VERSION ""

NS_ :

BS_:

BU_:

BO_ 2364704766 HVESP14MS1: 8 Vector__XXX
 SG_ Hvesp14Module1OperationalStatus : 0|2@1+ (1,0) [0|3] "" Vector__XXX
 SG_ Hvesp14Module2OperationalStatus : 2|2@1+ (1,0) [0|3] "" Vector__XXX
 SG_ Hvesp14Module3OperationalStatus : 4|2@1+ (1,0) [0|3] "" Vector__XXX
 SG_ Hvesp14Module4OperationalStatus : 6|2@1+ (1,0) [0|3] "" Vector__XXX
 SG_ Hvesp14Module5OperationalStatus : 8|2@1+ (1,0) [0|3] "" Vector__XXX
 SG_ Hvesp14Module6OperationalStatus : 10|2@1+ (1,0) [0|3] "" Vector__XXX
 SG_ Hvesp14Module7OperationalStatus : 12|2@1+ (1,0) [0|3] "" Vector__XXX
 SG_ Hvesp14Module8OperationalStatus : 14|2@1+ (1,0) [0|3] "" Vector__XXX
 SG_ Hvesp14Module9OperationalStatus : 16|2@1+ (1,0) [0|3] "" Vector__XXX
 SG_ Hvsp14Mdl10OprtnlStts : 18|2@1+ (1,0) [0|3] "" Vector__XXX
 SG_ Hvsp14Mdl11OprtnlStts : 20|2@1+ (1,0) [0|3] "" Vector__XXX
 SG_ Hvsp14Mdl12OprtnlStts : 22|2@1+ (1,0) [0|3] "" Vector__XXX
 SG_ Hvsp14Mdl13OprtnlStts : 24|2@1+ (1,0) [0|3] "" Vector__XXX
 SG_ Hvsp14Mdl14OprtnlStts : 26|2@1+ (1,0) [0|3] "" Vector__XXX
 SG_ Hvsp14Mdl15OprtnlStts : 28|2@1+ (1,0) [0|3] "" Vector__XXX
 SG_ Hvsp14Mdl16OprtnlStts : 30|2@1+ (1,0) [0|3] "" Vector__XXX
 SG_ Hvsp14Mdl17OprtnlStts : 32|2@1+ (1,0) [0|3] "" Vector__XXX
 SG_ Hvsp14Mdl18OprtnlStts : 34|2@1+ (1,0) [0|3] "" Vector__XXX
 SG_ Hvsp14Mdl19OprtnlStts : 36|2@1+ (1,0) [0|3] "" Vector__XXX
 SG_ Hvsp14Mdl20OprtnlStts : 38|2@1+ (1,0) [0|3] "" Vector__XXX
 SG_ Hvsp14Mdl21OprtnlStts : 40|2@1+ (1,0) [0|3] "" Vector__XXX
 SG_ Hvsp14Mdl22OprtnlStts : 42|2@1+ (1,0) [0|3] "" Vector__XXX
 SG_ Hvsp14Mdl23OprtnlStts : 44|2@1+ (1,0) [0|3] "" Vector__XXX
 SG_ Hvsp14Mdl24OprtnlStts : 46|2@1+ (1,0) [0|3] "" Vector__XXX
 SG_ Hvsp14Mdl25OprtnlStts : 48|2@1+ (1,0) [0|3] "" Vector__XXX
 SG_ Hvsp14Mdl26OprtnlStts : 50|2@1+ (1,0) [0|3] "" Vector__XXX
 SG_ Hvsp14Mdl27OprtnlStts : 52|2@1+ (1,0) [0|3] "" Vector__XXX
 SG_ Hvsp14Mdl28OprtnlStts : 54|2@1+ (1,0) [0|3] "" Vector__XXX
 SG_ Hvsp14Mdl29OprtnlStts : 56|2@1+ (1,0) [0|3] "" Vector__XXX
 SG_ Hvsp14Mdl30OprtnlStts : 58|2@1+ (1,0) [0|3] "" Vector__XXX
 SG_ Hvsp14Mdl31OprtnlStts : 60|2@1+ (1,0) [0|3] "" Vector__XXX
 SG_ Hvsp14Mdl32OprtnlStts : 62|2@1+ (1,0) [0|3] "" Vector__XXX

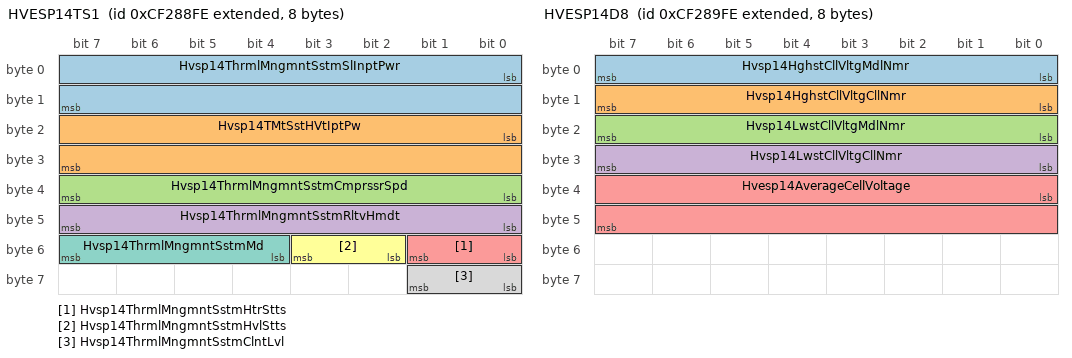
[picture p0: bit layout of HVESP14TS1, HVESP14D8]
BO_ 2364705022 HVESP14TS1: 8 Vector__XXX
 SG_ Hvsp14ThrmlMngmntSstmSlInptPwr : 0|16@1+ (0.5,0) [0|32127.5] "W" Vector__XXX
 SG_ Hvsp14TMtSstHVtIptPw : 16|16@1+ (0.5,0) [0|32127.5] "W" Vector__XXX
 SG_ Hvsp14ThrmlMngmntSstmCmprssrSpd : 32|8@1+ (32,0) [0|8000] "rpm" Vector__XXX
 SG_ Hvsp14ThrmlMngmntSstmRltvHmdt : 40|8@1+ (0.4,0) [0|100] "%" Vector__XXX
 SG_ Hvsp14ThrmlMngmntSstmHtrStts : 48|2@1+ (1,0) [0|3] "" Vector__XXX
 SG_ Hvsp14ThrmlMngmntSstmHvlStts : 50|2@1+ (1,0) [0|3] "" Vector__XXX
 SG_ Hvsp14ThrmlMngmntSstmMd : 52|4@1+ (1,0) [0|15] "" Vector__XXX
 SG_ Hvsp14ThrmlMngmntSstmClntLvl : 56|2@1+ (1,0) [0|3] "" Vector__XXX

BO_ 2364705278 HVESP14D8: 8 Vector__XXX
 SG_ Hvsp14HghstCllVltgMdlNmr : 0|8@1+ (1,0) [0|250] "count" Vector__XXX
 SG_ Hvsp14HghstCllVltgCllNmr : 8|8@1+ (1,0) [0|250] "count" Vector__XXX
 SG_ Hvsp14LwstCllVltgMdlNmr : 16|8@1+ (1,0) [0|250] "count" Vector__XXX
 SG_ Hvsp14LwstCllVltgCllNmr : 24|8@1+ (1,0) [0|250] "count" Vector__XXX
 SG_ Hvesp14AverageCellVoltage : 32|16@1+ (0.001,0) [0|64.255] "V" Vector__XXX

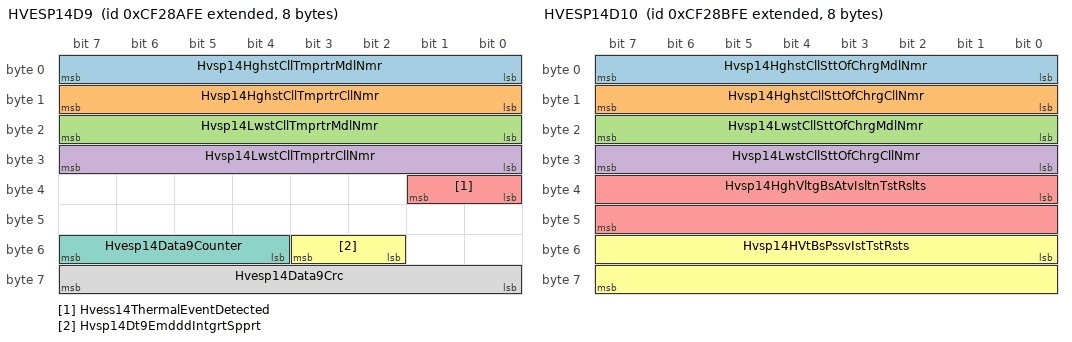
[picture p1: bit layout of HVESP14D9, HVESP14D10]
BO_ 2364705534 HVESP14D9: 8 Vector__XXX
 SG_ Hvsp14HghstCllTmprtrMdlNmr : 0|8@1+ (1,0) [0|250] "count" Vector__XXX
 SG_ Hvsp14HghstCllTmprtrCllNmr : 8|8@1+ (1,0) [0|250] "count" Vector__XXX
 SG_ Hvsp14LwstCllTmprtrMdlNmr : 16|8@1+ (1,0) [0|250] "count" Vector__XXX
 SG_ Hvsp14LwstCllTmprtrCllNmr : 24|8@1+ (1,0) [0|250] "count" Vector__XXX
 SG_ Hvess14ThermalEventDetected : 32|2@1+ (1,0) [0|3] "" Vector__XXX
 SG_ Hvsp14Dt9EmdddIntgrtSpprt : 50|2@1+ (1,0) [0|3] "" Vector__XXX
 SG_ Hvesp14Data9Counter : 52|4@1+ (1,0) [0|15] "" Vector__XXX
 SG_ Hvesp14Data9Crc : 56|8@1+ (1,0) [0|250] "count" Vector__XXX

BO_ 2364705790 HVESP14D10: 8 Vector__XXX
 SG_ Hvsp14HghstCllSttOfChrgMdlNmr : 0|8@1+ (1,0) [0|250] "count" Vector__XXX
 SG_ Hvsp14HghstCllSttOfChrgCllNmr : 8|8@1+ (1,0) [0|250] "count" Vector__XXX
 SG_ Hvsp14LwstCllSttOfChrgMdlNmr : 16|8@1+ (1,0) [0|250] "count" Vector__XXX
 SG_ Hvsp14LwstCllSttOfChrgCllNmr : 24|8@1+ (1,0) [0|250] "count" Vector__XXX
 SG_ Hvsp14HghVltgBsAtvIsltnTstRslts : 32|16@1+ (0.1,0) [0|6425.5] "OhmPerV" Vector__XXX
 SG_ Hvsp14HVtBsPssvIstTstRsts : 48|16@1+ (0.1,0) [0|6425.5] "OhmPerV" Vector__XXX

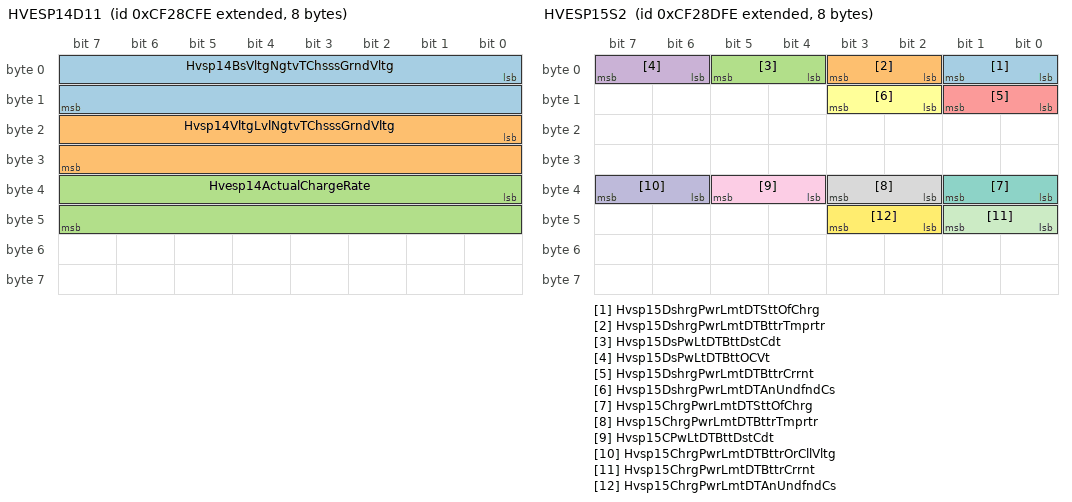
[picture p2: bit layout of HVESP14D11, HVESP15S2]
BO_ 2364706046 HVESP14D11: 8 Vector__XXX
 SG_ Hvsp14BsVltgNgtvTChsssGrndVltg : 0|16@1+ (0.05,0) [0|3212.75] "V" Vector__XXX
 SG_ Hvsp14VltgLvlNgtvTChsssGrndVltg : 16|16@1+ (0.05,0) [0|3212.75] "V" Vector__XXX
 SG_ Hvesp14ActualChargeRate : 32|16@1+ (0.05,0) [0|3212.75] "kW" Vector__XXX

BO_ 2364706302 HVESP15S2: 8 Vector__XXX
 SG_ Hvsp15DshrgPwrLmtDTSttOfChrg : 0|2@1+ (1,0) [0|3] "" Vector__XXX
 SG_ Hvsp15DshrgPwrLmtDTBttrTmprtr : 2|2@1+ (1,0) [0|3] "" Vector__XXX
 SG_ Hvsp15DsPwLtDTBttDstCdt : 4|2@1+ (1,0) [0|3] "" Vector__XXX
 SG_ Hvsp15DsPwLtDTBttOCVt : 6|2@1+ (1,0) [0|3] "" Vector__XXX
 SG_ Hvsp15DshrgPwrLmtDTBttrCrrnt : 8|2@1+ (1,0) [0|3] "" Vector__XXX
 SG_ Hvsp15DshrgPwrLmtDTAnUndfndCs : 10|2@1+ (1,0) [0|3] "" Vector__XXX
 SG_ Hvsp15ChrgPwrLmtDTSttOfChrg : 32|2@1+ (1,0) [0|3] "" Vector__XXX
 SG_ Hvsp15ChrgPwrLmtDTBttrTmprtr : 34|2@1+ (1,0) [0|3] "" Vector__XXX
 SG_ Hvsp15CPwLtDTBttDstCdt : 36|2@1+ (1,0) [0|3] "" Vector__XXX
 SG_ Hvsp15ChrgPwrLmtDTBttrOrCllVltg : 38|2@1+ (1,0) [0|3] "" Vector__XXX
 SG_ Hvsp15ChrgPwrLmtDTBttrCrrnt : 40|2@1+ (1,0) [0|3] "" Vector__XXX
 SG_ Hvsp15ChrgPwrLmtDTAnUndfndCs : 42|2@1+ (1,0) [0|3] "" Vector__XXX

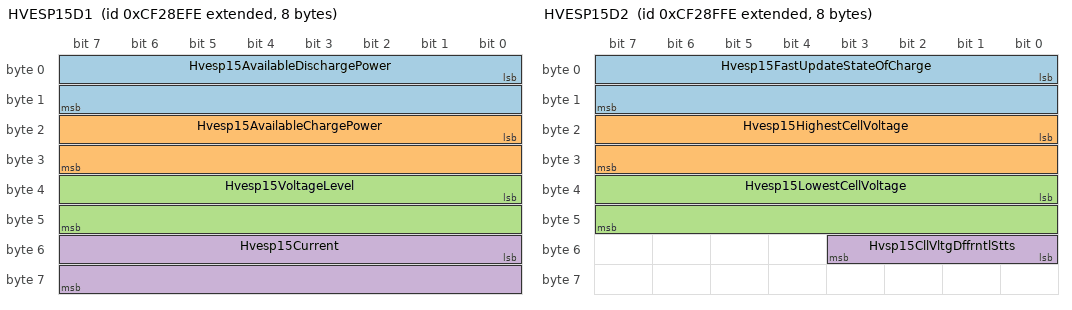
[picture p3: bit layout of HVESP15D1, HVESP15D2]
BO_ 2364706558 HVESP15D1: 8 Vector__XXX
 SG_ Hvesp15AvailableDischargePower : 0|16@1+ (0.05,0) [0|3212.75] "kW" Vector__XXX
 SG_ Hvesp15AvailableChargePower : 16|16@1+ (0.05,0) [0|3212.75] "kW" Vector__XXX
 SG_ Hvesp15VoltageLevel : 32|16@1+ (0.05,0) [0|3212.75] "V" Vector__XXX
 SG_ Hvesp15Current : 48|16@1+ (0.05,-1600) [-1600|1612.75] "A" Vector__XXX

BO_ 2364706814 HVESP15D2: 8 Vector__XXX
 SG_ Hvesp15FastUpdateStateOfCharge : 0|16@1+ (0.0015625,0) [0|100.3984375] "%" Vector__XXX
 SG_ Hvesp15HighestCellVoltage : 16|16@1+ (0.001,0) [0|64.255] "V" Vector__XXX
 SG_ Hvesp15LowestCellVoltage : 32|16@1+ (0.001,0) [0|64.255] "V" Vector__XXX
 SG_ Hvsp15CllVltgDffrntlStts : 48|4@1+ (1,0) [0|15] "" Vector__XXX

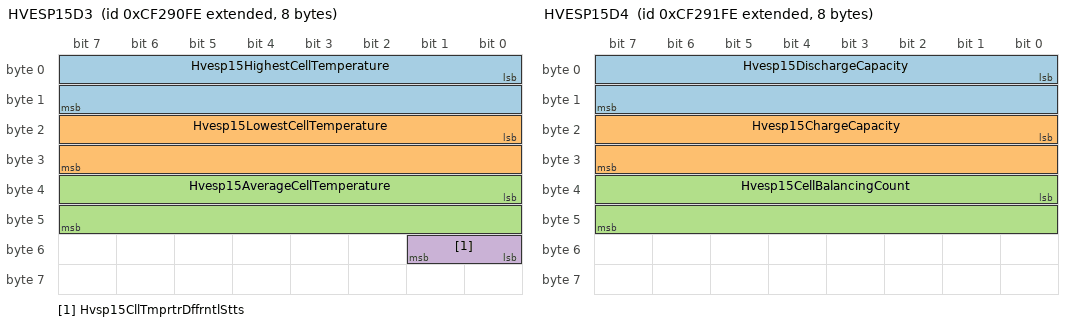
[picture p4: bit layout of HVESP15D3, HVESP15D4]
BO_ 2364707070 HVESP15D3: 8 Vector__XXX
 SG_ Hvesp15HighestCellTemperature : 0|16@1+ (0.03125,-273) [-273|1734.96875] "degC" Vector__XXX
 SG_ Hvesp15LowestCellTemperature : 16|16@1+ (0.03125,-273) [-273|1734.96875] "degC" Vector__XXX
 SG_ Hvesp15AverageCellTemperature : 32|16@1+ (0.03125,-273) [-273|1734.96875] "degC" Vector__XXX
 SG_ Hvsp15CllTmprtrDffrntlStts : 48|2@1+ (1,0) [0|3] "" Vector__XXX

BO_ 2364707326 HVESP15D4: 8 Vector__XXX
 SG_ Hvesp15DischargeCapacity : 0|16@1+ (0.01,0) [0|642.55] "Ah" Vector__XXX
 SG_ Hvesp15ChargeCapacity : 16|16@1+ (0.01,0) [0|642.55] "Ah" Vector__XXX
 SG_ Hvesp15CellBalancingCount : 32|16@1+ (1,0) [0|64255] "count" Vector__XXX

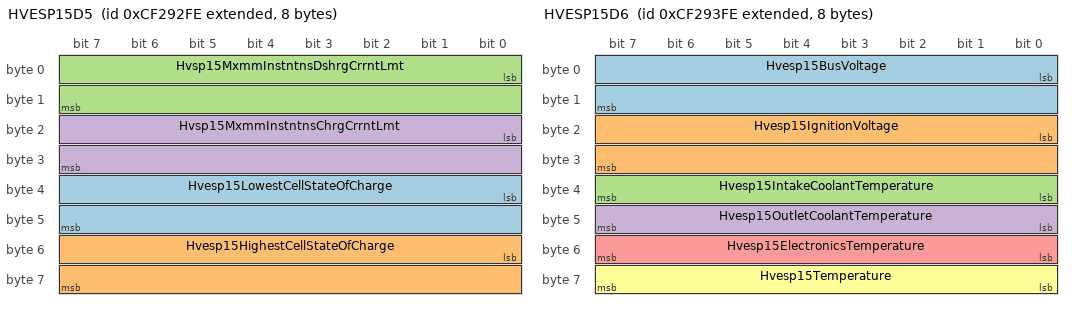
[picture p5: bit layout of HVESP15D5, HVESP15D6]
BO_ 2364707582 HVESP15D5: 8 Vector__XXX
 SG_ Hvesp15LowestCellStateOfCharge : 32|16@1+ (0.0015625,0) [0|100.3984375] "%" Vector__XXX
 SG_ Hvesp15HighestCellStateOfCharge : 48|16@1+ (0.0015625,0) [0|100.3984375] "%" Vector__XXX
 SG_ Hvsp15MxmmInstntnsDshrgCrrntLmt : 0|16@1+ (0.05,-1600) [-1600|0] "A" Vector__XXX
 SG_ Hvsp15MxmmInstntnsChrgCrrntLmt : 16|16@1+ (0.05,-1600) [0|1612.75] "A" Vector__XXX

BO_ 2364707838 HVESP15D6: 8 Vector__XXX
 SG_ Hvesp15BusVoltage : 0|16@1+ (0.05,0) [0|3212.75] "V" Vector__XXX
 SG_ Hvesp15IgnitionVoltage : 16|16@1+ (0.01,0) [0|642.55] "V" Vector__XXX
 SG_ Hvesp15IntakeCoolantTemperature : 32|8@1+ (1,-40) [-40|210] "degC" Vector__XXX
 SG_ Hvesp15OutletCoolantTemperature : 40|8@1+ (1,-40) [-40|210] "degC" Vector__XXX
 SG_ Hvesp15ElectronicsTemperature : 48|8@1+ (1,-40) [-40|210] "degC" Vector__XXX
 SG_ Hvesp15Temperature : 56|8@1+ (1,-40) [-40|210] "degC" Vector__XXX

BO_ 2364708094 HVESP15S1: 8 Vector__XXX
 SG_ Hvsp15HghVltgBsPstvCnttrStt : 0|2@1+ (1,0) [0|3] "" Vector__XXX
 SG_ Hvsp15HghVltgBsNgtvCnttrStt : 2|2@1+ (1,0) [0|3] "" Vector__XXX
 SG_ Hvsp15HghVltgBsDsnntFrwrnng : 4|4@1+ (1,0) [0|15] "" Vector__XXX
 SG_ Hvsp15HghVltgBsPrChrgRlStt : 8|2@1+ (1,0) [0|3] "" Vector__XXX
 SG_ Hvsp15CntrOfPkCnttrStt : 10|2@1+ (1,0) [0|3] "" Vector__XXX
 SG_ Hvsp15HghVltgBsAtvIsltnTstStts : 12|4@1+ (1,0) [0|15] "" Vector__XXX
 SG_ Hvsp15HghVltgBsPssvIsltnTstStts : 16|4@1+ (1,0) [0|15] "" Vector__XXX
 SG_ Hvesp15HvilStatus : 20|2@1+ (1,0) [0|3] "" Vector__XXX
 SG_ Hvesp15InertiaSwitchStatus : 22|2@1+ (1,0) [0|3] "" Vector__XXX
 SG_ Hvesp15StateOfChargeStatus : 24|4@1+ (1,0) [0|15] "" Vector__XXX
 SG_ Hvesp15CellBalanceStatus : 28|2@1+ (1,0) [0|3] "" Vector__XXX
 SG_ Hvesp15CellBalancingActive : 30|2@1+ (1,0) [0|3] "" Vector__XXX
 SG_ Hvesp15InternalChargerStatus : 32|2@1+ (1,0) [0|3] "" Vector__XXX
 SG_ Hvsp15HghVltgBsCnntnStts : 40|4@1+ (1,0) [0|15] "" Vector__XXX
 SG_ Hvesp15OperationalStatus : 44|4@1+ (1,0) [0|15] "" Vector__XXX
 SG_ Hvesp15Status1Counter : 52|4@1+ (1,0) [0|15] "" Vector__XXX
 SG_ Hvesp15Status1Crc : 56|8@1+ (1,0) [0|250] "count" Vector__XXX

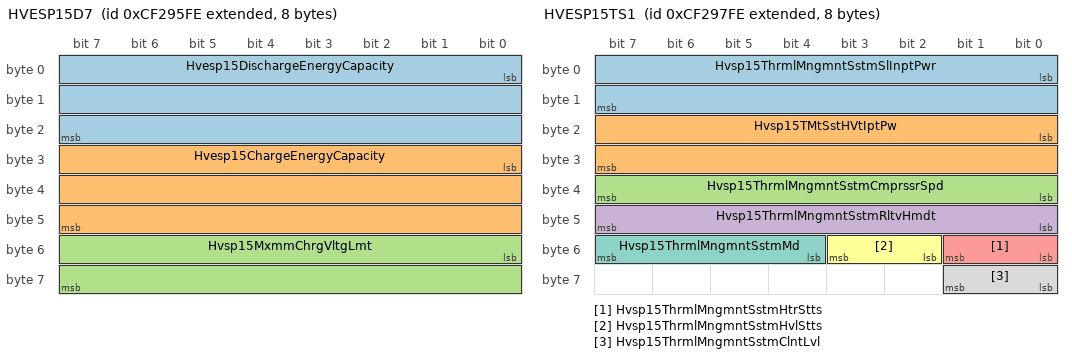
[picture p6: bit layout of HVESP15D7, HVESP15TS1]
BO_ 2364708350 HVESP15D7: 8 Vector__XXX
 SG_ Hvesp15DischargeEnergyCapacity : 0|24@1+ (0.001,0) [0|16449.535] "kWh" Vector__XXX
 SG_ Hvesp15ChargeEnergyCapacity : 24|24@1+ (0.001,0) [0|16449.535] "kWh" Vector__XXX
 SG_ Hvsp15MxmmChrgVltgLmt : 48|16@1+ (0.05,0) [0|3212.75] "V" Vector__XXX

BO_ 2364708606 HVESP15MS1: 8 Vector__XXX
 SG_ Hvesp15Module1OperationalStatus : 0|2@1+ (1,0) [0|3] "" Vector__XXX
 SG_ Hvesp15Module2OperationalStatus : 2|2@1+ (1,0) [0|3] "" Vector__XXX
 SG_ Hvesp15Module3OperationalStatus : 4|2@1+ (1,0) [0|3] "" Vector__XXX
 SG_ Hvesp15Module4OperationalStatus : 6|2@1+ (1,0) [0|3] "" Vector__XXX
 SG_ Hvesp15Module5OperationalStatus : 8|2@1+ (1,0) [0|3] "" Vector__XXX
 SG_ Hvesp15Module6OperationalStatus : 10|2@1+ (1,0) [0|3] "" Vector__XXX
 SG_ Hvesp15Module7OperationalStatus : 12|2@1+ (1,0) [0|3] "" Vector__XXX
 SG_ Hvesp15Module8OperationalStatus : 14|2@1+ (1,0) [0|3] "" Vector__XXX
 SG_ Hvesp15Module9OperationalStatus : 16|2@1+ (1,0) [0|3] "" Vector__XXX
 SG_ Hvsp15Mdl10OprtnlStts : 18|2@1+ (1,0) [0|3] "" Vector__XXX
 SG_ Hvsp15Mdl11OprtnlStts : 20|2@1+ (1,0) [0|3] "" Vector__XXX
 SG_ Hvsp15Mdl12OprtnlStts : 22|2@1+ (1,0) [0|3] "" Vector__XXX
 SG_ Hvsp15Mdl13OprtnlStts : 24|2@1+ (1,0) [0|3] "" Vector__XXX
 SG_ Hvsp15Mdl14OprtnlStts : 26|2@1+ (1,0) [0|3] "" Vector__XXX
 SG_ Hvsp15Mdl15OprtnlStts : 28|2@1+ (1,0) [0|3] "" Vector__XXX
 SG_ Hvsp15Mdl16OprtnlStts : 30|2@1+ (1,0) [0|3] "" Vector__XXX
 SG_ Hvsp15Mdl17OprtnlStts : 32|2@1+ (1,0) [0|3] "" Vector__XXX
 SG_ Hvsp15Mdl18OprtnlStts : 34|2@1+ (1,0) [0|3] "" Vector__XXX
 SG_ Hvsp15Mdl19OprtnlStts : 36|2@1+ (1,0) [0|3] "" Vector__XXX
 SG_ Hvsp15Mdl20OprtnlStts : 38|2@1+ (1,0) [0|3] "" Vector__XXX
 SG_ Hvsp15Mdl21OprtnlStts : 40|2@1+ (1,0) [0|3] "" Vector__XXX
 SG_ Hvsp15Mdl22OprtnlStts : 42|2@1+ (1,0) [0|3] "" Vector__XXX
 SG_ Hvsp15Mdl23OprtnlStts : 44|2@1+ (1,0) [0|3] "" Vector__XXX
 SG_ Hvsp15Mdl24OprtnlStts : 46|2@1+ (1,0) [0|3] "" Vector__XXX
 SG_ Hvsp15Mdl25OprtnlStts : 48|2@1+ (1,0) [0|3] "" Vector__XXX
 SG_ Hvsp15Mdl26OprtnlStts : 50|2@1+ (1,0) [0|3] "" Vector__XXX
 SG_ Hvsp15Mdl27OprtnlStts : 52|2@1+ (1,0) [0|3] "" Vector__XXX
 SG_ Hvsp15Mdl28OprtnlStts : 54|2@1+ (1,0) [0|3] "" Vector__XXX
 SG_ Hvsp15Mdl29OprtnlStts : 56|2@1+ (1,0) [0|3] "" Vector__XXX
 SG_ Hvsp15Mdl30OprtnlStts : 58|2@1+ (1,0) [0|3] "" Vector__XXX
 SG_ Hvsp15Mdl31OprtnlStts : 60|2@1+ (1,0) [0|3] "" Vector__XXX
 SG_ Hvsp15Mdl32OprtnlStts : 62|2@1+ (1,0) [0|3] "" Vector__XXX

BO_ 2364708862 HVESP15TS1: 8 Vector__XXX
 SG_ Hvsp15ThrmlMngmntSstmSlInptPwr : 0|16@1+ (0.5,0) [0|32127.5] "W" Vector__XXX
 SG_ Hvsp15TMtSstHVtIptPw : 16|16@1+ (0.5,0) [0|32127.5] "W" Vector__XXX
 SG_ Hvsp15ThrmlMngmntSstmCmprssrSpd : 32|8@1+ (32,0) [0|8000] "rpm" Vector__XXX
 SG_ Hvsp15ThrmlMngmntSstmRltvHmdt : 40|8@1+ (0.4,0) [0|100] "%" Vector__XXX
 SG_ Hvsp15ThrmlMngmntSstmHtrStts : 48|2@1+ (1,0) [0|3] "" Vector__XXX
 SG_ Hvsp15ThrmlMngmntSstmHvlStts : 50|2@1+ (1,0) [0|3] "" Vector__XXX
 SG_ Hvsp15ThrmlMngmntSstmMd : 52|4@1+ (1,0) [0|15] "" Vector__XXX
 SG_ Hvsp15ThrmlMngmntSstmClntLvl : 56|2@1+ (1,0) [0|3] "" Vector__XXX

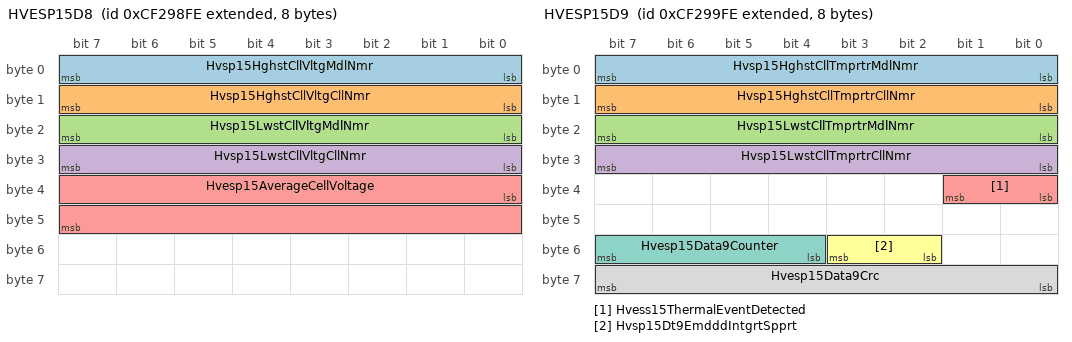
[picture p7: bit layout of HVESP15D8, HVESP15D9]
BO_ 2364709118 HVESP15D8: 8 Vector__XXX
 SG_ Hvsp15HghstCllVltgMdlNmr : 0|8@1+ (1,0) [0|250] "count" Vector__XXX
 SG_ Hvsp15HghstCllVltgCllNmr : 8|8@1+ (1,0) [0|250] "count" Vector__XXX
 SG_ Hvsp15LwstCllVltgMdlNmr : 16|8@1+ (1,0) [0|250] "count" Vector__XXX
 SG_ Hvsp15LwstCllVltgCllNmr : 24|8@1+ (1,0) [0|250] "count" Vector__XXX
 SG_ Hvesp15AverageCellVoltage : 32|16@1+ (0.001,0) [0|64.255] "V" Vector__XXX

BO_ 2364709374 HVESP15D9: 8 Vector__XXX
 SG_ Hvsp15HghstCllTmprtrMdlNmr : 0|8@1+ (1,0) [0|250] "count" Vector__XXX
 SG_ Hvsp15HghstCllTmprtrCllNmr : 8|8@1+ (1,0) [0|250] "count" Vector__XXX
 SG_ Hvsp15LwstCllTmprtrMdlNmr : 16|8@1+ (1,0) [0|250] "count" Vector__XXX
 SG_ Hvsp15LwstCllTmprtrCllNmr : 24|8@1+ (1,0) [0|250] "count" Vector__XXX
 SG_ Hvess15ThermalEventDetected : 32|2@1+ (1,0) [0|3] "" Vector__XXX
 SG_ Hvsp15Dt9EmdddIntgrtSpprt : 50|2@1+ (1,0) [0|3] "" Vector__XXX
 SG_ Hvesp15Data9Counter : 52|4@1+ (1,0) [0|15] "" Vector__XXX
 SG_ Hvesp15Data9Crc : 56|8@1+ (1,0) [0|250] "count" Vector__XXX

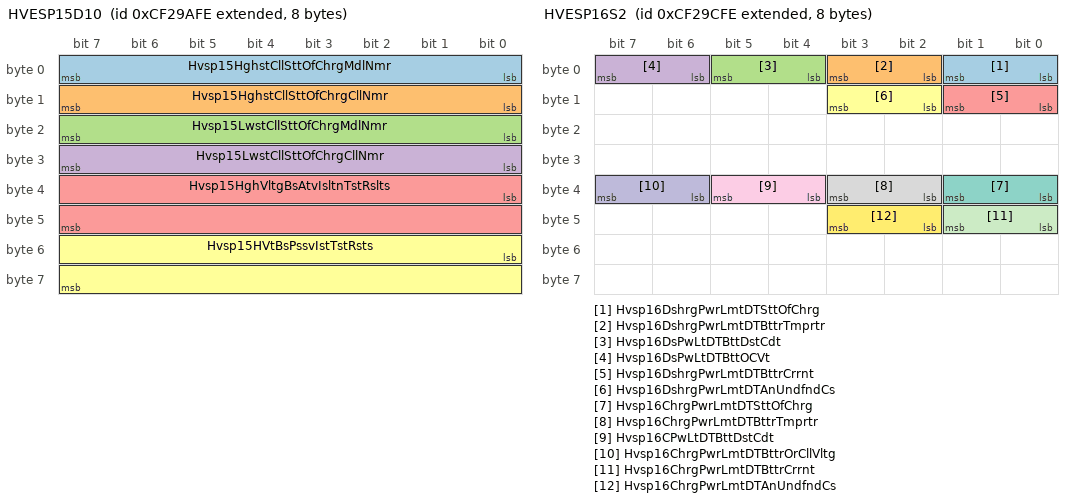
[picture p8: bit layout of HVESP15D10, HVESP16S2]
BO_ 2364709630 HVESP15D10: 8 Vector__XXX
 SG_ Hvsp15HghstCllSttOfChrgMdlNmr : 0|8@1+ (1,0) [0|250] "count" Vector__XXX
 SG_ Hvsp15HghstCllSttOfChrgCllNmr : 8|8@1+ (1,0) [0|250] "count" Vector__XXX
 SG_ Hvsp15LwstCllSttOfChrgMdlNmr : 16|8@1+ (1,0) [0|250] "count" Vector__XXX
 SG_ Hvsp15LwstCllSttOfChrgCllNmr : 24|8@1+ (1,0) [0|250] "count" Vector__XXX
 SG_ Hvsp15HghVltgBsAtvIsltnTstRslts : 32|16@1+ (0.1,0) [0|6425.5] "OhmPerV" Vector__XXX
 SG_ Hvsp15HVtBsPssvIstTstRsts : 48|16@1+ (0.1,0) [0|6425.5] "OhmPerV" Vector__XXX

BO_ 2364709886 HVESP15D11: 8 Vector__XXX
 SG_ Hvsp15BsVltgNgtvTChsssGrndVltg : 0|16@1+ (0.05,0) [0|3212.75] "V" Vector__XXX
 SG_ Hvsp15VltgLvlNgtvTChsssGrndVltg : 16|16@1+ (0.05,0) [0|3212.75] "V" Vector__XXX
 SG_ Hvesp15ActualChargeRate : 32|16@1+ (0.05,0) [0|3212.75] "kW" Vector__XXX

BO_ 2364710142 HVESP16S2: 8 Vector__XXX
 SG_ Hvsp16DshrgPwrLmtDTSttOfChrg : 0|2@1+ (1,0) [0|3] "" Vector__XXX
 SG_ Hvsp16DshrgPwrLmtDTBttrTmprtr : 2|2@1+ (1,0) [0|3] "" Vector__XXX
 SG_ Hvsp16DsPwLtDTBttDstCdt : 4|2@1+ (1,0) [0|3] "" Vector__XXX
 SG_ Hvsp16DsPwLtDTBttOCVt : 6|2@1+ (1,0) [0|3] "" Vector__XXX
 SG_ Hvsp16DshrgPwrLmtDTBttrCrrnt : 8|2@1+ (1,0) [0|3] "" Vector__XXX
 SG_ Hvsp16DshrgPwrLmtDTAnUndfndCs : 10|2@1+ (1,0) [0|3] "" Vector__XXX
 SG_ Hvsp16ChrgPwrLmtDTSttOfChrg : 32|2@1+ (1,0) [0|3] "" Vector__XXX
 SG_ Hvsp16ChrgPwrLmtDTBttrTmprtr : 34|2@1+ (1,0) [0|3] "" Vector__XXX
 SG_ Hvsp16CPwLtDTBttDstCdt : 36|2@1+ (1,0) [0|3] "" Vector__XXX
 SG_ Hvsp16ChrgPwrLmtDTBttrOrCllVltg : 38|2@1+ (1,0) [0|3] "" Vector__XXX
 SG_ Hvsp16ChrgPwrLmtDTBttrCrrnt : 40|2@1+ (1,0) [0|3] "" Vector__XXX
 SG_ Hvsp16ChrgPwrLmtDTAnUndfndCs : 42|2@1+ (1,0) [0|3] "" Vector__XXX

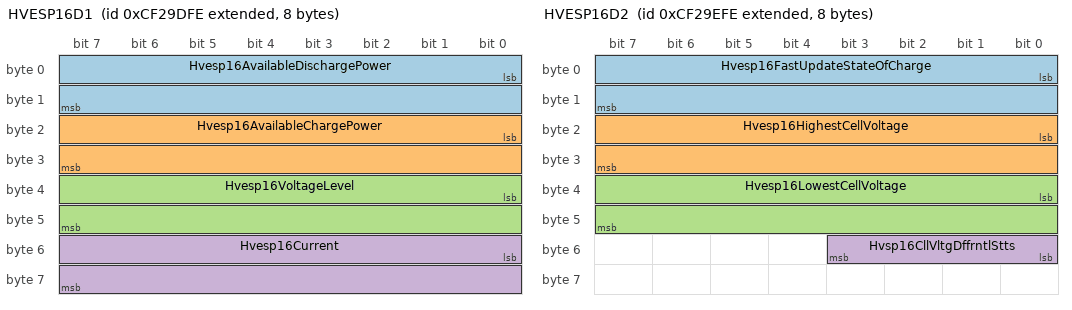
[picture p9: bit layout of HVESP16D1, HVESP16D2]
BO_ 2364710398 HVESP16D1: 8 Vector__XXX
 SG_ Hvesp16AvailableDischargePower : 0|16@1+ (0.05,0) [0|3212.75] "kW" Vector__XXX
 SG_ Hvesp16AvailableChargePower : 16|16@1+ (0.05,0) [0|3212.75] "kW" Vector__XXX
 SG_ Hvesp16VoltageLevel : 32|16@1+ (0.05,0) [0|3212.75] "V" Vector__XXX
 SG_ Hvesp16Current : 48|16@1+ (0.05,-1600) [-1600|1612.75] "A" Vector__XXX

BO_ 2364710654 HVESP16D2: 8 Vector__XXX
 SG_ Hvesp16FastUpdateStateOfCharge : 0|16@1+ (0.0015625,0) [0|100.3984375] "%" Vector__XXX
 SG_ Hvesp16HighestCellVoltage : 16|16@1+ (0.001,0) [0|64.255] "V" Vector__XXX
 SG_ Hvesp16LowestCellVoltage : 32|16@1+ (0.001,0) [0|64.255] "V" Vector__XXX
 SG_ Hvsp16CllVltgDffrntlStts : 48|4@1+ (1,0) [0|15] "" Vector__XXX

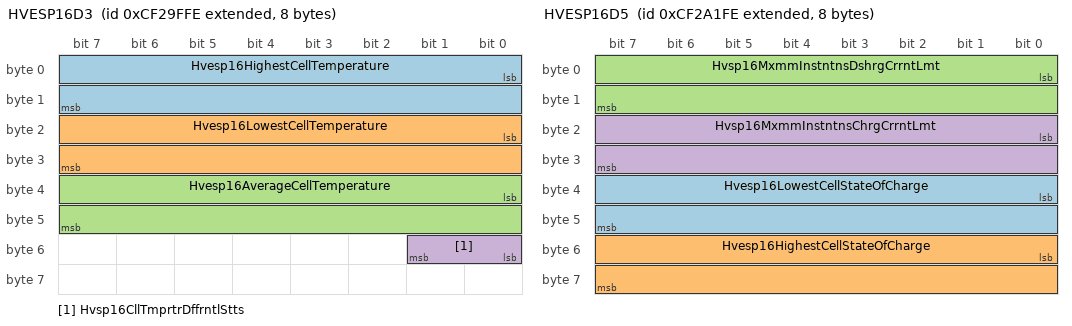
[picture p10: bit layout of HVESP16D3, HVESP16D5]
BO_ 2364710910 HVESP16D3: 8 Vector__XXX
 SG_ Hvesp16HighestCellTemperature : 0|16@1+ (0.03125,-273) [-273|1734.96875] "degC" Vector__XXX
 SG_ Hvesp16LowestCellTemperature : 16|16@1+ (0.03125,-273) [-273|1734.96875] "degC" Vector__XXX
 SG_ Hvesp16AverageCellTemperature : 32|16@1+ (0.03125,-273) [-273|1734.96875] "degC" Vector__XXX
 SG_ Hvsp16CllTmprtrDffrntlStts : 48|2@1+ (1,0) [0|3] "" Vector__XXX

BO_ 2364711166 HVESP16D4: 8 Vector__XXX
 SG_ Hvesp16DischargeCapacity : 0|16@1+ (0.01,0) [0|642.55] "Ah" Vector__XXX
 SG_ Hvesp16ChargeCapacity : 16|16@1+ (0.01,0) [0|642.55] "Ah" Vector__XXX
 SG_ Hvesp16CellBalancingCount : 32|16@1+ (1,0) [0|64255] "count" Vector__XXX

BO_ 2364711422 HVESP16D5: 8 Vector__XXX
 SG_ Hvesp16LowestCellStateOfCharge : 32|16@1+ (0.0015625,0) [0|100.3984375] "%" Vector__XXX
 SG_ Hvesp16HighestCellStateOfCharge : 48|16@1+ (0.0015625,0) [0|100.3984375] "%" Vector__XXX
 SG_ Hvsp16MxmmInstntnsDshrgCrrntLmt : 0|16@1+ (0.05,-1600) [-1600|0] "A" Vector__XXX
 SG_ Hvsp16MxmmInstntnsChrgCrrntLmt : 16|16@1+ (0.05,-1600) [0|1612.75] "A" Vector__XXX

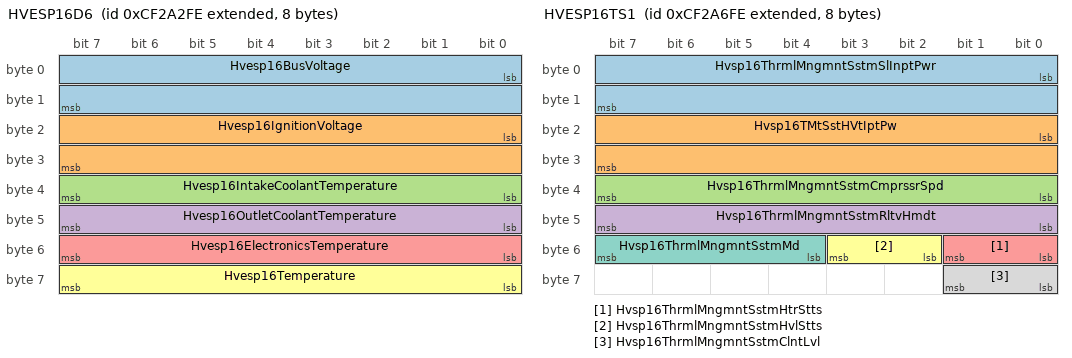
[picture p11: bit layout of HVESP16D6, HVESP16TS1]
BO_ 2364711678 HVESP16D6: 8 Vector__XXX
 SG_ Hvesp16BusVoltage : 0|16@1+ (0.05,0) [0|3212.75] "V" Vector__XXX
 SG_ Hvesp16IgnitionVoltage : 16|16@1+ (0.01,0) [0|642.55] "V" Vector__XXX
 SG_ Hvesp16IntakeCoolantTemperature : 32|8@1+ (1,-40) [-40|210] "degC" Vector__XXX
 SG_ Hvesp16OutletCoolantTemperature : 40|8@1+ (1,-40) [-40|210] "degC" Vector__XXX
 SG_ Hvesp16ElectronicsTemperature : 48|8@1+ (1,-40) [-40|210] "degC" Vector__XXX
 SG_ Hvesp16Temperature : 56|8@1+ (1,-40) [-40|210] "degC" Vector__XXX

BO_ 2364711934 HVESP16S1: 8 Vector__XXX
 SG_ Hvsp16HghVltgBsPstvCnttrStt : 0|2@1+ (1,0) [0|3] "" Vector__XXX
 SG_ Hvsp16HghVltgBsNgtvCnttrStt : 2|2@1+ (1,0) [0|3] "" Vector__XXX
 SG_ Hvsp16HghVltgBsDsnntFrwrnng : 4|4@1+ (1,0) [0|15] "" Vector__XXX
 SG_ Hvsp16HghVltgBsPrChrgRlStt : 8|2@1+ (1,0) [0|3] "" Vector__XXX
 SG_ Hvsp16CntrOfPkCnttrStt : 10|2@1+ (1,0) [0|3] "" Vector__XXX
 SG_ Hvsp16HghVltgBsAtvIsltnTstStts : 12|4@1+ (1,0) [0|15] "" Vector__XXX
 SG_ Hvsp16HghVltgBsPssvIsltnTstStts : 16|4@1+ (1,0) [0|15] "" Vector__XXX
 SG_ Hvesp16HvilStatus : 20|2@1+ (1,0) [0|3] "" Vector__XXX
 SG_ Hvesp16InertiaSwitchStatus : 22|2@1+ (1,0) [0|3] "" Vector__XXX
 SG_ Hvesp16StateOfChargeStatus : 24|4@1+ (1,0) [0|15] "" Vector__XXX
 SG_ Hvesp16CellBalanceStatus : 28|2@1+ (1,0) [0|3] "" Vector__XXX
 SG_ Hvesp16CellBalancingActive : 30|2@1+ (1,0) [0|3] "" Vector__XXX
 SG_ Hvesp16InternalChargerStatus : 32|2@1+ (1,0) [0|3] "" Vector__XXX
 SG_ Hvsp16HghVltgBsCnntnStts : 40|4@1+ (1,0) [0|15] "" Vector__XXX
 SG_ Hvesp16OperationalStatus : 44|4@1+ (1,0) [0|15] "" Vector__XXX
 SG_ Hvesp16Status1Counter : 52|4@1+ (1,0) [0|15] "" Vector__XXX
 SG_ Hvesp16Status1Crc : 56|8@1+ (1,0) [0|250] "count" Vector__XXX

BO_ 2364712190 HVESP16D7: 8 Vector__XXX
 SG_ Hvesp16DischargeEnergyCapacity : 0|24@1+ (0.001,0) [0|16449.535] "kWh" Vector__XXX
 SG_ Hvesp16ChargeEnergyCapacity : 24|24@1+ (0.001,0) [0|16449.535] "kWh" Vector__XXX
 SG_ Hvsp16MxmmChrgVltgLmt : 48|16@1+ (0.05,0) [0|3212.75] "V" Vector__XXX

BO_ 2364712446 HVESP16MS1: 8 Vector__XXX
 SG_ Hvesp16Module1OperationalStatus : 0|2@1+ (1,0) [0|3] "" Vector__XXX
 SG_ Hvesp16Module2OperationalStatus : 2|2@1+ (1,0) [0|3] "" Vector__XXX
 SG_ Hvesp16Module3OperationalStatus : 4|2@1+ (1,0) [0|3] "" Vector__XXX
 SG_ Hvesp16Module4OperationalStatus : 6|2@1+ (1,0) [0|3] "" Vector__XXX
 SG_ Hvesp16Module5OperationalStatus : 8|2@1+ (1,0) [0|3] "" Vector__XXX
 SG_ Hvesp16Module6OperationalStatus : 10|2@1+ (1,0) [0|3] "" Vector__XXX
 SG_ Hvesp16Module7OperationalStatus : 12|2@1+ (1,0) [0|3] "" Vector__XXX
 SG_ Hvesp16Module8OperationalStatus : 14|2@1+ (1,0) [0|3] "" Vector__XXX
 SG_ Hvesp16Module9OperationalStatus : 16|2@1+ (1,0) [0|3] "" Vector__XXX
 SG_ Hvsp16Mdl10OprtnlStts : 18|2@1+ (1,0) [0|3] "" Vector__XXX
 SG_ Hvsp16Mdl11OprtnlStts : 20|2@1+ (1,0) [0|3] "" Vector__XXX
 SG_ Hvsp16Mdl12OprtnlStts : 22|2@1+ (1,0) [0|3] "" Vector__XXX
 SG_ Hvsp16Mdl13OprtnlStts : 24|2@1+ (1,0) [0|3] "" Vector__XXX
 SG_ Hvsp16Mdl14OprtnlStts : 26|2@1+ (1,0) [0|3] "" Vector__XXX
 SG_ Hvsp16Mdl15OprtnlStts : 28|2@1+ (1,0) [0|3] "" Vector__XXX
 SG_ Hvsp16Mdl16OprtnlStts : 30|2@1+ (1,0) [0|3] "" Vector__XXX
 SG_ Hvsp16Mdl17OprtnlStts : 32|2@1+ (1,0) [0|3] "" Vector__XXX
 SG_ Hvsp16Mdl18OprtnlStts : 34|2@1+ (1,0) [0|3] "" Vector__XXX
 SG_ Hvsp16Mdl19OprtnlStts : 36|2@1+ (1,0) [0|3] "" Vector__XXX
 SG_ Hvsp16Mdl20OprtnlStts : 38|2@1+ (1,0) [0|3] "" Vector__XXX
 SG_ Hvsp16Mdl21OprtnlStts : 40|2@1+ (1,0) [0|3] "" Vector__XXX
 SG_ Hvsp16Mdl22OprtnlStts : 42|2@1+ (1,0) [0|3] "" Vector__XXX
 SG_ Hvsp16Mdl23OprtnlStts : 44|2@1+ (1,0) [0|3] "" Vector__XXX
 SG_ Hvsp16Mdl24OprtnlStts : 46|2@1+ (1,0) [0|3] "" Vector__XXX
 SG_ Hvsp16Mdl25OprtnlStts : 48|2@1+ (1,0) [0|3] "" Vector__XXX
 SG_ Hvsp16Mdl26OprtnlStts : 50|2@1+ (1,0) [0|3] "" Vector__XXX
 SG_ Hvsp16Mdl27OprtnlStts : 52|2@1+ (1,0) [0|3] "" Vector__XXX
 SG_ Hvsp16Mdl28OprtnlStts : 54|2@1+ (1,0) [0|3] "" Vector__XXX
 SG_ Hvsp16Mdl29OprtnlStts : 56|2@1+ (1,0) [0|3] "" Vector__XXX
 SG_ Hvsp16Mdl30OprtnlStts : 58|2@1+ (1,0) [0|3] "" Vector__XXX
 SG_ Hvsp16Mdl31OprtnlStts : 60|2@1+ (1,0) [0|3] "" Vector__XXX
 SG_ Hvsp16Mdl32OprtnlStts : 62|2@1+ (1,0) [0|3] "" Vector__XXX

BO_ 2364712702 HVESP16TS1: 8 Vector__XXX
 SG_ Hvsp16ThrmlMngmntSstmSlInptPwr : 0|16@1+ (0.5,0) [0|32127.5] "W" Vector__XXX
 SG_ Hvsp16TMtSstHVtIptPw : 16|16@1+ (0.5,0) [0|32127.5] "W" Vector__XXX
 SG_ Hvsp16ThrmlMngmntSstmCmprssrSpd : 32|8@1+ (32,0) [0|8000] "rpm" Vector__XXX
 SG_ Hvsp16ThrmlMngmntSstmRltvHmdt : 40|8@1+ (0.4,0) [0|100] "%" Vector__XXX
 SG_ Hvsp16ThrmlMngmntSstmHtrStts : 48|2@1+ (1,0) [0|3] "" Vector__XXX
 SG_ Hvsp16ThrmlMngmntSstmHvlStts : 50|2@1+ (1,0) [0|3] "" Vector__XXX
 SG_ Hvsp16ThrmlMngmntSstmMd : 52|4@1+ (1,0) [0|15] "" Vector__XXX
 SG_ Hvsp16ThrmlMngmntSstmClntLvl : 56|2@1+ (1,0) [0|3] "" Vector__XXX

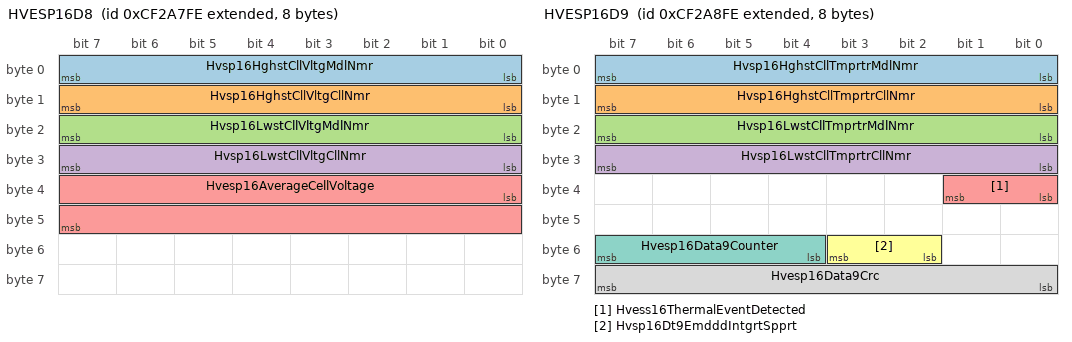
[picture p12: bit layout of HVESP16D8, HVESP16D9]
BO_ 2364712958 HVESP16D8: 8 Vector__XXX
 SG_ Hvsp16HghstCllVltgMdlNmr : 0|8@1+ (1,0) [0|250] "count" Vector__XXX
 SG_ Hvsp16HghstCllVltgCllNmr : 8|8@1+ (1,0) [0|250] "count" Vector__XXX
 SG_ Hvsp16LwstCllVltgMdlNmr : 16|8@1+ (1,0) [0|250] "count" Vector__XXX
 SG_ Hvsp16LwstCllVltgCllNmr : 24|8@1+ (1,0) [0|250] "count" Vector__XXX
 SG_ Hvesp16AverageCellVoltage : 32|16@1+ (0.001,0) [0|64.255] "V" Vector__XXX

BO_ 2364713214 HVESP16D9: 8 Vector__XXX
 SG_ Hvsp16HghstCllTmprtrMdlNmr : 0|8@1+ (1,0) [0|250] "count" Vector__XXX
 SG_ Hvsp16HghstCllTmprtrCllNmr : 8|8@1+ (1,0) [0|250] "count" Vector__XXX
 SG_ Hvsp16LwstCllTmprtrMdlNmr : 16|8@1+ (1,0) [0|250] "count" Vector__XXX
 SG_ Hvsp16LwstCllTmprtrCllNmr : 24|8@1+ (1,0) [0|250] "count" Vector__XXX
 SG_ Hvess16ThermalEventDetected : 32|2@1+ (1,0) [0|3] "" Vector__XXX
 SG_ Hvsp16Dt9EmdddIntgrtSpprt : 50|2@1+ (1,0) [0|3] "" Vector__XXX
 SG_ Hvesp16Data9Counter : 52|4@1+ (1,0) [0|15] "" Vector__XXX
 SG_ Hvesp16Data9Crc : 56|8@1+ (1,0) [0|250] "count" Vector__XXX

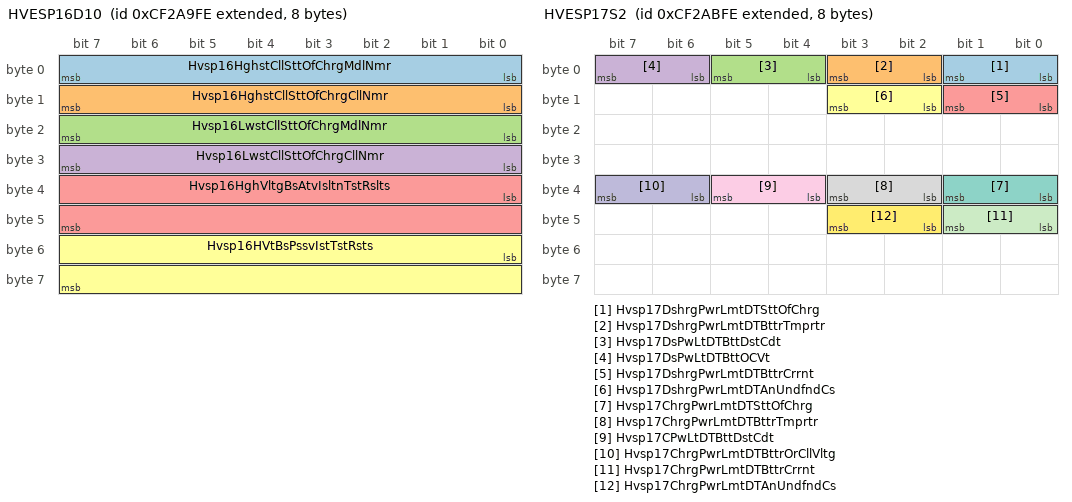
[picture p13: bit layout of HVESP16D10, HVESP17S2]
BO_ 2364713470 HVESP16D10: 8 Vector__XXX
 SG_ Hvsp16HghstCllSttOfChrgMdlNmr : 0|8@1+ (1,0) [0|250] "count" Vector__XXX
 SG_ Hvsp16HghstCllSttOfChrgCllNmr : 8|8@1+ (1,0) [0|250] "count" Vector__XXX
 SG_ Hvsp16LwstCllSttOfChrgMdlNmr : 16|8@1+ (1,0) [0|250] "count" Vector__XXX
 SG_ Hvsp16LwstCllSttOfChrgCllNmr : 24|8@1+ (1,0) [0|250] "count" Vector__XXX
 SG_ Hvsp16HghVltgBsAtvIsltnTstRslts : 32|16@1+ (0.1,0) [0|6425.5] "OhmPerV" Vector__XXX
 SG_ Hvsp16HVtBsPssvIstTstRsts : 48|16@1+ (0.1,0) [0|6425.5] "OhmPerV" Vector__XXX

BO_ 2364713726 HVESP16D11: 8 Vector__XXX
 SG_ Hvsp16BsVltgNgtvTChsssGrndVltg : 0|16@1+ (0.05,0) [0|3212.75] "V" Vector__XXX
 SG_ Hvsp16VltgLvlNgtvTChsssGrndVltg : 16|16@1+ (0.05,0) [0|3212.75] "V" Vector__XXX
 SG_ Hvesp16ActualChargeRate : 32|16@1+ (0.05,0) [0|3212.75] "kW" Vector__XXX

BO_ 2364713982 HVESP17S2: 8 Vector__XXX
 SG_ Hvsp17DshrgPwrLmtDTSttOfChrg : 0|2@1+ (1,0) [0|3] "" Vector__XXX
 SG_ Hvsp17DshrgPwrLmtDTBttrTmprtr : 2|2@1+ (1,0) [0|3] "" Vector__XXX
 SG_ Hvsp17DsPwLtDTBttDstCdt : 4|2@1+ (1,0) [0|3] "" Vector__XXX
 SG_ Hvsp17DsPwLtDTBttOCVt : 6|2@1+ (1,0) [0|3] "" Vector__XXX
 SG_ Hvsp17DshrgPwrLmtDTBttrCrrnt : 8|2@1+ (1,0) [0|3] "" Vector__XXX
 SG_ Hvsp17DshrgPwrLmtDTAnUndfndCs : 10|2@1+ (1,0) [0|3] "" Vector__XXX
 SG_ Hvsp17ChrgPwrLmtDTSttOfChrg : 32|2@1+ (1,0) [0|3] "" Vector__XXX
 SG_ Hvsp17ChrgPwrLmtDTBttrTmprtr : 34|2@1+ (1,0) [0|3] "" Vector__XXX
 SG_ Hvsp17CPwLtDTBttDstCdt : 36|2@1+ (1,0) [0|3] "" Vector__XXX
 SG_ Hvsp17ChrgPwrLmtDTBttrOrCllVltg : 38|2@1+ (1,0) [0|3] "" Vector__XXX
 SG_ Hvsp17ChrgPwrLmtDTBttrCrrnt : 40|2@1+ (1,0) [0|3] "" Vector__XXX
 SG_ Hvsp17ChrgPwrLmtDTAnUndfndCs : 42|2@1+ (1,0) [0|3] "" Vector__XXX

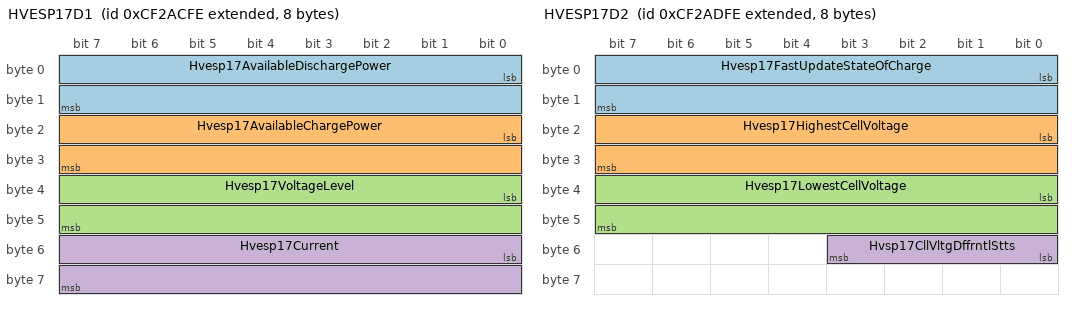
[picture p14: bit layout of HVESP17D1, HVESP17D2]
BO_ 2364714238 HVESP17D1: 8 Vector__XXX
 SG_ Hvesp17AvailableDischargePower : 0|16@1+ (0.05,0) [0|3212.75] "kW" Vector__XXX
 SG_ Hvesp17AvailableChargePower : 16|16@1+ (0.05,0) [0|3212.75] "kW" Vector__XXX
 SG_ Hvesp17VoltageLevel : 32|16@1+ (0.05,0) [0|3212.75] "V" Vector__XXX
 SG_ Hvesp17Current : 48|16@1+ (0.05,-1600) [-1600|1612.75] "A" Vector__XXX

BO_ 2364714494 HVESP17D2: 8 Vector__XXX
 SG_ Hvesp17FastUpdateStateOfCharge : 0|16@1+ (0.0015625,0) [0|100.3984375] "%" Vector__XXX
 SG_ Hvesp17HighestCellVoltage : 16|16@1+ (0.001,0) [0|64.255] "V" Vector__XXX
 SG_ Hvesp17LowestCellVoltage : 32|16@1+ (0.001,0) [0|64.255] "V" Vector__XXX
 SG_ Hvsp17CllVltgDffrntlStts : 48|4@1+ (1,0) [0|15] "" Vector__XXX

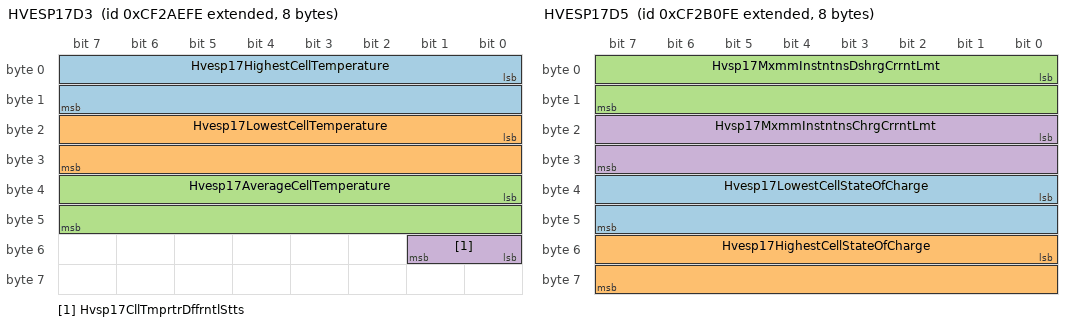
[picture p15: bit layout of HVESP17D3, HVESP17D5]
BO_ 2364714750 HVESP17D3: 8 Vector__XXX
 SG_ Hvesp17HighestCellTemperature : 0|16@1+ (0.03125,-273) [-273|1734.96875] "degC" Vector__XXX
 SG_ Hvesp17LowestCellTemperature : 16|16@1+ (0.03125,-273) [-273|1734.96875] "degC" Vector__XXX
 SG_ Hvesp17AverageCellTemperature : 32|16@1+ (0.03125,-273) [-273|1734.96875] "degC" Vector__XXX
 SG_ Hvsp17CllTmprtrDffrntlStts : 48|2@1+ (1,0) [0|3] "" Vector__XXX

BO_ 2364715006 HVESP17D4: 8 Vector__XXX
 SG_ Hvesp17DischargeCapacity : 0|16@1+ (0.01,0) [0|642.55] "Ah" Vector__XXX
 SG_ Hvesp17ChargeCapacity : 16|16@1+ (0.01,0) [0|642.55] "Ah" Vector__XXX
 SG_ Hvesp17CellBalancingCount : 32|16@1+ (1,0) [0|64255] "count" Vector__XXX

BO_ 2364715262 HVESP17D5: 8 Vector__XXX
 SG_ Hvesp17LowestCellStateOfCharge : 32|16@1+ (0.0015625,0) [0|100.3984375] "%" Vector__XXX
 SG_ Hvesp17HighestCellStateOfCharge : 48|16@1+ (0.0015625,0) [0|100.3984375] "%" Vector__XXX
 SG_ Hvsp17MxmmInstntnsDshrgCrrntLmt : 0|16@1+ (0.05,-1600) [-1600|0] "A" Vector__XXX
 SG_ Hvsp17MxmmInstntnsChrgCrrntLmt : 16|16@1+ (0.05,-1600) [0|1612.75] "A" Vector__XXX

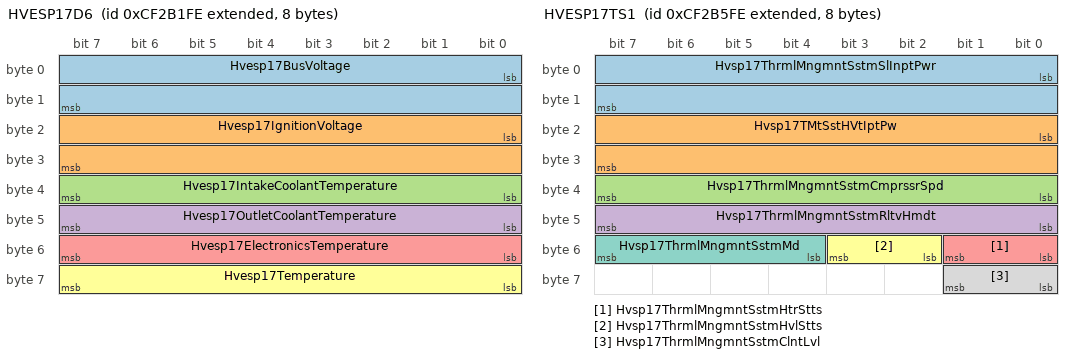
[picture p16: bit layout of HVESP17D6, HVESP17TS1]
BO_ 2364715518 HVESP17D6: 8 Vector__XXX
 SG_ Hvesp17BusVoltage : 0|16@1+ (0.05,0) [0|3212.75] "V" Vector__XXX
 SG_ Hvesp17IgnitionVoltage : 16|16@1+ (0.01,0) [0|642.55] "V" Vector__XXX
 SG_ Hvesp17IntakeCoolantTemperature : 32|8@1+ (1,-40) [-40|210] "degC" Vector__XXX
 SG_ Hvesp17OutletCoolantTemperature : 40|8@1+ (1,-40) [-40|210] "degC" Vector__XXX
 SG_ Hvesp17ElectronicsTemperature : 48|8@1+ (1,-40) [-40|210] "degC" Vector__XXX
 SG_ Hvesp17Temperature : 56|8@1+ (1,-40) [-40|210] "degC" Vector__XXX

BO_ 2364715774 HVESP17S1: 8 Vector__XXX
 SG_ Hvsp17HghVltgBsPstvCnttrStt : 0|2@1+ (1,0) [0|3] "" Vector__XXX
 SG_ Hvsp17HghVltgBsNgtvCnttrStt : 2|2@1+ (1,0) [0|3] "" Vector__XXX
 SG_ Hvsp17HghVltgBsDsnntFrwrnng : 4|4@1+ (1,0) [0|15] "" Vector__XXX
 SG_ Hvsp17HghVltgBsPrChrgRlStt : 8|2@1+ (1,0) [0|3] "" Vector__XXX
 SG_ Hvsp17CntrOfPkCnttrStt : 10|2@1+ (1,0) [0|3] "" Vector__XXX
 SG_ Hvsp17HghVltgBsAtvIsltnTstStts : 12|4@1+ (1,0) [0|15] "" Vector__XXX
 SG_ Hvsp17HghVltgBsPssvIsltnTstStts : 16|4@1+ (1,0) [0|15] "" Vector__XXX
 SG_ Hvesp17HvilStatus : 20|2@1+ (1,0) [0|3] "" Vector__XXX
 SG_ Hvesp17InertiaSwitchStatus : 22|2@1+ (1,0) [0|3] "" Vector__XXX
 SG_ Hvesp17StateOfChargeStatus : 24|4@1+ (1,0) [0|15] "" Vector__XXX
 SG_ Hvesp17CellBalanceStatus : 28|2@1+ (1,0) [0|3] "" Vector__XXX
 SG_ Hvesp17CellBalancingActive : 30|2@1+ (1,0) [0|3] "" Vector__XXX
 SG_ Hvesp17InternalChargerStatus : 32|2@1+ (1,0) [0|3] "" Vector__XXX
 SG_ Hvsp17HghVltgBsCnntnStts : 40|4@1+ (1,0) [0|15] "" Vector__XXX
 SG_ Hvesp17OperationalStatus : 44|4@1+ (1,0) [0|15] "" Vector__XXX
 SG_ Hvesp17Status1Counter : 52|4@1+ (1,0) [0|15] "" Vector__XXX
 SG_ Hvesp17Status1Crc : 56|8@1+ (1,0) [0|250] "count" Vector__XXX

BO_ 2364716030 HVESP17D7: 8 Vector__XXX
 SG_ Hvesp17DischargeEnergyCapacity : 0|24@1+ (0.001,0) [0|16449.535] "kWh" Vector__XXX
 SG_ Hvesp17ChargeEnergyCapacity : 24|24@1+ (0.001,0) [0|16449.535] "kWh" Vector__XXX
 SG_ Hvsp17MxmmChrgVltgLmt : 48|16@1+ (0.05,0) [0|3212.75] "V" Vector__XXX

BO_ 2364716286 HVESP17MS1: 8 Vector__XXX
 SG_ Hvesp17Module1OperationalStatus : 0|2@1+ (1,0) [0|3] "" Vector__XXX
 SG_ Hvesp17Module2OperationalStatus : 2|2@1+ (1,0) [0|3] "" Vector__XXX
 SG_ Hvesp17Module3OperationalStatus : 4|2@1+ (1,0) [0|3] "" Vector__XXX
 SG_ Hvesp17Module4OperationalStatus : 6|2@1+ (1,0) [0|3] "" Vector__XXX
 SG_ Hvesp17Module5OperationalStatus : 8|2@1+ (1,0) [0|3] "" Vector__XXX
 SG_ Hvesp17Module6OperationalStatus : 10|2@1+ (1,0) [0|3] "" Vector__XXX
 SG_ Hvesp17Module7OperationalStatus : 12|2@1+ (1,0) [0|3] "" Vector__XXX
 SG_ Hvesp17Module8OperationalStatus : 14|2@1+ (1,0) [0|3] "" Vector__XXX
 SG_ Hvesp17Module9OperationalStatus : 16|2@1+ (1,0) [0|3] "" Vector__XXX
 SG_ Hvsp17Mdl10OprtnlStts : 18|2@1+ (1,0) [0|3] "" Vector__XXX
 SG_ Hvsp17Mdl11OprtnlStts : 20|2@1+ (1,0) [0|3] "" Vector__XXX
 SG_ Hvsp17Mdl12OprtnlStts : 22|2@1+ (1,0) [0|3] "" Vector__XXX
 SG_ Hvsp17Mdl13OprtnlStts : 24|2@1+ (1,0) [0|3] "" Vector__XXX
 SG_ Hvsp17Mdl14OprtnlStts : 26|2@1+ (1,0) [0|3] "" Vector__XXX
 SG_ Hvsp17Mdl15OprtnlStts : 28|2@1+ (1,0) [0|3] "" Vector__XXX
 SG_ Hvsp17Mdl16OprtnlStts : 30|2@1+ (1,0) [0|3] "" Vector__XXX
 SG_ Hvsp17Mdl17OprtnlStts : 32|2@1+ (1,0) [0|3] "" Vector__XXX
 SG_ Hvsp17Mdl18OprtnlStts : 34|2@1+ (1,0) [0|3] "" Vector__XXX
 SG_ Hvsp17Mdl19OprtnlStts : 36|2@1+ (1,0) [0|3] "" Vector__XXX
 SG_ Hvsp17Mdl20OprtnlStts : 38|2@1+ (1,0) [0|3] "" Vector__XXX
 SG_ Hvsp17Mdl21OprtnlStts : 40|2@1+ (1,0) [0|3] "" Vector__XXX
 SG_ Hvsp17Mdl22OprtnlStts : 42|2@1+ (1,0) [0|3] "" Vector__XXX
 SG_ Hvsp17Mdl23OprtnlStts : 44|2@1+ (1,0) [0|3] "" Vector__XXX
 SG_ Hvsp17Mdl24OprtnlStts : 46|2@1+ (1,0) [0|3] "" Vector__XXX
 SG_ Hvsp17Mdl25OprtnlStts : 48|2@1+ (1,0) [0|3] "" Vector__XXX
 SG_ Hvsp17Mdl26OprtnlStts : 50|2@1+ (1,0) [0|3] "" Vector__XXX
 SG_ Hvsp17Mdl27OprtnlStts : 52|2@1+ (1,0) [0|3] "" Vector__XXX
 SG_ Hvsp17Mdl28OprtnlStts : 54|2@1+ (1,0) [0|3] "" Vector__XXX
 SG_ Hvsp17Mdl29OprtnlStts : 56|2@1+ (1,0) [0|3] "" Vector__XXX
 SG_ Hvsp17Mdl30OprtnlStts : 58|2@1+ (1,0) [0|3] "" Vector__XXX
 SG_ Hvsp17Mdl31OprtnlStts : 60|2@1+ (1,0) [0|3] "" Vector__XXX
 SG_ Hvsp17Mdl32OprtnlStts : 62|2@1+ (1,0) [0|3] "" Vector__XXX

BO_ 2364716542 HVESP17TS1: 8 Vector__XXX
 SG_ Hvsp17ThrmlMngmntSstmSlInptPwr : 0|16@1+ (0.5,0) [0|32127.5] "W" Vector__XXX
 SG_ Hvsp17TMtSstHVtIptPw : 16|16@1+ (0.5,0) [0|32127.5] "W" Vector__XXX
 SG_ Hvsp17ThrmlMngmntSstmCmprssrSpd : 32|8@1+ (32,0) [0|8000] "rpm" Vector__XXX
 SG_ Hvsp17ThrmlMngmntSstmRltvHmdt : 40|8@1+ (0.4,0) [0|100] "%" Vector__XXX
 SG_ Hvsp17ThrmlMngmntSstmHtrStts : 48|2@1+ (1,0) [0|3] "" Vector__XXX
 SG_ Hvsp17ThrmlMngmntSstmHvlStts : 50|2@1+ (1,0) [0|3] "" Vector__XXX
 SG_ Hvsp17ThrmlMngmntSstmMd : 52|4@1+ (1,0) [0|15] "" Vector__XXX
 SG_ Hvsp17ThrmlMngmntSstmClntLvl : 56|2@1+ (1,0) [0|3] "" Vector__XXX

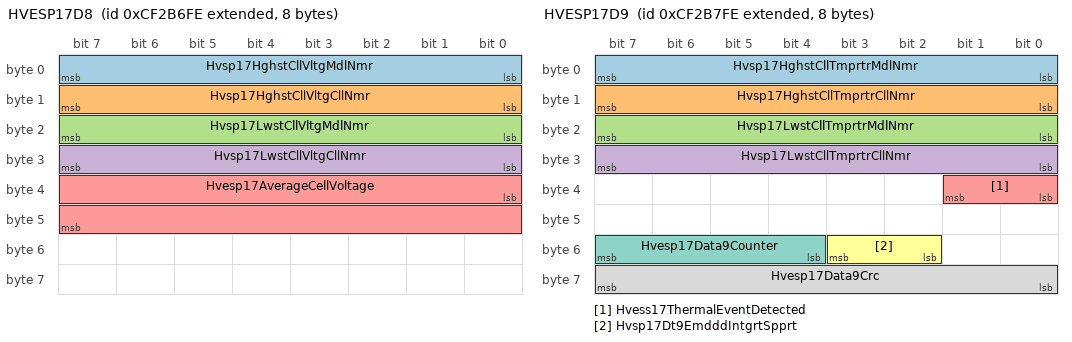
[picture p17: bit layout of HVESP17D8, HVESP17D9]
BO_ 2364716798 HVESP17D8: 8 Vector__XXX
 SG_ Hvsp17HghstCllVltgMdlNmr : 0|8@1+ (1,0) [0|250] "count" Vector__XXX
 SG_ Hvsp17HghstCllVltgCllNmr : 8|8@1+ (1,0) [0|250] "count" Vector__XXX
 SG_ Hvsp17LwstCllVltgMdlNmr : 16|8@1+ (1,0) [0|250] "count" Vector__XXX
 SG_ Hvsp17LwstCllVltgCllNmr : 24|8@1+ (1,0) [0|250] "count" Vector__XXX
 SG_ Hvesp17AverageCellVoltage : 32|16@1+ (0.001,0) [0|64.255] "V" Vector__XXX

BO_ 2364717054 HVESP17D9: 8 Vector__XXX
 SG_ Hvsp17HghstCllTmprtrMdlNmr : 0|8@1+ (1,0) [0|250] "count" Vector__XXX
 SG_ Hvsp17HghstCllTmprtrCllNmr : 8|8@1+ (1,0) [0|250] "count" Vector__XXX
 SG_ Hvsp17LwstCllTmprtrMdlNmr : 16|8@1+ (1,0) [0|250] "count" Vector__XXX
 SG_ Hvsp17LwstCllTmprtrCllNmr : 24|8@1+ (1,0) [0|250] "count" Vector__XXX
 SG_ Hvess17ThermalEventDetected : 32|2@1+ (1,0) [0|3] "" Vector__XXX
 SG_ Hvsp17Dt9EmdddIntgrtSpprt : 50|2@1+ (1,0) [0|3] "" Vector__XXX
 SG_ Hvesp17Data9Counter : 52|4@1+ (1,0) [0|15] "" Vector__XXX
 SG_ Hvesp17Data9Crc : 56|8@1+ (1,0) [0|250] "count" Vector__XXX

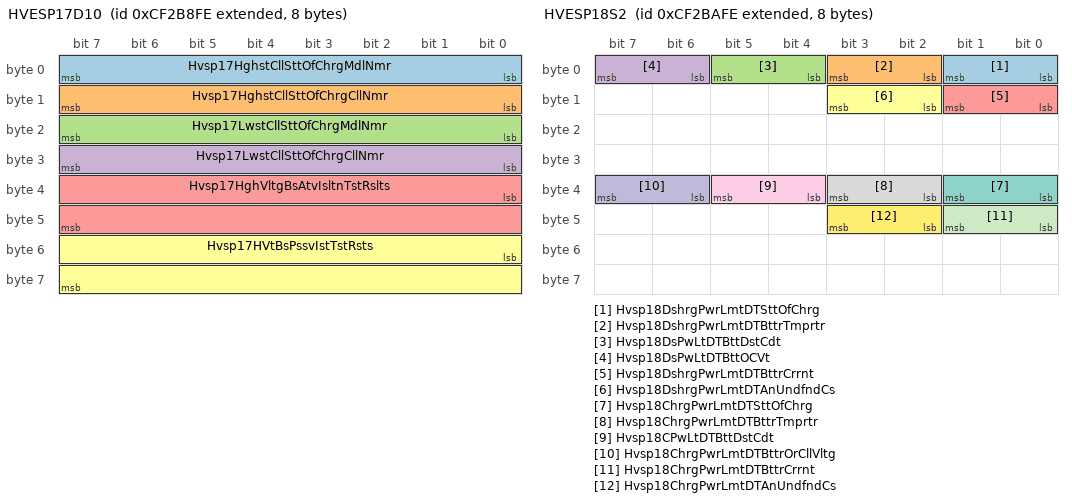
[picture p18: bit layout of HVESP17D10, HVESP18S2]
BO_ 2364717310 HVESP17D10: 8 Vector__XXX
 SG_ Hvsp17HghstCllSttOfChrgMdlNmr : 0|8@1+ (1,0) [0|250] "count" Vector__XXX
 SG_ Hvsp17HghstCllSttOfChrgCllNmr : 8|8@1+ (1,0) [0|250] "count" Vector__XXX
 SG_ Hvsp17LwstCllSttOfChrgMdlNmr : 16|8@1+ (1,0) [0|250] "count" Vector__XXX
 SG_ Hvsp17LwstCllSttOfChrgCllNmr : 24|8@1+ (1,0) [0|250] "count" Vector__XXX
 SG_ Hvsp17HghVltgBsAtvIsltnTstRslts : 32|16@1+ (0.1,0) [0|6425.5] "OhmPerV" Vector__XXX
 SG_ Hvsp17HVtBsPssvIstTstRsts : 48|16@1+ (0.1,0) [0|6425.5] "OhmPerV" Vector__XXX

BO_ 2364717566 HVESP17D11: 8 Vector__XXX
 SG_ Hvsp17BsVltgNgtvTChsssGrndVltg : 0|16@1+ (0.05,0) [0|3212.75] "V" Vector__XXX
 SG_ Hvsp17VltgLvlNgtvTChsssGrndVltg : 16|16@1+ (0.05,0) [0|3212.75] "V" Vector__XXX
 SG_ Hvesp17ActualChargeRate : 32|16@1+ (0.05,0) [0|3212.75] "kW" Vector__XXX

BO_ 2364717822 HVESP18S2: 8 Vector__XXX
 SG_ Hvsp18DshrgPwrLmtDTSttOfChrg : 0|2@1+ (1,0) [0|3] "" Vector__XXX
 SG_ Hvsp18DshrgPwrLmtDTBttrTmprtr : 2|2@1+ (1,0) [0|3] "" Vector__XXX
 SG_ Hvsp18DsPwLtDTBttDstCdt : 4|2@1+ (1,0) [0|3] "" Vector__XXX
 SG_ Hvsp18DsPwLtDTBttOCVt : 6|2@1+ (1,0) [0|3] "" Vector__XXX
 SG_ Hvsp18DshrgPwrLmtDTBttrCrrnt : 8|2@1+ (1,0) [0|3] "" Vector__XXX
 SG_ Hvsp18DshrgPwrLmtDTAnUndfndCs : 10|2@1+ (1,0) [0|3] "" Vector__XXX
 SG_ Hvsp18ChrgPwrLmtDTSttOfChrg : 32|2@1+ (1,0) [0|3] "" Vector__XXX
 SG_ Hvsp18ChrgPwrLmtDTBttrTmprtr : 34|2@1+ (1,0) [0|3] "" Vector__XXX
 SG_ Hvsp18CPwLtDTBttDstCdt : 36|2@1+ (1,0) [0|3] "" Vector__XXX
 SG_ Hvsp18ChrgPwrLmtDTBttrOrCllVltg : 38|2@1+ (1,0) [0|3] "" Vector__XXX
 SG_ Hvsp18ChrgPwrLmtDTBttrCrrnt : 40|2@1+ (1,0) [0|3] "" Vector__XXX
 SG_ Hvsp18ChrgPwrLmtDTAnUndfndCs : 42|2@1+ (1,0) [0|3] "" Vector__XXX

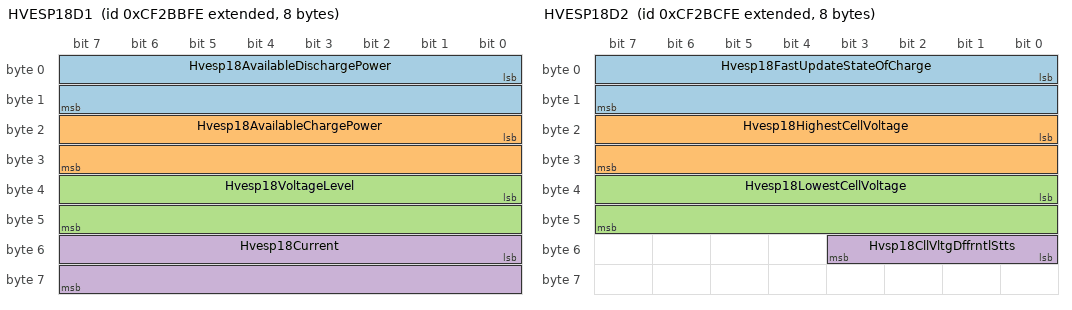
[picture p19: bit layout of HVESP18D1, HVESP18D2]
BO_ 2364718078 HVESP18D1: 8 Vector__XXX
 SG_ Hvesp18AvailableDischargePower : 0|16@1+ (0.05,0) [0|3212.75] "kW" Vector__XXX
 SG_ Hvesp18AvailableChargePower : 16|16@1+ (0.05,0) [0|3212.75] "kW" Vector__XXX
 SG_ Hvesp18VoltageLevel : 32|16@1+ (0.05,0) [0|3212.75] "V" Vector__XXX
 SG_ Hvesp18Current : 48|16@1+ (0.05,-1600) [-1600|1612.75] "A" Vector__XXX

BO_ 2364718334 HVESP18D2: 8 Vector__XXX
 SG_ Hvesp18FastUpdateStateOfCharge : 0|16@1+ (0.0015625,0) [0|100.3984375] "%" Vector__XXX
 SG_ Hvesp18HighestCellVoltage : 16|16@1+ (0.001,0) [0|64.255] "V" Vector__XXX
 SG_ Hvesp18LowestCellVoltage : 32|16@1+ (0.001,0) [0|64.255] "V" Vector__XXX
 SG_ Hvsp18CllVltgDffrntlStts : 48|4@1+ (1,0) [0|15] "" Vector__XXX

CM_ BO_ 2364704766 "High Voltage Energy Storage Pack 14 Module Status 1";
CM_ SG_ 2364704766 Hvesp14Module1OperationalStatus "HVESP14 Module 1 Operational Status: Operational Status of Module 1 in this High Voltage Energy Storage Pack Instance.  Not Operational is used when the module is initializing or not able to function (e.g. internal module level monitors have failed)....";
CM_ SG_ 2364704766 Hvesp14Module2OperationalStatus "HVESP14 Module 2 Operational Status: Operational Status of Module 2 in this High Voltage Energy Storage Pack Instance.  Not Operational is used when the module is initializing or not able to function (e.g. internal module level monitors have failed)....";
CM_ SG_ 2364704766 Hvesp14Module3OperationalStatus "HVESP14 Module 3 Operational Status: Operational Status of Module 3 in this High Voltage Energy Storage Pack Instance.  Not Operational is used when the module is initializing or not able to function (e.g. internal module level monitors have failed)....";
CM_ SG_ 2364704766 Hvesp14Module4OperationalStatus "HVESP14 Module 4 Operational Status: Operational Status of Module 4 in this High Voltage Energy Storage Pack Instance.  Not Operational is used when the module is initializing or not able to function (e.g. internal module level monitors have failed)....";
CM_ SG_ 2364704766 Hvesp14Module5OperationalStatus "HVESP14 Module 5 Operational Status: Operational Status of Module 5 in this High Voltage Energy Storage Pack Instance.  Not Operational is used when the module is initializing or not able to function (e.g. internal module level monitors have failed)....";
CM_ SG_ 2364704766 Hvesp14Module6OperationalStatus "HVESP14 Module 6 Operational Status: Operational Status of Module 6 in this High Voltage Energy Storage Pack Instance.  Not Operational is used when the module is initializing or not able to function (e.g. internal module level monitors have failed)....";
CM_ SG_ 2364704766 Hvesp14Module7OperationalStatus "HVESP14 Module 7 Operational Status: Operational Status of Module 7 in this High Voltage Energy Storage Pack Instance.  Not Operational is used when the module is initializing or not able to function (e.g. internal module level monitors have failed)....";
CM_ SG_ 2364704766 Hvesp14Module8OperationalStatus "HVESP14 Module 8 Operational Status: Operational Status of Module 8 in this High Voltage Energy Storage Pack Instance.  Not Operational is used when the module is initializing or not able to function (e.g. internal module level monitors have failed)....";
CM_ SG_ 2364704766 Hvesp14Module9OperationalStatus "HVESP14 Module 9 Operational Status: Operational Status of Module 9 in this High Voltage Energy Storage Pack Instance.  Not Operational is used when the module is initializing or not able to function (e.g. internal module level monitors have failed)....";
CM_ SG_ 2364704766 Hvsp14Mdl10OprtnlStts "HVESP14 Module 10 Operational Status: Operational Status of Module 10 in this High Voltage Energy Storage Pack Instance.  Not Operational is used when the module is initializing or not able to function (e.g. internal module level monitors have failed...";
CM_ SG_ 2364704766 Hvsp14Mdl11OprtnlStts "HVESP14 Module 11 Operational Status: Operational Status of Module 11 in this High Voltage Energy Storage Pack Instance.  Not Operational is used when the module is initializing or not able to function (e.g. internal module level monitors have failed...";
CM_ SG_ 2364704766 Hvsp14Mdl12OprtnlStts "HVESP14 Module 12 Operational Status: Operational Status of Module 12 in this High Voltage Energy Storage Pack Instance.  Not Operational is used when the module is initializing or not able to function (e.g. internal module level monitors have failed...";
CM_ SG_ 2364704766 Hvsp14Mdl13OprtnlStts "HVESP14 Module 13 Operational Status: Operational Status of Module 13 in this High Voltage Energy Storage Pack Instance.  Not Operational is used when the module is initializing or not able to function (e.g. internal module level monitors have failed...";
CM_ SG_ 2364704766 Hvsp14Mdl14OprtnlStts "HVESP14 Module 14 Operational Status: Operational Status of Module 14 in this High Voltage Energy Storage Pack Instance.  Not Operational is used when the module is initializing or not able to function (e.g. internal module level monitors have failed...";
CM_ SG_ 2364704766 Hvsp14Mdl15OprtnlStts "HVESP14 Module 15 Operational Status: Operational Status of Module 15 in this High Voltage Energy Storage Pack Instance.  Not Operational is used when the module is initializing or not able to function (e.g. internal module level monitors have failed...";
CM_ SG_ 2364704766 Hvsp14Mdl16OprtnlStts "HVESP14 Module 16 Operational Status: Operational Status of Module 16 in this High Voltage Energy Storage Pack Instance.  Not Operational is used when the module is initializing or not able to function (e.g. internal module level monitors have failed...";
CM_ SG_ 2364704766 Hvsp14Mdl17OprtnlStts "HVESP14 Module 17 Operational Status: Operational Status of Module 17 in this High Voltage Energy Storage Pack Instance.  Not Operational is used when the module is initializing or not able to function (e.g. internal module level monitors have failed...";
CM_ SG_ 2364704766 Hvsp14Mdl18OprtnlStts "HVESP14 Module 18 Operational Status: Operational Status of Module 18 in this High Voltage Energy Storage Pack Instance.  Not Operational is used when the module is initializing or not able to function (e.g. internal module level monitors have failed...";
CM_ SG_ 2364704766 Hvsp14Mdl19OprtnlStts "HVESP14 Module 19 Operational Status: Operational Status of Module 19 in this High Voltage Energy Storage Pack Instance.  Not Operational is used when the module is initializing or not able to function (e.g. internal module level monitors have failed...";
CM_ SG_ 2364704766 Hvsp14Mdl20OprtnlStts "HVESP14 Module 20 Operational Status: Operational Status of Module 20 in this High Voltage Energy Storage Pack Instance.  Not Operational is used when the module is initializing or not able to function (e.g. internal module level monitors have failed...";
CM_ SG_ 2364704766 Hvsp14Mdl21OprtnlStts "HVESP14 Module 21 Operational Status: Operational Status of Module 21 in this High Voltage Energy Storage Pack Instance.  Not Operational is used when the module is initializing or not able to function (e.g. internal module level monitors have failed...";
CM_ SG_ 2364704766 Hvsp14Mdl22OprtnlStts "HVESP14 Module 22 Operational Status: Operational Status of Module 22 in this High Voltage Energy Storage Pack Instance.  Not Operational is used when the module is initializing or not able to function (e.g. internal module level monitors have failed...";
CM_ SG_ 2364704766 Hvsp14Mdl23OprtnlStts "HVESP14 Module 23 Operational Status: Operational Status of Module 23 in this High Voltage Energy Storage Pack Instance.  Not Operational is used when the module is initializing or not able to function (e.g. internal module level monitors have failed...";
CM_ SG_ 2364704766 Hvsp14Mdl24OprtnlStts "HVESP14 Module 24 Operational Status: Operational Status of Module 24 in this High Voltage Energy Storage Pack Instance.  Not Operational is used when the module is initializing or not able to function (e.g. internal module level monitors have failed...";
CM_ SG_ 2364704766 Hvsp14Mdl25OprtnlStts "HVESP14 Module 25 Operational Status: Operational Status of Module 25 in this High Voltage Energy Storage Pack Instance.  Not Operational is used when the module is initializing or not able to function (e.g. internal module level monitors have failed...";
CM_ SG_ 2364704766 Hvsp14Mdl26OprtnlStts "HVESP14 Module 26 Operational Status: Operational Status of Module 26 in this High Voltage Energy Storage Pack Instance.  Not Operational is used when the module is initializing or not able to function (e.g. internal module level monitors have failed...";
CM_ SG_ 2364704766 Hvsp14Mdl27OprtnlStts "HVESP14 Module 27 Operational Status: Operational Status of Module 27 in this High Voltage Energy Storage Pack Instance.  Not Operational is used when the module is initializing or not able to function (e.g. internal module level monitors have failed...";
CM_ SG_ 2364704766 Hvsp14Mdl28OprtnlStts "HVESP14 Module 28 Operational Status: Operational Status of Module 28 in this High Voltage Energy Storage Pack Instance.  Not Operational is used when the module is initializing or not able to function (e.g. internal module level monitors have failed...";
CM_ SG_ 2364704766 Hvsp14Mdl29OprtnlStts "HVESP14 Module 29 Operational Status: Operational Status of Module 29 in this High Voltage Energy Storage Pack Instance.  Not Operational is used when the module is initializing or not able to function (e.g. internal module level monitors have failed...";
CM_ SG_ 2364704766 Hvsp14Mdl30OprtnlStts "HVESP14 Module 30 Operational Status: Operational Status of Module 30 in this High Voltage Energy Storage Pack Instance.  Not Operational is used when the module is initializing or not able to function (e.g. internal module level monitors have failed...";
CM_ SG_ 2364704766 Hvsp14Mdl31OprtnlStts "HVESP14 Module 31 Operational Status: Operational Status of Module 31 in this High Voltage Energy Storage Pack Instance.  Not Operational is used when the module is initializing or not able to function (e.g. internal module level monitors have failed...";
CM_ SG_ 2364704766 Hvsp14Mdl32OprtnlStts "HVESP14 Module 32 Operational Status: Operational Status of Module 32 in this High Voltage Energy Storage Pack Instance.  Not Operational is used when the module is initializing or not able to function (e.g. internal module level monitors have failed...";
CM_ BO_ 2364705022 "High Voltage Energy Storage Pack 14 Thermal Management System Status 1";
CM_ SG_ 2364705022 Hvsp14ThrmlMngmntSstmSlInptPwr "HVESP14 Thermal Management System SLI Input Power: This is the low-voltage power consumed by this HVES Thermal Management System (TMS).This parameter is for one of multiple packs in an HVESS.  If there is only one pack in the system, the HVESS parame...";
CM_ SG_ 2364705022 Hvsp14TMtSstHVtIptPw "HVESP14 Thermal Management System High-Voltage Input Power: This is the high-voltage power consumed by this HVES Thermal Management System (TMS).This parameter is for one of multiple packs in an HVESS.  If there is only one pack in the system, the HV...";
CM_ SG_ 2364705022 Hvsp14ThrmlMngmntSstmCmprssrSpd "HVESP14 Thermal Management System Compressor Speed: When this High Voltage Energy Storage Pack Thermal Management System is equipped with an active cooling system (e.g. air conditioner), this is the Compressor Speed.This parameter is for one of multi...";
CM_ SG_ 2364705022 Hvsp14ThrmlMngmntSstmRltvHmdt "HVESP14 Thermal Management System Relative Humidty: When this High Voltage Energy Storage Pack Thermal Management System is equipped with a relative humidity sensor, this is the  measured Relative Humidity.This parameter is for one of multiple packs ...";
CM_ SG_ 2364705022 Hvsp14ThrmlMngmntSstmHtrStts "HVESP14 Thermal Management System Heater Status: The state of this High Voltage Energy Storage Pack heaterThis parameter is for one of multiple packs in an HVESS.  If there is only one pack in the system, the HVESS parameters should be used. If there...";
CM_ SG_ 2364705022 Hvsp14ThrmlMngmntSstmHvlStts "HVESP14 Thermal Management System HVIL Status: In multiple HVES configurations, this is the status of the High Voltage Interlock Loop from the viewpoint of this Thermal Management System.00b = HVIL Closed01b = HVIL Open10b = Error11b = Not AvailableT...";
CM_ SG_ 2364705022 Hvsp14ThrmlMngmntSstmMd "HVESP14 Thermal Management System Mode: Indicates the operating mode of the Thermal Management System.  The heat transfer medium may be (e.g. liquid or air).  The cooling system may be fans, liquid coolant, or a combination of mediums.  The system ma...";
CM_ SG_ 2364705022 Hvsp14ThrmlMngmntSstmClntLvl "HVESP14 Thermal Management System Coolant Level: Indicates the coolant level in this HVES Thermal Management System (TMS).This parameter is for one of multiple packs in an HVESS.  If there is only one pack in the system, the HVESS parameters should b...";
CM_ BO_ 2364705278 "High Voltage Energy Storage Pack 14 Data 8";
CM_ SG_ 2364705278 Hvsp14HghstCllVltgMdlNmr "HVESP14 Highest Cell Voltage Module Number: Identifies the location of the module containing SPN 15723 (HVESP14 Highest Cell Voltage).This parameter is for one of multiple packs in an HVESS. If there is only one pack in the system, the HVESS paramete...";
CM_ SG_ 2364705278 Hvsp14HghstCllVltgCllNmr "HVESP14 Highest Cell Voltage Cell Number: Identifies the location of SPN 15723 (HVESP14 Highest Cell Voltage) within SPN 15803 (HVESP14 Highest Cell Voltage Module Number).This parameter is for one of multiple packs in an HVESS. If there is only one ...";
CM_ SG_ 2364705278 Hvsp14LwstCllVltgMdlNmr "HVESP14 Lowest Cell Voltage Module Number: Identifies the location of the module containing SPN 15724 (HVESP14 Lowest Cell Voltage).This parameter is for one of multiple packs in an HVESS. If there is only one pack in the system, the HVESS parameters...";
CM_ SG_ 2364705278 Hvsp14LwstCllVltgCllNmr "HVESP14 Lowest Cell Voltage Cell Number: Identifies the location of SPN 15724 (HVESP14 Lowest Cell Voltage) within SPN 15805 (HVESP14 Lowest Cell Voltage Module Number).This parameter is for one of multiple packs in an HVESS. If there is only one pac...";
CM_ SG_ 2364705278 Hvesp14AverageCellVoltage "HVESP14 Average Cell Voltage: The average cell voltage in this High Voltage Energy Storage Pack instance.This parameter is for one of multiple packs in an HVESS.  If there is only one pack in the system, the HVESS parameters should be used. If there ...";
CM_ BO_ 2364705534 "High Voltage Energy Storage Pack 14 Data 9";
CM_ SG_ 2364705534 Hvsp14HghstCllTmprtrMdlNmr "HVESP14 Highest Cell Temperature Module Number: Identifies the location of the module containing SPN 15726 (HVESP14 Highest Cell Temperature).This parameter is for one of multiple packs in an HVESS. If there is only one pack in the system, the HVESS ...";
CM_ SG_ 2364705534 Hvsp14HghstCllTmprtrCllNmr "HVESP14 Highest Cell Temperature Cell Number: Identifies the location of SPN 15726 (HVESP14 Highest Cell Temperature) within SPN 15808 (HVESP14 Highest Cell Temperature Module Number).This parameter is for one of multiple packs in an HVESS. If there ...";
CM_ SG_ 2364705534 Hvsp14LwstCllTmprtrMdlNmr "HVESP14 Lowest Cell Temperature Module Number: Identifies the location of the module containing SPN 15727 (HVESP14 Lowest Cell Temperature).This parameter is for one of multiple packs in an HVESS. If there is only one pack in the system, the HVESS pa...";
CM_ SG_ 2364705534 Hvsp14LwstCllTmprtrCllNmr "HVESP14 Lowest Cell Temperature Cell Number: Identifies the location of SPN 15727 (HVESP14 Lowest Cell Temperature) within SPN 15810 (HVESP14 Lowest Cell Temperature Module Number).This parameter is for one of multiple packs in an HVESS. If there is ...";
CM_ SG_ 2364705534 Hvess14ThermalEventDetected "HVESS14 Thermal Event Detected: A sensor has detected the presence of a thermal event at or near High Voltage Energy Storage Pack instance.00b = No Thermal Event Detected01b = Thermal Event Detected10b = Error11b = Not availableThis parameter is for ...";
CM_ SG_ 2364705534 Hvsp14Dt9EmdddIntgrtSpprt "HVESP14 Data 9 Embedded Integrity Support: Indicates SPN 23015 (HVESP14 Data 9 CRC) and SPN 23014 (HVESP14 Data 9 Counter) are supported by the sender.00b = Embedded CRC and Counter are supported by the sender01b = Protection is provided using an ext...";
CM_ SG_ 2364705534 Hvesp14Data9Counter "HVESP14 Data 9 Counter: The message counter is used to detect situations where the transmitting ECU malfunction repeats the same frame all the time. The receiver of the information may use the counter parameter to detect this situation. The transmitt...";
CM_ SG_ 2364705534 Hvesp14Data9Crc "HVESP14 Data 9 CRC: The CRC is defined as follows: - Length: 8 bits- Polynomial: x^8+x^5+x^3+x^2+x+1- Initial Value: FFh- Input Data Reflection: Not reflected- Result Data Reflection: Not reflected- XOR value: FFh SAE makes no claim of the functional...";
CM_ BO_ 2364705790 "High Voltage Energy Storage Pack 14 Data 10";
CM_ SG_ 2364705790 Hvsp14HghstCllSttOfChrgMdlNmr "HVESP14 Highest Cell State of Charge Module Number: Identifies the location of the module containing SPN 15736 (HVESP14 Highest Cell State of Charge).This parameter is for one of multiple packs in an HVESS. If there is only one pack in the system, th...";
CM_ SG_ 2364705790 Hvsp14HghstCllSttOfChrgCllNmr "HVESP14 Highest Cell State of Charge Cell Number: Identifies the location of SPN 15736 (HVESP14 Highest Cell State of Charge) within SPN 15812 (HVESP14 Highest Cell State of Charge Module Number).This parameter is for one of multiple packs in an HVES...";
CM_ SG_ 2364705790 Hvsp14LwstCllSttOfChrgMdlNmr "HVESP14 Lowest Cell State of Charge Module Number: Identifies the location of the module containing SPN 15735 (HVESP14 Lowest Cell State of Charge).This parameter is for one of multiple packs in an HVESS. If there is only one pack in the system, the ...";
CM_ SG_ 2364705790 Hvsp14LwstCllSttOfChrgCllNmr "HVESP14 Lowest Cell State of Charge Cell Number: Identifies the location of SPN 15735 (HVESP14 Lowest Cell State of Charge) within SPN 15814 (HVESP14 Lowest Cell State of Charge Module Number).This parameter is for one of multiple packs in an HVESS. ...";
CM_ SG_ 2364705790 Hvsp14HghVltgBsAtvIsltnTstRslts "HVESP14 High-Voltage Bus Active Isolation Test Results: The isolation resistance expressed in Ohms per Volt that resulted from the High-Voltage Bus Active Isolation Test.See SPN 15748 (HVESP14 High-Voltage Bus Active Isolation Test Status) for test s...";
CM_ SG_ 2364705790 Hvsp14HVtBsPssvIstTstRsts "HVESP14 High-Voltage Bus Passive Isolation Test Results: The isolation resistance expressed in Ohms per Volt that resulted from the High-Voltage Bus Passive Isolation Test.See SPN 15749 (HVESP14 High-Voltage Bus Passive Isolation Test Status) for tes...";
CM_ BO_ 2364706046 "High Voltage Energy Storage Pack 14 Data 11";
CM_ SG_ 2364706046 Hvsp14BsVltgNgtvTChsssGrndVltg "HVESP14 Bus Voltage Negative to Chassis Ground Voltage: Voltage difference between the most negative terminal of the HVES battery and chassis measured on the hybrid or EV system bus side (not the battery side) of any HVES contained output contactor. ...";
CM_ SG_ 2364706046 Hvsp14VltgLvlNgtvTChsssGrndVltg "HVESP14 Voltage Level Negative to Chassis Ground Voltage: Voltage difference between the most negative terminal of the HVES battery and chassis measured at the battery side of any HVES contained output contactor.  This voltage may be used for system ...";
CM_ SG_ 2364706046 Hvesp14ActualChargeRate "HVESP14 Actual Charge Rate: This signal represents the actual present charge rate of this High Voltage Energy Storage Pack instance.This parameter is for one of multiple packs in an HVESS. If there is only one pack in the system, the HVESS parameters...";
CM_ BO_ 2364706302 "High Voltage Energy Storage Pack 15 Status 2";
CM_ SG_ 2364706302 Hvsp15DshrgPwrLmtDTSttOfChrg "HVESP15 Discharge Power Limit Due to State of Charge: Indicates whether or not discharge power of this HVES instance is being limited due to state of charge.This parameter is for one of multiple packs in an HVESS.  If there is only one pack in the sy...";
CM_ SG_ 2364706302 Hvsp15DshrgPwrLmtDTBttrTmprtr "HVESP15 Discharge Power Limit Due to Battery Temperature: Indicates whether or not discharge power of this HVES instance is being limited due to battery temperature.This parameter is for one of multiple packs in an HVESS.  If there is only one pack i...";
CM_ SG_ 2364706302 Hvsp15DsPwLtDTBttDstCdt "HVESP15 Discharge Power Limit Due to Battery Diagnostic Condition: Indicates whether or not discharge power of this HVES instance is being limited due to a battery diagnostic condition.This parameter is for one of multiple packs in an HVESS.  If ther...";
CM_ SG_ 2364706302 Hvsp15DsPwLtDTBttOCVt "HVESP15 Discharge Power Limit Due to Battery or Cell Voltage: Indicates whether or not discharge power of this HVES instance is being limited due to a battery or cell voltage level.This parameter is for one of multiple packs in an HVESS.  If there is...";
CM_ SG_ 2364706302 Hvsp15DshrgPwrLmtDTBttrCrrnt "HVESP15 Discharge Power Limit Due to Battery Current: Indicates whether or not discharge power of this HVES instance is being limited due to battery current.This parameter is for one of multiple packs in an HVESS.  If there is only one pack in the sy...";
CM_ SG_ 2364706302 Hvsp15DshrgPwrLmtDTAnUndfndCs "HVESP15 Discharge Power Limit Due to an Undefined Cause: Indicates whether or not discharge power of this HVES instance is being limited due to an undefined cause.This parameter is for one of multiple packs in an HVESS.  If there is only one pack in ...";
CM_ SG_ 2364706302 Hvsp15ChrgPwrLmtDTSttOfChrg "HVESP15 Charge Power Limit Due to State of Charge: Indicates whether or not charge power of this HVES instance is being limited due to state of charge.This parameter is for one of multiple packs in an HVESS.  If there is only one pack in the system, ...";
CM_ SG_ 2364706302 Hvsp15ChrgPwrLmtDTBttrTmprtr "HVESP15 Charge Power Limit Due to Battery Temperature: Indicates whether or not charge power of this HVES instance is being limited due to battery temperature.This parameter is for one of multiple packs in an HVESS.  If there is only one pack in the ...";
CM_ SG_ 2364706302 Hvsp15CPwLtDTBttDstCdt "HVESP15 Charge Power Limit Due to Battery Diagnostic Condition: Indicates whether or not charge power of this HVES instance is being limited due to a battery diagnostic condition.This parameter is for one of multiple packs in an HVESS.  If there is o...";
CM_ SG_ 2364706302 Hvsp15ChrgPwrLmtDTBttrOrCllVltg "HVESP15 Charge Power Limit Due to Battery or Cell Voltage: Indicates whether or not charge power of this HVES instance is being limited due to a battery or cell voltage level.This parameter is for one of multiple packs in an HVESS.  If there is only ...";
CM_ SG_ 2364706302 Hvsp15ChrgPwrLmtDTBttrCrrnt "HVESP15 Charge Power Limit Due to Battery Current: Indicates whether or not charge power of this HVES instance is being limited due to battery current.This parameter is for one of multiple packs in an HVESS.  If there is only one pack in the system, ...";
CM_ SG_ 2364706302 Hvsp15ChrgPwrLmtDTAnUndfndCs "HVESP15 Charge Power Limit Due to an Undefined Cause: Indicates whether or not charge power of this HVES instance is being limited due to an undefined cause.This parameter is for one of multiple packs in an HVESS.  If there is only one pack in the sy...";
CM_ BO_ 2364706558 "High Voltage Energy Storage Pack 15 Data 1";
CM_ SG_ 2364706558 Hvesp15AvailableDischargePower "HVESP15 Available Discharge Power: The rate at which this High Voltage Energy Storage Pack instance can currently provide energy for propulsion or other uses.This parameter is for one of multiple packs in an HVESS.  If there is only one pack in the s...";
CM_ SG_ 2364706558 Hvesp15AvailableChargePower "HVESP15 Available Charge Power: The rate at which this High Voltage Energy Storage Pack instance can currently receive energy from a regenerative or recharging system.This parameter is for one of multiple packs in an HVESS.  If there is only one pack...";
CM_ SG_ 2364706558 Hvesp15VoltageLevel "HVESP15 Voltage Level: The voltage level of this High Voltage Energy Storage Pack instance. This parameter should be synchronized with SPN 15863 (HVESP15 Current) such that a realized power value can be calculated. If the HVES component physically co...";
CM_ SG_ 2364706558 Hvesp15Current "HVESP15 Current: The current in or out of this High Voltage Energy Storage Pack instance. This parameter should be synchronized with SPN 15862 (HVESP15 Voltage Level) such that a realized power value can be calculated. This parameter is defined from ...";
CM_ BO_ 2364706814 "High Voltage Energy Storage Pack 15 Data 2";
CM_ SG_ 2364706814 Hvesp15FastUpdateStateOfCharge "HVESP15 Fast Update State of Charge: Indicates this High Voltage Energy Storage Pack instance state of charge. 0% means no charge remaining, 100% means the system is fully charged in terms of physical limits of this energy storage pack instance. Acce...";
CM_ SG_ 2364706814 Hvesp15HighestCellVoltage "HVESP15 Highest Cell Voltage: The highest voltage level reported by any cell in this High Voltage Energy Storage Pack instance. If a single voltage sensor covers more than one cell, the value in this parameter is for the smallest group of cells measu...";
CM_ SG_ 2364706814 Hvesp15LowestCellVoltage "HVESP15 Lowest Cell Voltage: The lowest voltage level reported by any cell in this High Voltage Energy Storage Pack instance. If a single voltage sensor covers more than one cell, the value in this parameter is for the smallest group of cells measure...";
CM_ SG_ 2364706814 Hvsp15CllVltgDffrntlStts "HVESP15 Cell Voltage Differential Status: Indicates whether or not the differential between the highest and lowest cell voltages are within acceptable limits, according to this High Voltage Energy Storage Pack instance. The actual voltage differentia...";
CM_ BO_ 2364707070 "High Voltage Energy Storage Pack 15 Data 3";
CM_ SG_ 2364707070 Hvesp15HighestCellTemperature "HVESP15 Highest Cell Temperature: The highest temperature level reported by any cell in this High Voltage Energy Storage Pack instance. If a single temperature sensor covers more than one cell, the value in this parameter is for the smallest group of...";
CM_ SG_ 2364707070 Hvesp15LowestCellTemperature "HVESP15 Lowest Cell Temperature: The lowest temperature level reported by any cell in this High Voltage Energy Storage Pack instance. If a single temperature sensor covers more than one cell, the value in this parameter is for the smallest group of c...";
CM_ SG_ 2364707070 Hvesp15AverageCellTemperature "HVESP15 Average Cell Temperature: The average temperature level of all cells in this High Voltage Energy Storage Pack instance.This parameter is for one of multiple packs in an HVESS.  If there is only one pack in the system, the HVESS parameters sho...";
CM_ SG_ 2364707070 Hvsp15CllTmprtrDffrntlStts "HVESP15 Cell Temperature Differential Status: Indicates whether or not the differential between the highest and lowest cell temperatures are within acceptable limits per this High Voltage Energy Storage Pack instance. The actual temperature different...";
CM_ BO_ 2364707326 "High Voltage Energy Storage Pack 15 Data 4";
CM_ SG_ 2364707326 Hvesp15DischargeCapacity "HVESP15 Discharge Capacity: The amount of stored electrical charge in this High Voltage Energy Storage Pack instance that is available for use by the hybrid or EV system, i.e. 'how full is the tank'. See SPN 15902 (HVESP15 Discharge Energy Capacity) ...";
CM_ SG_ 2364707326 Hvesp15ChargeCapacity "HVESP15 Charge Capacity: The amount of unused electrical charge storage in this High Voltage Energy Storage Pack instance that is available to be filled by charging, i.e. 'how much empty space is remaining in the tank'. See SPN 15903 (HVESP15 Charge ...";
CM_ SG_ 2364707326 Hvesp15CellBalancingCount "HVESP15 Cell Balancing Count: The number of cells that are currently being balanced in this High Voltage Energy Storage Pack instance.This parameter is for one of multiple packs in an HVESS.  If there is only one pack in the system, the HVESS paramet...";
CM_ BO_ 2364707582 "High Voltage Energy Storage Pack 15 Data 5";
CM_ SG_ 2364707582 Hvesp15LowestCellStateOfCharge "HVESP15 Lowest Cell State of Charge: Indicates the state of charge of the lowest-charged cell in this High Voltage Energy Storage Pack instance. 0% means no charge remaining, 100% means the cell is fully charged. If a single state of charge value cov...";
CM_ SG_ 2364707582 Hvesp15HighestCellStateOfCharge "HVESP15 Highest Cell State of Charge: Indicates the state of charge of the highest-charged cell in this High Voltage Energy Storage Pack instance. 0% means no charge remaining, 100% means the cell is fully charged. If a single state of charge value c...";
CM_ SG_ 2364707582 Hvsp15MxmmInstntnsDshrgCrrntLmt "HVESP15 Maximum Instantaneous Discharge Current Limit: The maximum instantaneous current flow limit out of this High Voltage Energy Storage Pack instance. This parameter is defined from the high voltage energy storage pack's point of view and should ...";
CM_ SG_ 2364707582 Hvsp15MxmmInstntnsChrgCrrntLmt "HVESP15 Maximum Instantaneous Charge Current Limit: The maximum instantaneous current flow limit into this High Voltage Energy Storage Pack instance. This parameter is defined from the high voltage energy storage pack's point of view and should refle...";
CM_ BO_ 2364707838 "High Voltage Energy Storage Pack 15 Data 6";
CM_ SG_ 2364707838 Hvesp15BusVoltage "HVESP15 Bus Voltage: The voltage level of the high voltage bus, as measured by this High Voltage Energy Storage Pack instance on the bus side (not the battery side) of its contactors.This parameter is for one of multiple packs in an HVESS.  If there ...";
CM_ SG_ 2364707838 Hvesp15IgnitionVoltage "HVESP15 Ignition Voltage: The voltage level at the ignition input of this High Voltage Energy Storage Pack controller.This parameter is for one of multiple packs in an HVESS.  If there is only one pack in the system, the HVESS parameters should be us...";
CM_ SG_ 2364707838 Hvesp15IntakeCoolantTemperature "HVESP15 Intake Coolant Temperature: The temperature of liquid coolant as it enters this High Voltage Energy Storage Pack instance.This parameter is for one of multiple packs in an HVESS.  If there is only one pack in the system, the HVESS parameters ...";
CM_ SG_ 2364707838 Hvesp15OutletCoolantTemperature "HVESP15 Outlet Coolant Temperature: The temperature of liquid coolant as it exits this High Voltage Energy Storage Pack instance.This parameter is for one of multiple packs in an HVESS.  If there is only one pack in the system, the HVESS parameters s...";
CM_ SG_ 2364707838 Hvesp15ElectronicsTemperature "HVESP15 Electronics Temperature: The temperature of the electronics or control modules in this High Voltage Energy Storage Pack instance.  If there are multiple temperature sensors then this parameter would be set to the maximum sensor reading.This p...";
CM_ SG_ 2364707838 Hvesp15Temperature "HVESP15 Temperature: The temperature of this High Voltage Energy Storage Pack instance. The value may be determined from a unique sensor specifically for this purpose, or by aggregating various temperature sensor readings within the pack.This paramet...";
CM_ BO_ 2364708094 "High Voltage Energy Storage Pack 15 Status 1";
CM_ SG_ 2364708094 Hvsp15HghVltgBsPstvCnttrStt "HVESP15 High-Voltage Bus (Positive) Contactor State: Position of this High Voltage Energy Storage Pack instance positive side bus contactor.  When this contactor is closed, the positive side of this HVES instance is connected to the positive side of ...";
CM_ SG_ 2364708094 Hvsp15HghVltgBsNgtvCnttrStt "HVESP15 High-Voltage Bus (Negative) Contactor State: Position of this High Voltage Energy Storage Pack instance negative side bus contactor. When this contactor is closed, the negative side of this HVES instance is connected to the negative side of t...";
CM_ SG_ 2364708094 Hvsp15HghVltgBsDsnntFrwrnng "HVESP15 High-Voltage Bus Disconnect Forewarning: Indicates that this High Voltage Energy Storage Pack instance is about to disconnect from the high voltage bus due to unacceptable conditions.This parameter is for one of multiple packs in an HVESS. If...";
CM_ SG_ 2364708094 Hvsp15HghVltgBsPrChrgRlStt "HVESP15 High-Voltage Bus Pre-Charge Relay State: Position of the high-voltage bus contactor pre-charge relay.  When this relay is closed, this High Voltage Energy Storage Pack instance is bringing the high-voltage bus up to its operating level.This p...";
CM_ SG_ 2364708094 Hvsp15CntrOfPkCnttrStt "HVESP15 Center of Pack Contactor State: Position of the center high-voltage contactor. When this contactor is closed, the positive half of this High Voltage Energy Storage Pack instance is connected to the negative half. If a system controls the posi...";
CM_ SG_ 2364708094 Hvsp15HghVltgBsAtvIsltnTstStts "HVESP15 High-Voltage Bus Active Isolation Test Status: Status of the high-voltage bus electrical active isolation test as performed by this High Voltage Energy Storage Pack instance.This parameter is for one of multiple packs in an HVESS. If there is...";
CM_ SG_ 2364708094 Hvsp15HghVltgBsPssvIsltnTstStts "HVESP15 High-Voltage Bus Passive Isolation Test Status: Status of the high-voltage bus electrical passive isolation test as performed by this High Voltage Energy Storage Pack instance.This parameter is for one of multiple packs in an HVESS. If there ...";
CM_ SG_ 2364708094 Hvesp15HvilStatus "HVESP15 HVIL Status: Status of the High Voltage Interlock Loop from the viewpoint of this High Voltage Energy Storage Pack instance.This parameter is for one of multiple packs in an HVESS. If there is only one pack in the system, the HVESS parameters...";
CM_ SG_ 2364708094 Hvesp15InertiaSwitchStatus "HVESP15 Inertia Switch Status: Switch indicating that an impact has been sensed by this High Voltage Energy Storage Pack instance. The impact indication may require action by another controller, or by this HVES instance itself.  For example, a contro...";
CM_ SG_ 2364708094 Hvesp15StateOfChargeStatus "HVESP15 State of Charge Status: Status of this High Voltage Energy Storage Pack instance State of Charge (SOC).  Note:  A given HVES controller may not support all of the states.This parameter is for one of multiple packs in an HVESS.  If there is on...";
CM_ SG_ 2364708094 Hvesp15CellBalanceStatus "HVESP15 Cell Balance Status: Indicates whether or not the cells in this High Voltage Energy Storage Pack instance are balanced.This parameter is for one of multiple packs in an HVESS.  If there is only one pack in the system, the HVESS parameters sho...";
CM_ SG_ 2364708094 Hvesp15CellBalancingActive "HVESP15 Cell Balancing Active: Indicates whether or not the cells in this High Voltage Energy Storage Pack instance are currently being balanced.This parameter is for one of multiple packs in an HVESS.  If there is only one pack in the system, the HV...";
CM_ SG_ 2364708094 Hvesp15InternalChargerStatus "HVESP15 Internal Charger Status: Indicates that the charger in this HVES instance is on.  External chargers may use the External Energy Source Connection Status (SPN 7898) and related SPs.This parameter is for one of multiple packs in an HVESS. If th...";
CM_ SG_ 2364708094 Hvsp15HghVltgBsCnntnStts "HVESP15 High-Voltage Bus Connection Status: This parameter provides high level feedback on this High Voltage Energy Storage Pack instance high voltage bus connection. For specific contactor information, see SPN 15885 (HVESP15 High-Voltage Bus (Positi...";
CM_ SG_ 2364708094 Hvesp15OperationalStatus "HVESP15 Operational Status: Provides feedback on where this High Voltage Energy Storage Pack instance is in its operating spectrum, and includes feedback in response to the Operation Consent [i.e. SPN 15843 (HVESP15 Operation Consent)] and Power Down...";
CM_ SG_ 2364708094 Hvesp15Status1Counter "HVESP15 Status 1 Counter: The message counter is used to detect situations where the transmitting ECU malfunction repeats the same frame all the time. The receiver of the information may use the counter parameter to detect this situation. The transmi...";
CM_ SG_ 2364708094 Hvesp15Status1Crc "HVESP15 Status 1 CRC: The CRC is defined as follows: - Length: 8 bits- Polynomial: x^8+x^5+x^3+x^2+x+1- Initial Value: FFh- Input Data Reflection: Not reflected- Result Data Reflection: Not reflected- XOR value: FFh SAE makes no claim of the function...";
CM_ BO_ 2364708350 "High Voltage Energy Storage Pack 15 Data 7";
CM_ SG_ 2364708350 Hvesp15DischargeEnergyCapacity "HVESP15 Discharge Energy Capacity: The amount of stored electrical energy in this High Voltage Energy Storage Pack instance that is available for use by the hybrid or EV system, i.e. 'how full is the tank'. See SPN 15872 (HVESP15 Discharge Capacity) ...";
CM_ SG_ 2364708350 Hvesp15ChargeEnergyCapacity "HVESP15 Charge Energy Capacity: The amount of unused electrical energy storage available to be filled by charging this High Voltage Energy Storage Pack instance, i.e. 'how much empty space is remaining in the tank'. See SPN 15873 (HVESP15 Charge Capa...";
CM_ SG_ 2364708350 Hvsp15MxmmChrgVltgLmt "HVESP15 Maximum Charge Voltage Limit: The maximum voltage level not to be exceeded while charging this High Voltage Energy Storage Pack instance. If this parameter is not supported, the maximum charge voltage should be limited to SPN 15971 (HVESP15 R...";
CM_ BO_ 2364708606 "High Voltage Energy Storage Pack 15 Module Status 1";
CM_ SG_ 2364708606 Hvesp15Module1OperationalStatus "HVESP15 Module 1 Operational Status: Operational Status of Module 1 in this High Voltage Energy Storage Pack Instance.  Not Operational is used when the module is initializing or not able to function (e.g. internal module level monitors have failed)....";
CM_ SG_ 2364708606 Hvesp15Module2OperationalStatus "HVESP15 Module 2 Operational Status: Operational Status of Module 2 in this High Voltage Energy Storage Pack Instance.  Not Operational is used when the module is initializing or not able to function (e.g. internal module level monitors have failed)....";
CM_ SG_ 2364708606 Hvesp15Module3OperationalStatus "HVESP15 Module 3 Operational Status: Operational Status of Module 3 in this High Voltage Energy Storage Pack Instance.  Not Operational is used when the module is initializing or not able to function (e.g. internal module level monitors have failed)....";
CM_ SG_ 2364708606 Hvesp15Module4OperationalStatus "HVESP15 Module 4 Operational Status: Operational Status of Module 4 in this High Voltage Energy Storage Pack Instance.  Not Operational is used when the module is initializing or not able to function (e.g. internal module level monitors have failed)....";
CM_ SG_ 2364708606 Hvesp15Module5OperationalStatus "HVESP15 Module 5 Operational Status: Operational Status of Module 5 in this High Voltage Energy Storage Pack Instance.  Not Operational is used when the module is initializing or not able to function (e.g. internal module level monitors have failed)....";
CM_ SG_ 2364708606 Hvesp15Module6OperationalStatus "HVESP15 Module 6 Operational Status: Operational Status of Module 6 in this High Voltage Energy Storage Pack Instance.  Not Operational is used when the module is initializing or not able to function (e.g. internal module level monitors have failed)....";
CM_ SG_ 2364708606 Hvesp15Module7OperationalStatus "HVESP15 Module 7 Operational Status: Operational Status of Module 7 in this High Voltage Energy Storage Pack Instance.  Not Operational is used when the module is initializing or not able to function (e.g. internal module level monitors have failed)....";
CM_ SG_ 2364708606 Hvesp15Module8OperationalStatus "HVESP15 Module 8 Operational Status: Operational Status of Module 8 in this High Voltage Energy Storage Pack Instance.  Not Operational is used when the module is initializing or not able to function (e.g. internal module level monitors have failed)....";
CM_ SG_ 2364708606 Hvesp15Module9OperationalStatus "HVESP15 Module 9 Operational Status: Operational Status of Module 9 in this High Voltage Energy Storage Pack Instance.  Not Operational is used when the module is initializing or not able to function (e.g. internal module level monitors have failed)....";
CM_ SG_ 2364708606 Hvsp15Mdl10OprtnlStts "HVESP15 Module 10 Operational Status: Operational Status of Module 10 in this High Voltage Energy Storage Pack Instance.  Not Operational is used when the module is initializing or not able to function (e.g. internal module level monitors have failed...";
CM_ SG_ 2364708606 Hvsp15Mdl11OprtnlStts "HVESP15 Module 11 Operational Status: Operational Status of Module 11 in this High Voltage Energy Storage Pack Instance.  Not Operational is used when the module is initializing or not able to function (e.g. internal module level monitors have failed...";
CM_ SG_ 2364708606 Hvsp15Mdl12OprtnlStts "HVESP15 Module 12 Operational Status: Operational Status of Module 12 in this High Voltage Energy Storage Pack Instance.  Not Operational is used when the module is initializing or not able to function (e.g. internal module level monitors have failed...";
CM_ SG_ 2364708606 Hvsp15Mdl13OprtnlStts "HVESP15 Module 13 Operational Status: Operational Status of Module 13 in this High Voltage Energy Storage Pack Instance.  Not Operational is used when the module is initializing or not able to function (e.g. internal module level monitors have failed...";
CM_ SG_ 2364708606 Hvsp15Mdl14OprtnlStts "HVESP15 Module 14 Operational Status: Operational Status of Module 14 in this High Voltage Energy Storage Pack Instance.  Not Operational is used when the module is initializing or not able to function (e.g. internal module level monitors have failed...";
CM_ SG_ 2364708606 Hvsp15Mdl15OprtnlStts "HVESP15 Module 15 Operational Status: Operational Status of Module 15 in this High Voltage Energy Storage Pack Instance.  Not Operational is used when the module is initializing or not able to function (e.g. internal module level monitors have failed...";
CM_ SG_ 2364708606 Hvsp15Mdl16OprtnlStts "HVESP15 Module 16 Operational Status: Operational Status of Module 16 in this High Voltage Energy Storage Pack Instance.  Not Operational is used when the module is initializing or not able to function (e.g. internal module level monitors have failed...";
CM_ SG_ 2364708606 Hvsp15Mdl17OprtnlStts "HVESP15 Module 17 Operational Status: Operational Status of Module 17 in this High Voltage Energy Storage Pack Instance.  Not Operational is used when the module is initializing or not able to function (e.g. internal module level monitors have failed...";
CM_ SG_ 2364708606 Hvsp15Mdl18OprtnlStts "HVESP15 Module 18 Operational Status: Operational Status of Module 18 in this High Voltage Energy Storage Pack Instance.  Not Operational is used when the module is initializing or not able to function (e.g. internal module level monitors have failed...";
CM_ SG_ 2364708606 Hvsp15Mdl19OprtnlStts "HVESP15 Module 19 Operational Status: Operational Status of Module 19 in this High Voltage Energy Storage Pack Instance.  Not Operational is used when the module is initializing or not able to function (e.g. internal module level monitors have failed...";
CM_ SG_ 2364708606 Hvsp15Mdl20OprtnlStts "HVESP15 Module 20 Operational Status: Operational Status of Module 20 in this High Voltage Energy Storage Pack Instance.  Not Operational is used when the module is initializing or not able to function (e.g. internal module level monitors have failed...";
CM_ SG_ 2364708606 Hvsp15Mdl21OprtnlStts "HVESP15 Module 21 Operational Status: Operational Status of Module 21 in this High Voltage Energy Storage Pack Instance.  Not Operational is used when the module is initializing or not able to function (e.g. internal module level monitors have failed...";
CM_ SG_ 2364708606 Hvsp15Mdl22OprtnlStts "HVESP15 Module 22 Operational Status: Operational Status of Module 22 in this High Voltage Energy Storage Pack Instance.  Not Operational is used when the module is initializing or not able to function (e.g. internal module level monitors have failed...";
CM_ SG_ 2364708606 Hvsp15Mdl23OprtnlStts "HVESP15 Module 23 Operational Status: Operational Status of Module 23 in this High Voltage Energy Storage Pack Instance.  Not Operational is used when the module is initializing or not able to function (e.g. internal module level monitors have failed...";
CM_ SG_ 2364708606 Hvsp15Mdl24OprtnlStts "HVESP15 Module 24 Operational Status: Operational Status of Module 24 in this High Voltage Energy Storage Pack Instance.  Not Operational is used when the module is initializing or not able to function (e.g. internal module level monitors have failed...";
CM_ SG_ 2364708606 Hvsp15Mdl25OprtnlStts "HVESP15 Module 25 Operational Status: Operational Status of Module 25 in this High Voltage Energy Storage Pack Instance.  Not Operational is used when the module is initializing or not able to function (e.g. internal module level monitors have failed...";
CM_ SG_ 2364708606 Hvsp15Mdl26OprtnlStts "HVESP15 Module 26 Operational Status: Operational Status of Module 26 in this High Voltage Energy Storage Pack Instance.  Not Operational is used when the module is initializing or not able to function (e.g. internal module level monitors have failed...";
CM_ SG_ 2364708606 Hvsp15Mdl27OprtnlStts "HVESP15 Module 27 Operational Status: Operational Status of Module 27 in this High Voltage Energy Storage Pack Instance.  Not Operational is used when the module is initializing or not able to function (e.g. internal module level monitors have failed...";
CM_ SG_ 2364708606 Hvsp15Mdl28OprtnlStts "HVESP15 Module 28 Operational Status: Operational Status of Module 28 in this High Voltage Energy Storage Pack Instance.  Not Operational is used when the module is initializing or not able to function (e.g. internal module level monitors have failed...";
CM_ SG_ 2364708606 Hvsp15Mdl29OprtnlStts "HVESP15 Module 29 Operational Status: Operational Status of Module 29 in this High Voltage Energy Storage Pack Instance.  Not Operational is used when the module is initializing or not able to function (e.g. internal module level monitors have failed...";
CM_ SG_ 2364708606 Hvsp15Mdl30OprtnlStts "HVESP15 Module 30 Operational Status: Operational Status of Module 30 in this High Voltage Energy Storage Pack Instance.  Not Operational is used when the module is initializing or not able to function (e.g. internal module level monitors have failed...";
CM_ SG_ 2364708606 Hvsp15Mdl31OprtnlStts "HVESP15 Module 31 Operational Status: Operational Status of Module 31 in this High Voltage Energy Storage Pack Instance.  Not Operational is used when the module is initializing or not able to function (e.g. internal module level monitors have failed...";
CM_ SG_ 2364708606 Hvsp15Mdl32OprtnlStts "HVESP15 Module 32 Operational Status: Operational Status of Module 32 in this High Voltage Energy Storage Pack Instance.  Not Operational is used when the module is initializing or not able to function (e.g. internal module level monitors have failed...";
CM_ BO_ 2364708862 "High Voltage Energy Storage Pack 15 Thermal Management System Status 1";
CM_ SG_ 2364708862 Hvsp15ThrmlMngmntSstmSlInptPwr "HVESP15 Thermal Management System SLI Input Power: This is the low-voltage power consumed by this HVES Thermal Management System (TMS).This parameter is for one of multiple packs in an HVESS.  If there is only one pack in the system, the HVESS parame...";
CM_ SG_ 2364708862 Hvsp15TMtSstHVtIptPw "HVESP15 Thermal Management System High-Voltage Input Power: This is the high-voltage power consumed by this HVES Thermal Management System (TMS).This parameter is for one of multiple packs in an HVESS.  If there is only one pack in the system, the HV...";
CM_ SG_ 2364708862 Hvsp15ThrmlMngmntSstmCmprssrSpd "HVESP15 Thermal Management System Compressor Speed: When this High Voltage Energy Storage Pack Thermal Management System is equipped with an active cooling system (e.g. air conditioner), this is the Compressor Speed.This parameter is for one of multi...";
CM_ SG_ 2364708862 Hvsp15ThrmlMngmntSstmRltvHmdt "HVESP15 Thermal Management System Relative Humidty: When this High Voltage Energy Storage Pack Thermal Management System is equipped with a relative humidity sensor, this is the  measured Relative Humidity.This parameter is for one of multiple packs ...";
CM_ SG_ 2364708862 Hvsp15ThrmlMngmntSstmHtrStts "HVESP15 Thermal Management System Heater Status: The state of this High Voltage Energy Storage Pack heaterThis parameter is for one of multiple packs in an HVESS.  If there is only one pack in the system, the HVESS parameters should be used. If there...";
CM_ SG_ 2364708862 Hvsp15ThrmlMngmntSstmHvlStts "HVESP15 Thermal Management System HVIL Status: In multiple HVES configurations, this is the status of the High Voltage Interlock Loop from the viewpoint of this Thermal Management System.00b = HVIL Closed01b = HVIL Open10b = Error11b = Not AvailableT...";
CM_ SG_ 2364708862 Hvsp15ThrmlMngmntSstmMd "HVESP15 Thermal Management System Mode: Indicates the operating mode of the Thermal Management System.  The heat transfer medium may be (e.g. liquid or air).  The cooling system may be fans, liquid coolant, or a combination of mediums.  The system ma...";
CM_ SG_ 2364708862 Hvsp15ThrmlMngmntSstmClntLvl "HVESP15 Thermal Management System Coolant Level: Indicates the coolant level in this HVES Thermal Management System (TMS).This parameter is for one of multiple packs in an HVESS.  If there is only one pack in the system, the HVESS parameters should b...";
CM_ BO_ 2364709118 "High Voltage Energy Storage Pack 15 Data 8";
CM_ SG_ 2364709118 Hvsp15HghstCllVltgMdlNmr "HVESP15 Highest Cell Voltage Module Number: Identifies the location of the module containing SPN 15865 (HVESP15 Highest Cell Voltage).This parameter is for one of multiple packs in an HVESS. If there is only one pack in the system, the HVESS paramete...";
CM_ SG_ 2364709118 Hvsp15HghstCllVltgCllNmr "HVESP15 Highest Cell Voltage Cell Number: Identifies the location of SPN 15865 (HVESP15 Highest Cell Voltage) within SPN 15945 (HVESP15 Highest Cell Voltage Module Number).This parameter is for one of multiple packs in an HVESS. If there is only one ...";
CM_ SG_ 2364709118 Hvsp15LwstCllVltgMdlNmr "HVESP15 Lowest Cell Voltage Module Number: Identifies the location of the module containing SPN 15866 (HVESP15 Lowest Cell Voltage).This parameter is for one of multiple packs in an HVESS. If there is only one pack in the system, the HVESS parameters...";
CM_ SG_ 2364709118 Hvsp15LwstCllVltgCllNmr "HVESP15 Lowest Cell Voltage Cell Number: Identifies the location of SPN 15866 (HVESP15 Lowest Cell Voltage) within SPN 15947 (HVESP15 Lowest Cell Voltage Module Number).This parameter is for one of multiple packs in an HVESS. If there is only one pac...";
CM_ SG_ 2364709118 Hvesp15AverageCellVoltage "HVESP15 Average Cell Voltage: The average cell voltage in this High Voltage Energy Storage Pack instance.This parameter is for one of multiple packs in an HVESS.  If there is only one pack in the system, the HVESS parameters should be used. If there ...";
CM_ BO_ 2364709374 "High Voltage Energy Storage Pack 15 Data 9";
CM_ SG_ 2364709374 Hvsp15HghstCllTmprtrMdlNmr "HVESP15 Highest Cell Temperature Module Number: Identifies the location of the module containing SPN 15868 (HVESP15 Highest Cell Temperature).This parameter is for one of multiple packs in an HVESS. If there is only one pack in the system, the HVESS ...";
CM_ SG_ 2364709374 Hvsp15HghstCllTmprtrCllNmr "HVESP15 Highest Cell Temperature Cell Number: Identifies the location of SPN 15868 (HVESP15 Highest Cell Temperature) within SPN 15950 (HVESP15 Highest Cell Temperature Module Number).This parameter is for one of multiple packs in an HVESS. If there ...";
CM_ SG_ 2364709374 Hvsp15LwstCllTmprtrMdlNmr "HVESP15 Lowest Cell Temperature Module Number: Identifies the location of the module containing SPN 15869 (HVESP15 Lowest Cell Temperature).This parameter is for one of multiple packs in an HVESS. If there is only one pack in the system, the HVESS pa...";
CM_ SG_ 2364709374 Hvsp15LwstCllTmprtrCllNmr "HVESP15 Lowest Cell Temperature Cell Number: Identifies the location of SPN 15869 (HVESP15 Lowest Cell Temperature) within SPN 15952 (HVESP15 Lowest Cell Temperature Module Number).This parameter is for one of multiple packs in an HVESS. If there is ...";
CM_ SG_ 2364709374 Hvess15ThermalEventDetected "HVESS15 Thermal Event Detected: A sensor has detected the presence of a thermal event at or near High Voltage Energy Storage Pack instance.00b = No Thermal Event Detected01b = Thermal Event Detected10b = Error11b = Not availableThis parameter is for ...";
CM_ SG_ 2364709374 Hvsp15Dt9EmdddIntgrtSpprt "HVESP15 Data 9 Embedded Integrity Support: Indicates SPN 23018 (HVESP15 Data 9 CRC) and SPN 23017 (HVESP15 Data 9 Counter) are supported by the sender.00b = Embedded CRC and Counter are supported by the sender01b = Protection is provided using an ext...";
CM_ SG_ 2364709374 Hvesp15Data9Counter "HVESP15 Data 9 Counter: The message counter is used to detect situations where the transmitting ECU malfunction repeats the same frame all the time. The receiver of the information may use the counter parameter to detect this situation. The transmitt...";
CM_ SG_ 2364709374 Hvesp15Data9Crc "HVESP15 Data 9 CRC: The CRC is defined as follows: - Length: 8 bits- Polynomial: x^8+x^5+x^3+x^2+x+1- Initial Value: FFh- Input Data Reflection: Not reflected- Result Data Reflection: Not reflected- XOR value: FFh SAE makes no claim of the functional...";
CM_ BO_ 2364709630 "High Voltage Energy Storage Pack 15 Data 10";
CM_ SG_ 2364709630 Hvsp15HghstCllSttOfChrgMdlNmr "HVESP15 Highest Cell State of Charge Module Number: Identifies the location of the module containing SPN 15878 (HVESP15 Highest Cell State of Charge).This parameter is for one of multiple packs in an HVESS. If there is only one pack in the system, th...";
CM_ SG_ 2364709630 Hvsp15HghstCllSttOfChrgCllNmr "HVESP15 Highest Cell State of Charge Cell Number: Identifies the location of SPN 15878 (HVESP15 Highest Cell State of Charge) within SPN 15954 (HVESP15 Highest Cell State of Charge Module Number).This parameter is for one of multiple packs in an HVES...";
CM_ SG_ 2364709630 Hvsp15LwstCllSttOfChrgMdlNmr "HVESP15 Lowest Cell State of Charge Module Number: Identifies the location of the module containing SPN 15877 (HVESP15 Lowest Cell State of Charge).This parameter is for one of multiple packs in an HVESS. If there is only one pack in the system, the ...";
CM_ SG_ 2364709630 Hvsp15LwstCllSttOfChrgCllNmr "HVESP15 Lowest Cell State of Charge Cell Number: Identifies the location of SPN 15877 (HVESP15 Lowest Cell State of Charge) within SPN 15956 (HVESP15 Lowest Cell State of Charge Module Number).This parameter is for one of multiple packs in an HVESS. ...";
CM_ SG_ 2364709630 Hvsp15HghVltgBsAtvIsltnTstRslts "HVESP15 High-Voltage Bus Active Isolation Test Results: The isolation resistance expressed in Ohms per Volt that resulted from the High-Voltage Bus Active Isolation Test.See SPN 15890 (HVESP15 High-Voltage Bus Active Isolation Test Status) for test s...";
CM_ SG_ 2364709630 Hvsp15HVtBsPssvIstTstRsts "HVESP15 High-Voltage Bus Passive Isolation Test Results: The isolation resistance expressed in Ohms per Volt that resulted from the High-Voltage Bus Passive Isolation Test.See SPN 15891 (HVESP15 High-Voltage Bus Passive Isolation Test Status) for tes...";
CM_ BO_ 2364709886 "High Voltage Energy Storage Pack 15 Data 11";
CM_ SG_ 2364709886 Hvsp15BsVltgNgtvTChsssGrndVltg "HVESP15 Bus Voltage Negative to Chassis Ground Voltage: Voltage difference between the most negative terminal of the HVES battery and chassis measured on the hybrid or EV system bus side (not the battery side) of any HVES contained output contactor. ...";
CM_ SG_ 2364709886 Hvsp15VltgLvlNgtvTChsssGrndVltg "HVESP15 Voltage Level Negative to Chassis Ground Voltage: Voltage difference between the most negative terminal of the HVES battery and chassis measured at the battery side of any HVES contained output contactor.  This voltage may be used for system ...";
CM_ SG_ 2364709886 Hvesp15ActualChargeRate "HVESP15 Actual Charge Rate: This signal represents the actual present charge rate of this High Voltage Energy Storage Pack instance.This parameter is for one of multiple packs in an HVESS. If there is only one pack in the system, the HVESS parameters...";
CM_ BO_ 2364710142 "High Voltage Energy Storage Pack 16 Status 2";
CM_ SG_ 2364710142 Hvsp16DshrgPwrLmtDTSttOfChrg "HVESP16 Discharge Power Limit Due to State of Charge: Indicates whether or not discharge power of this HVES instance is being limited due to state of charge.This parameter is for one of multiple packs in an HVESS.  If there is only one pack in the sy...";
CM_ SG_ 2364710142 Hvsp16DshrgPwrLmtDTBttrTmprtr "HVESP16 Discharge Power Limit Due to Battery Temperature: Indicates whether or not discharge power of this HVES instance is being limited due to battery temperature.This parameter is for one of multiple packs in an HVESS.  If there is only one pack i...";
CM_ SG_ 2364710142 Hvsp16DsPwLtDTBttDstCdt "HVESP16 Discharge Power Limit Due to Battery Diagnostic Condition: Indicates whether or not discharge power of this HVES instance is being limited due to a battery diagnostic condition.This parameter is for one of multiple packs in an HVESS.  If ther...";
CM_ SG_ 2364710142 Hvsp16DsPwLtDTBttOCVt "HVESP16 Discharge Power Limit Due to Battery or Cell Voltage: Indicates whether or not discharge power of this HVES instance is being limited due to a battery or cell voltage level.This parameter is for one of multiple packs in an HVESS.  If there is...";
CM_ SG_ 2364710142 Hvsp16DshrgPwrLmtDTBttrCrrnt "HVESP16 Discharge Power Limit Due to Battery Current: Indicates whether or not discharge power of this HVES instance is being limited due to battery current.This parameter is for one of multiple packs in an HVESS.  If there is only one pack in the sy...";
CM_ SG_ 2364710142 Hvsp16DshrgPwrLmtDTAnUndfndCs "HVESP16 Discharge Power Limit Due to an Undefined Cause: Indicates whether or not discharge power of this HVES instance is being limited due to an undefined cause.This parameter is for one of multiple packs in an HVESS.  If there is only one pack in ...";
CM_ SG_ 2364710142 Hvsp16ChrgPwrLmtDTSttOfChrg "HVESP16 Charge Power Limit Due to State of Charge: Indicates whether or not charge power of this HVES instance is being limited due to state of charge.This parameter is for one of multiple packs in an HVESS.  If there is only one pack in the system, ...";
CM_ SG_ 2364710142 Hvsp16ChrgPwrLmtDTBttrTmprtr "HVESP16 Charge Power Limit Due to Battery Temperature: Indicates whether or not charge power of this HVES instance is being limited due to battery temperature.This parameter is for one of multiple packs in an HVESS.  If there is only one pack in the ...";
CM_ SG_ 2364710142 Hvsp16CPwLtDTBttDstCdt "HVESP16 Charge Power Limit Due to Battery Diagnostic Condition: Indicates whether or not charge power of this HVES instance is being limited due to a battery diagnostic condition.This parameter is for one of multiple packs in an HVESS.  If there is o...";
CM_ SG_ 2364710142 Hvsp16ChrgPwrLmtDTBttrOrCllVltg "HVESP16 Charge Power Limit Due to Battery or Cell Voltage: Indicates whether or not charge power of this HVES instance is being limited due to a battery or cell voltage level.This parameter is for one of multiple packs in an HVESS.  If there is only ...";
CM_ SG_ 2364710142 Hvsp16ChrgPwrLmtDTBttrCrrnt "HVESP16 Charge Power Limit Due to Battery Current: Indicates whether or not charge power of this HVES instance is being limited due to battery current.This parameter is for one of multiple packs in an HVESS.  If there is only one pack in the system, ...";
CM_ SG_ 2364710142 Hvsp16ChrgPwrLmtDTAnUndfndCs "HVESP16 Charge Power Limit Due to an Undefined Cause: Indicates whether or not charge power of this HVES instance is being limited due to an undefined cause.This parameter is for one of multiple packs in an HVESS.  If there is only one pack in the sy...";
CM_ BO_ 2364710398 "High Voltage Energy Storage Pack 16 Data 1";
CM_ SG_ 2364710398 Hvesp16AvailableDischargePower "HVESP16 Available Discharge Power: The rate at which this High Voltage Energy Storage Pack instance can currently provide energy for propulsion or other uses.This parameter is for one of multiple packs in an HVESS.  If there is only one pack in the s...";
CM_ SG_ 2364710398 Hvesp16AvailableChargePower "HVESP16 Available Charge Power: The rate at which this High Voltage Energy Storage Pack instance can currently receive energy from a regenerative or recharging system.This parameter is for one of multiple packs in an HVESS.  If there is only one pack...";
CM_ SG_ 2364710398 Hvesp16VoltageLevel "HVESP16 Voltage Level: The voltage level of this High Voltage Energy Storage Pack instance. This parameter should be synchronized with SPN 16005 (HVESP16 Current) such that a realized power value can be calculated. If the HVES component physically co...";
CM_ SG_ 2364710398 Hvesp16Current "HVESP16 Current: The current in or out of this High Voltage Energy Storage Pack instance. This parameter should be synchronized with SPN 16004 (HVESP16 Voltage Level) such that a realized power value can be calculated. This parameter is defined from ...";
CM_ BO_ 2364710654 "High Voltage Energy Storage Pack 16 Data 2";
CM_ SG_ 2364710654 Hvesp16FastUpdateStateOfCharge "HVESP16 Fast Update State of Charge: Indicates this High Voltage Energy Storage Pack instance state of charge. 0% means no charge remaining, 100% means the system is fully charged in terms of physical limits of this energy storage pack instance. Acce...";
CM_ SG_ 2364710654 Hvesp16HighestCellVoltage "HVESP16 Highest Cell Voltage: The highest voltage level reported by any cell in this High Voltage Energy Storage Pack instance. If a single voltage sensor covers more than one cell, the value in this parameter is for the smallest group of cells measu...";
CM_ SG_ 2364710654 Hvesp16LowestCellVoltage "HVESP16 Lowest Cell Voltage: The lowest voltage level reported by any cell in this High Voltage Energy Storage Pack instance. If a single voltage sensor covers more than one cell, the value in this parameter is for the smallest group of cells measure...";
CM_ SG_ 2364710654 Hvsp16CllVltgDffrntlStts "HVESP16 Cell Voltage Differential Status: Indicates whether or not the differential between the highest and lowest cell voltages are within acceptable limits, according to this High Voltage Energy Storage Pack instance. The actual voltage differentia...";
CM_ BO_ 2364710910 "High Voltage Energy Storage Pack 16 Data 3";
CM_ SG_ 2364710910 Hvesp16HighestCellTemperature "HVESP16 Highest Cell Temperature: The highest temperature level reported by any cell in this High Voltage Energy Storage Pack instance. If a single temperature sensor covers more than one cell, the value in this parameter is for the smallest group of...";
CM_ SG_ 2364710910 Hvesp16LowestCellTemperature "HVESP16 Lowest Cell Temperature: The lowest temperature level reported by any cell in this High Voltage Energy Storage Pack instance. If a single temperature sensor covers more than one cell, the value in this parameter is for the smallest group of c...";
CM_ SG_ 2364710910 Hvesp16AverageCellTemperature "HVESP16 Average Cell Temperature: The average temperature level of all cells in this High Voltage Energy Storage Pack instance.This parameter is for one of multiple packs in an HVESS.  If there is only one pack in the system, the HVESS parameters sho...";
CM_ SG_ 2364710910 Hvsp16CllTmprtrDffrntlStts "HVESP16 Cell Temperature Differential Status: Indicates whether or not the differential between the highest and lowest cell temperatures are within acceptable limits per this High Voltage Energy Storage Pack instance. The actual temperature different...";
CM_ BO_ 2364711166 "High Voltage Energy Storage Pack 16 Data 4";
CM_ SG_ 2364711166 Hvesp16DischargeCapacity "HVESP16 Discharge Capacity: The amount of stored electrical charge in this High Voltage Energy Storage Pack instance that is available for use by the hybrid or EV system, i.e. 'how full is the tank'. See SPN 16044 (HVESP16 Discharge Energy Capacity) ...";
CM_ SG_ 2364711166 Hvesp16ChargeCapacity "HVESP16 Charge Capacity: The amount of unused electrical charge storage in this High Voltage Energy Storage Pack instance that is available to be filled by charging, i.e. 'how much empty space is remaining in the tank'. See SPN 16045 (HVESP16 Charge ...";
CM_ SG_ 2364711166 Hvesp16CellBalancingCount "HVESP16 Cell Balancing Count: The number of cells that are currently being balanced in this High Voltage Energy Storage Pack instance.This parameter is for one of multiple packs in an HVESS.  If there is only one pack in the system, the HVESS paramet...";
CM_ BO_ 2364711422 "High Voltage Energy Storage Pack 16 Data 5";
CM_ SG_ 2364711422 Hvesp16LowestCellStateOfCharge "HVESP16 Lowest Cell State of Charge: Indicates the state of charge of the lowest-charged cell in this High Voltage Energy Storage Pack instance. 0% means no charge remaining, 100% means the cell is fully charged. If a single state of charge value cov...";
CM_ SG_ 2364711422 Hvesp16HighestCellStateOfCharge "HVESP16 Highest Cell State of Charge: Indicates the state of charge of the highest-charged cell in this High Voltage Energy Storage Pack instance. 0% means no charge remaining, 100% means the cell is fully charged. If a single state of charge value c...";
CM_ SG_ 2364711422 Hvsp16MxmmInstntnsDshrgCrrntLmt "HVESP16 Maximum Instantaneous Discharge Current Limit: The maximum instantaneous current flow limit out of this High Voltage Energy Storage Pack instance. This parameter is defined from the high voltage energy storage pack's point of view and should ...";
CM_ SG_ 2364711422 Hvsp16MxmmInstntnsChrgCrrntLmt "HVESP16 Maximum Instantaneous Charge Current Limit: The maximum instantaneous current flow limit into this High Voltage Energy Storage Pack instance. This parameter is defined from the high voltage energy storage pack's point of view and should refle...";
CM_ BO_ 2364711678 "High Voltage Energy Storage Pack 16 Data 6";
CM_ SG_ 2364711678 Hvesp16BusVoltage "HVESP16 Bus Voltage: The voltage level of the high voltage bus, as measured by this High Voltage Energy Storage Pack instance on the bus side (not the battery side) of its contactors.This parameter is for one of multiple packs in an HVESS.  If there ...";
CM_ SG_ 2364711678 Hvesp16IgnitionVoltage "HVESP16 Ignition Voltage: The voltage level at the ignition input of this High Voltage Energy Storage Pack controller.This parameter is for one of multiple packs in an HVESS.  If there is only one pack in the system, the HVESS parameters should be us...";
CM_ SG_ 2364711678 Hvesp16IntakeCoolantTemperature "HVESP16 Intake Coolant Temperature: The temperature of liquid coolant as it enters this High Voltage Energy Storage Pack instance.This parameter is for one of multiple packs in an HVESS.  If there is only one pack in the system, the HVESS parameters ...";
CM_ SG_ 2364711678 Hvesp16OutletCoolantTemperature "HVESP16 Outlet Coolant Temperature: The temperature of liquid coolant as it exits this High Voltage Energy Storage Pack instance.This parameter is for one of multiple packs in an HVESS.  If there is only one pack in the system, the HVESS parameters s...";
CM_ SG_ 2364711678 Hvesp16ElectronicsTemperature "HVESP16 Electronics Temperature: The temperature of the electronics or control modules in this High Voltage Energy Storage Pack instance.  If there are multiple temperature sensors then this parameter would be set to the maximum sensor reading.This p...";
CM_ SG_ 2364711678 Hvesp16Temperature "HVESP16 Temperature: The temperature of this High Voltage Energy Storage Pack instance. The value may be determined from a unique sensor specifically for this purpose, or by aggregating various temperature sensor readings within the pack.This paramet...";
CM_ BO_ 2364711934 "High Voltage Energy Storage Pack 16 Status 1";
CM_ SG_ 2364711934 Hvsp16HghVltgBsPstvCnttrStt "HVESP16 High-Voltage Bus (Positive) Contactor State: Position of this High Voltage Energy Storage Pack instance positive side bus contactor.  When this contactor is closed, the positive side of this HVES instance is connected to the positive side of ...";
CM_ SG_ 2364711934 Hvsp16HghVltgBsNgtvCnttrStt "HVESP16 High-Voltage Bus (Negative) Contactor State: Position of this High Voltage Energy Storage Pack instance negative side bus contactor. When this contactor is closed, the negative side of this HVES instance is connected to the negative side of t...";
CM_ SG_ 2364711934 Hvsp16HghVltgBsDsnntFrwrnng "HVESP16 High-Voltage Bus Disconnect Forewarning: Indicates that this High Voltage Energy Storage Pack instance is about to disconnect from the high voltage bus due to unacceptable conditions.This parameter is for one of multiple packs in an HVESS. If...";
CM_ SG_ 2364711934 Hvsp16HghVltgBsPrChrgRlStt "HVESP16 High-Voltage Bus Pre-Charge Relay State: Position of the high-voltage bus contactor pre-charge relay.  When this relay is closed, this High Voltage Energy Storage Pack instance is bringing the high-voltage bus up to its operating level.This p...";
CM_ SG_ 2364711934 Hvsp16CntrOfPkCnttrStt "HVESP16 Center of Pack Contactor State: Position of the center high-voltage contactor. When this contactor is closed, the positive half of this High Voltage Energy Storage Pack instance is connected to the negative half. If a system controls the posi...";
CM_ SG_ 2364711934 Hvsp16HghVltgBsAtvIsltnTstStts "HVESP16 High-Voltage Bus Active Isolation Test Status: Status of the high-voltage bus electrical active isolation test as performed by this High Voltage Energy Storage Pack instance.This parameter is for one of multiple packs in an HVESS. If there is...";
CM_ SG_ 2364711934 Hvsp16HghVltgBsPssvIsltnTstStts "HVESP16 High-Voltage Bus Passive Isolation Test Status: Status of the high-voltage bus electrical passive isolation test as performed by this High Voltage Energy Storage Pack instance.This parameter is for one of multiple packs in an HVESS. If there ...";
CM_ SG_ 2364711934 Hvesp16HvilStatus "HVESP16 HVIL Status: Status of the High Voltage Interlock Loop from the viewpoint of this High Voltage Energy Storage Pack instance.This parameter is for one of multiple packs in an HVESS. If there is only one pack in the system, the HVESS parameters...";
CM_ SG_ 2364711934 Hvesp16InertiaSwitchStatus "HVESP16 Inertia Switch Status: Switch indicating that an impact has been sensed by this High Voltage Energy Storage Pack instance. The impact indication may require action by another controller, or by this HVES instance itself.  For example, a contro...";
CM_ SG_ 2364711934 Hvesp16StateOfChargeStatus "HVESP16 State of Charge Status: Status of this High Voltage Energy Storage Pack instance State of Charge (SOC).  Note:  A given HVES controller may not support all of the states.This parameter is for one of multiple packs in an HVESS.  If there is on...";
CM_ SG_ 2364711934 Hvesp16CellBalanceStatus "HVESP16 Cell Balance Status: Indicates whether or not the cells in this High Voltage Energy Storage Pack instance are balanced.This parameter is for one of multiple packs in an HVESS.  If there is only one pack in the system, the HVESS parameters sho...";
CM_ SG_ 2364711934 Hvesp16CellBalancingActive "HVESP16 Cell Balancing Active: Indicates whether or not the cells in this High Voltage Energy Storage Pack instance are currently being balanced.This parameter is for one of multiple packs in an HVESS.  If there is only one pack in the system, the HV...";
CM_ SG_ 2364711934 Hvesp16InternalChargerStatus "HVESP16 Internal Charger Status: Indicates that the charger in this HVES instance is on.  External chargers may use the External Energy Source Connection Status (SPN 7898) and related SPs.This parameter is for one of multiple packs in an HVESS. If th...";
CM_ SG_ 2364711934 Hvsp16HghVltgBsCnntnStts "HVESP16 High-Voltage Bus Connection Status: This parameter provides high level feedback on this High Voltage Energy Storage Pack instance high voltage bus connection. For specific contactor information, see SPN 16027 (HVESP16 High-Voltage Bus (Positi...";
CM_ SG_ 2364711934 Hvesp16OperationalStatus "HVESP16 Operational Status: Provides feedback on where this High Voltage Energy Storage Pack instance is in its operating spectrum, and includes feedback in response to the Operation Consent [i.e. SPN 15985 (HVESP16 Operation Consent)] and Power Down...";
CM_ SG_ 2364711934 Hvesp16Status1Counter "HVESP16 Status 1 Counter: The message counter is used to detect situations where the transmitting ECU malfunction repeats the same frame all the time. The receiver of the information may use the counter parameter to detect this situation. The transmi...";
CM_ SG_ 2364711934 Hvesp16Status1Crc "HVESP16 Status 1 CRC: The CRC is defined as follows: - Length: 8 bits- Polynomial: x^8+x^5+x^3+x^2+x+1- Initial Value: FFh- Input Data Reflection: Not reflected- Result Data Reflection: Not reflected- XOR value: FFh SAE makes no claim of the function...";
CM_ BO_ 2364712190 "High Voltage Energy Storage Pack 16 Data 7";
CM_ SG_ 2364712190 Hvesp16DischargeEnergyCapacity "HVESP16 Discharge Energy Capacity: The amount of stored electrical energy in this High Voltage Energy Storage Pack instance that is available for use by the hybrid or EV system, i.e. 'how full is the tank'. See SPN 16014 (HVESP16 Discharge Capacity) ...";
CM_ SG_ 2364712190 Hvesp16ChargeEnergyCapacity "HVESP16 Charge Energy Capacity: The amount of unused electrical energy storage available to be filled by charging this High Voltage Energy Storage Pack instance, i.e. 'how much empty space is remaining in the tank'. See SPN 16015 (HVESP16 Charge Capa...";
CM_ SG_ 2364712190 Hvsp16MxmmChrgVltgLmt "HVESP16 Maximum Charge Voltage Limit: The maximum voltage level not to be exceeded while charging this High Voltage Energy Storage Pack instance. If this parameter is not supported, the maximum charge voltage should be limited to SPN 16113 (HVESP16 R...";
CM_ BO_ 2364712446 "High Voltage Energy Storage Pack 16 Module Status 1";
CM_ SG_ 2364712446 Hvesp16Module1OperationalStatus "HVESP16 Module 1 Operational Status: Operational Status of Module 1 in this High Voltage Energy Storage Pack Instance.  Not Operational is used when the module is initializing or not able to function (e.g. internal module level monitors have failed)....";
CM_ SG_ 2364712446 Hvesp16Module2OperationalStatus "HVESP16 Module 2 Operational Status: Operational Status of Module 2 in this High Voltage Energy Storage Pack Instance.  Not Operational is used when the module is initializing or not able to function (e.g. internal module level monitors have failed)....";
CM_ SG_ 2364712446 Hvesp16Module3OperationalStatus "HVESP16 Module 3 Operational Status: Operational Status of Module 3 in this High Voltage Energy Storage Pack Instance.  Not Operational is used when the module is initializing or not able to function (e.g. internal module level monitors have failed)....";
CM_ SG_ 2364712446 Hvesp16Module4OperationalStatus "HVESP16 Module 4 Operational Status: Operational Status of Module 4 in this High Voltage Energy Storage Pack Instance.  Not Operational is used when the module is initializing or not able to function (e.g. internal module level monitors have failed)....";
CM_ SG_ 2364712446 Hvesp16Module5OperationalStatus "HVESP16 Module 5 Operational Status: Operational Status of Module 5 in this High Voltage Energy Storage Pack Instance.  Not Operational is used when the module is initializing or not able to function (e.g. internal module level monitors have failed)....";
CM_ SG_ 2364712446 Hvesp16Module6OperationalStatus "HVESP16 Module 6 Operational Status: Operational Status of Module 6 in this High Voltage Energy Storage Pack Instance.  Not Operational is used when the module is initializing or not able to function (e.g. internal module level monitors have failed)....";
CM_ SG_ 2364712446 Hvesp16Module7OperationalStatus "HVESP16 Module 7 Operational Status: Operational Status of Module 7 in this High Voltage Energy Storage Pack Instance.  Not Operational is used when the module is initializing or not able to function (e.g. internal module level monitors have failed)....";
CM_ SG_ 2364712446 Hvesp16Module8OperationalStatus "HVESP16 Module 8 Operational Status: Operational Status of Module 8 in this High Voltage Energy Storage Pack Instance.  Not Operational is used when the module is initializing or not able to function (e.g. internal module level monitors have failed)....";
CM_ SG_ 2364712446 Hvesp16Module9OperationalStatus "HVESP16 Module 9 Operational Status: Operational Status of Module 9 in this High Voltage Energy Storage Pack Instance.  Not Operational is used when the module is initializing or not able to function (e.g. internal module level monitors have failed)....";
CM_ SG_ 2364712446 Hvsp16Mdl10OprtnlStts "HVESP16 Module 10 Operational Status: Operational Status of Module 10 in this High Voltage Energy Storage Pack Instance.  Not Operational is used when the module is initializing or not able to function (e.g. internal module level monitors have failed...";
CM_ SG_ 2364712446 Hvsp16Mdl11OprtnlStts "HVESP16 Module 11 Operational Status: Operational Status of Module 11 in this High Voltage Energy Storage Pack Instance.  Not Operational is used when the module is initializing or not able to function (e.g. internal module level monitors have failed...";
CM_ SG_ 2364712446 Hvsp16Mdl12OprtnlStts "HVESP16 Module 12 Operational Status: Operational Status of Module 12 in this High Voltage Energy Storage Pack Instance.  Not Operational is used when the module is initializing or not able to function (e.g. internal module level monitors have failed...";
CM_ SG_ 2364712446 Hvsp16Mdl13OprtnlStts "HVESP16 Module 13 Operational Status: Operational Status of Module 13 in this High Voltage Energy Storage Pack Instance.  Not Operational is used when the module is initializing or not able to function (e.g. internal module level monitors have failed...";
CM_ SG_ 2364712446 Hvsp16Mdl14OprtnlStts "HVESP16 Module 14 Operational Status: Operational Status of Module 14 in this High Voltage Energy Storage Pack Instance.  Not Operational is used when the module is initializing or not able to function (e.g. internal module level monitors have failed...";
CM_ SG_ 2364712446 Hvsp16Mdl15OprtnlStts "HVESP16 Module 15 Operational Status: Operational Status of Module 15 in this High Voltage Energy Storage Pack Instance.  Not Operational is used when the module is initializing or not able to function (e.g. internal module level monitors have failed...";
CM_ SG_ 2364712446 Hvsp16Mdl16OprtnlStts "HVESP16 Module 16 Operational Status: Operational Status of Module 16 in this High Voltage Energy Storage Pack Instance.  Not Operational is used when the module is initializing or not able to function (e.g. internal module level monitors have failed...";
CM_ SG_ 2364712446 Hvsp16Mdl17OprtnlStts "HVESP16 Module 17 Operational Status: Operational Status of Module 17 in this High Voltage Energy Storage Pack Instance.  Not Operational is used when the module is initializing or not able to function (e.g. internal module level monitors have failed...";
CM_ SG_ 2364712446 Hvsp16Mdl18OprtnlStts "HVESP16 Module 18 Operational Status: Operational Status of Module 18 in this High Voltage Energy Storage Pack Instance.  Not Operational is used when the module is initializing or not able to function (e.g. internal module level monitors have failed...";
CM_ SG_ 2364712446 Hvsp16Mdl19OprtnlStts "HVESP16 Module 19 Operational Status: Operational Status of Module 19 in this High Voltage Energy Storage Pack Instance.  Not Operational is used when the module is initializing or not able to function (e.g. internal module level monitors have failed...";
CM_ SG_ 2364712446 Hvsp16Mdl20OprtnlStts "HVESP16 Module 20 Operational Status: Operational Status of Module 20 in this High Voltage Energy Storage Pack Instance.  Not Operational is used when the module is initializing or not able to function (e.g. internal module level monitors have failed...";
CM_ SG_ 2364712446 Hvsp16Mdl21OprtnlStts "HVESP16 Module 21 Operational Status: Operational Status of Module 21 in this High Voltage Energy Storage Pack Instance.  Not Operational is used when the module is initializing or not able to function (e.g. internal module level monitors have failed...";
CM_ SG_ 2364712446 Hvsp16Mdl22OprtnlStts "HVESP16 Module 22 Operational Status: Operational Status of Module 22 in this High Voltage Energy Storage Pack Instance.  Not Operational is used when the module is initializing or not able to function (e.g. internal module level monitors have failed...";
CM_ SG_ 2364712446 Hvsp16Mdl23OprtnlStts "HVESP16 Module 23 Operational Status: Operational Status of Module 23 in this High Voltage Energy Storage Pack Instance.  Not Operational is used when the module is initializing or not able to function (e.g. internal module level monitors have failed...";
CM_ SG_ 2364712446 Hvsp16Mdl24OprtnlStts "HVESP16 Module 24 Operational Status: Operational Status of Module 24 in this High Voltage Energy Storage Pack Instance.  Not Operational is used when the module is initializing or not able to function (e.g. internal module level monitors have failed...";
CM_ SG_ 2364712446 Hvsp16Mdl25OprtnlStts "HVESP16 Module 25 Operational Status: Operational Status of Module 25 in this High Voltage Energy Storage Pack Instance.  Not Operational is used when the module is initializing or not able to function (e.g. internal module level monitors have failed...";
CM_ SG_ 2364712446 Hvsp16Mdl26OprtnlStts "HVESP16 Module 26 Operational Status: Operational Status of Module 26 in this High Voltage Energy Storage Pack Instance.  Not Operational is used when the module is initializing or not able to function (e.g. internal module level monitors have failed...";
CM_ SG_ 2364712446 Hvsp16Mdl27OprtnlStts "HVESP16 Module 27 Operational Status: Operational Status of Module 27 in this High Voltage Energy Storage Pack Instance.  Not Operational is used when the module is initializing or not able to function (e.g. internal module level monitors have failed...";
CM_ SG_ 2364712446 Hvsp16Mdl28OprtnlStts "HVESP16 Module 28 Operational Status: Operational Status of Module 28 in this High Voltage Energy Storage Pack Instance.  Not Operational is used when the module is initializing or not able to function (e.g. internal module level monitors have failed...";
CM_ SG_ 2364712446 Hvsp16Mdl29OprtnlStts "HVESP16 Module 29 Operational Status: Operational Status of Module 29 in this High Voltage Energy Storage Pack Instance.  Not Operational is used when the module is initializing or not able to function (e.g. internal module level monitors have failed...";
CM_ SG_ 2364712446 Hvsp16Mdl30OprtnlStts "HVESP16 Module 30 Operational Status: Operational Status of Module 30 in this High Voltage Energy Storage Pack Instance.  Not Operational is used when the module is initializing or not able to function (e.g. internal module level monitors have failed...";
CM_ SG_ 2364712446 Hvsp16Mdl31OprtnlStts "HVESP16 Module 31 Operational Status: Operational Status of Module 31 in this High Voltage Energy Storage Pack Instance.  Not Operational is used when the module is initializing or not able to function (e.g. internal module level monitors have failed...";
CM_ SG_ 2364712446 Hvsp16Mdl32OprtnlStts "HVESP16 Module 32 Operational Status: Operational Status of Module 32 in this High Voltage Energy Storage Pack Instance.  Not Operational is used when the module is initializing or not able to function (e.g. internal module level monitors have failed...";
CM_ BO_ 2364712702 "High Voltage Energy Storage Pack 16 Thermal Management System Status 1";
CM_ SG_ 2364712702 Hvsp16ThrmlMngmntSstmSlInptPwr "HVESP16 Thermal Management System SLI Input Power: This is the low-voltage power consumed by this HVES Thermal Management System (TMS).This parameter is for one of multiple packs in an HVESS.  If there is only one pack in the system, the HVESS parame...";
CM_ SG_ 2364712702 Hvsp16TMtSstHVtIptPw "HVESP16 Thermal Management System High-Voltage Input Power: This is the high-voltage power consumed by this HVES Thermal Management System (TMS).This parameter is for one of multiple packs in an HVESS.  If there is only one pack in the system, the HV...";
CM_ SG_ 2364712702 Hvsp16ThrmlMngmntSstmCmprssrSpd "HVESP16 Thermal Management System Compressor Speed: When this High Voltage Energy Storage Pack Thermal Management System is equipped with an active cooling system (e.g. air conditioner), this is the Compressor Speed.This parameter is for one of multi...";
CM_ SG_ 2364712702 Hvsp16ThrmlMngmntSstmRltvHmdt "HVESP16 Thermal Management System Relative Humidty: When this High Voltage Energy Storage Pack Thermal Management System is equipped with a relative humidity sensor, this is the  measured Relative Humidity.This parameter is for one of multiple packs ...";
CM_ SG_ 2364712702 Hvsp16ThrmlMngmntSstmHtrStts "HVESP16 Thermal Management System Heater Status: The state of this High Voltage Energy Storage Pack heaterThis parameter is for one of multiple packs in an HVESS.  If there is only one pack in the system, the HVESS parameters should be used. If there...";
CM_ SG_ 2364712702 Hvsp16ThrmlMngmntSstmHvlStts "HVESP16 Thermal Management System HVIL Status: In multiple HVES configurations, this is the status of the High Voltage Interlock Loop from the viewpoint of this Thermal Management System.00b = HVIL Closed01b = HVIL Open10b = Error11b = Not AvailableT...";
CM_ SG_ 2364712702 Hvsp16ThrmlMngmntSstmMd "HVESP16 Thermal Management System Mode: Indicates the operating mode of the Thermal Management System.  The heat transfer medium may be (e.g. liquid or air).  The cooling system may be fans, liquid coolant, or a combination of mediums.  The system ma...";
CM_ SG_ 2364712702 Hvsp16ThrmlMngmntSstmClntLvl "HVESP16 Thermal Management System Coolant Level: Indicates the coolant level in this HVES Thermal Management System (TMS).This parameter is for one of multiple packs in an HVESS.  If there is only one pack in the system, the HVESS parameters should b...";
CM_ BO_ 2364712958 "High Voltage Energy Storage Pack 16 Data 8";
CM_ SG_ 2364712958 Hvsp16HghstCllVltgMdlNmr "HVESP16 Highest Cell Voltage Module Number: Identifies the location of the module containing SPN 16007 (HVESP16 Highest Cell Voltage).This parameter is for one of multiple packs in an HVESS. If there is only one pack in the system, the HVESS paramete...";
CM_ SG_ 2364712958 Hvsp16HghstCllVltgCllNmr "HVESP16 Highest Cell Voltage Cell Number: Identifies the location of SPN 16007 (HVESP16 Highest Cell Voltage) within SPN 16087 (HVESP16 Highest Cell Voltage Module Number).This parameter is for one of multiple packs in an HVESS. If there is only one ...";
CM_ SG_ 2364712958 Hvsp16LwstCllVltgMdlNmr "HVESP16 Lowest Cell Voltage Module Number: Identifies the location of the module containing SPN 16008 (HVESP16 Lowest Cell Voltage).This parameter is for one of multiple packs in an HVESS. If there is only one pack in the system, the HVESS parameters...";
CM_ SG_ 2364712958 Hvsp16LwstCllVltgCllNmr "HVESP16 Lowest Cell Voltage Cell Number: Identifies the location of SPN 16008 (HVESP16 Lowest Cell Voltage) within SPN 16089 (HVESP16 Lowest Cell Voltage Module Number).This parameter is for one of multiple packs in an HVESS. If there is only one pac...";
CM_ SG_ 2364712958 Hvesp16AverageCellVoltage "HVESP16 Average Cell Voltage: The average cell voltage in this High Voltage Energy Storage Pack instance.This parameter is for one of multiple packs in an HVESS.  If there is only one pack in the system, the HVESS parameters should be used. If there ...";
CM_ BO_ 2364713214 "High Voltage Energy Storage Pack 16 Data 9";
CM_ SG_ 2364713214 Hvsp16HghstCllTmprtrMdlNmr "HVESP16 Highest Cell Temperature Module Number: Identifies the location of the module containing SPN 16010 (HVESP16 Highest Cell Temperature).This parameter is for one of multiple packs in an HVESS. If there is only one pack in the system, the HVESS ...";
CM_ SG_ 2364713214 Hvsp16HghstCllTmprtrCllNmr "HVESP16 Highest Cell Temperature Cell Number: Identifies the location of SPN 16010 (HVESP16 Highest Cell Temperature) within SPN 16092 (HVESP16 Highest Cell Temperature Module Number).This parameter is for one of multiple packs in an HVESS. If there ...";
CM_ SG_ 2364713214 Hvsp16LwstCllTmprtrMdlNmr "HVESP16 Lowest Cell Temperature Module Number: Identifies the location of the module containing SPN 16011 (HVESP16 Lowest Cell Temperature).This parameter is for one of multiple packs in an HVESS. If there is only one pack in the system, the HVESS pa...";
CM_ SG_ 2364713214 Hvsp16LwstCllTmprtrCllNmr "HVESP16 Lowest Cell Temperature Cell Number: Identifies the location of SPN 16011 (HVESP16 Lowest Cell Temperature) within SPN 16094 (HVESP16 Lowest Cell Temperature Module Number).This parameter is for one of multiple packs in an HVESS. If there is ...";
CM_ SG_ 2364713214 Hvess16ThermalEventDetected "HVESS16 Thermal Event Detected: A sensor has detected the presence of a thermal event at or near High Voltage Energy Storage Pack instance.00b = No Thermal Event Detected01b = Thermal Event Detected10b = Error11b = Not availableThis parameter is for ...";
CM_ SG_ 2364713214 Hvsp16Dt9EmdddIntgrtSpprt "HVESP16 Data 9 Embedded Integrity Support: Indicates SPN 23021 (HVESP16 Data 9 CRC) and SPN 23020 (HVESP16 Data 9 Counter) are supported by the sender.00b = Embedded CRC and Counter are supported by the sender01b = Protection is provided using an ext...";
CM_ SG_ 2364713214 Hvesp16Data9Counter "HVESP16 Data 9 Counter: The message counter is used to detect situations where the transmitting ECU malfunction repeats the same frame all the time. The receiver of the information may use the counter parameter to detect this situation. The transmitt...";
CM_ SG_ 2364713214 Hvesp16Data9Crc "HVESP16 Data 9 CRC: The CRC is defined as follows: - Length: 8 bits- Polynomial: x^8+x^5+x^3+x^2+x+1- Initial Value: FFh- Input Data Reflection: Not reflected- Result Data Reflection: Not reflected- XOR value: FFh SAE makes no claim of the functional...";
CM_ BO_ 2364713470 "High Voltage Energy Storage Pack 16 Data 10";
CM_ SG_ 2364713470 Hvsp16HghstCllSttOfChrgMdlNmr "HVESP16 Highest Cell State of Charge Module Number: Identifies the location of the module containing SPN 16020 (HVESP16 Highest Cell State of Charge).This parameter is for one of multiple packs in an HVESS. If there is only one pack in the system, th...";
CM_ SG_ 2364713470 Hvsp16HghstCllSttOfChrgCllNmr "HVESP16 Highest Cell State of Charge Cell Number: Identifies the location of SPN 16020 (HVESP16 Highest Cell State of Charge) within SPN 16096 (HVESP16 Highest Cell State of Charge Module Number).This parameter is for one of multiple packs in an HVES...";
CM_ SG_ 2364713470 Hvsp16LwstCllSttOfChrgMdlNmr "HVESP16 Lowest Cell State of Charge Module Number: Identifies the location of the module containing SPN 16019 (HVESP16 Lowest Cell State of Charge).This parameter is for one of multiple packs in an HVESS. If there is only one pack in the system, the ...";
CM_ SG_ 2364713470 Hvsp16LwstCllSttOfChrgCllNmr "HVESP16 Lowest Cell State of Charge Cell Number: Identifies the location of SPN 16019 (HVESP16 Lowest Cell State of Charge) within SPN 16098 (HVESP16 Lowest Cell State of Charge Module Number).This parameter is for one of multiple packs in an HVESS. ...";
CM_ SG_ 2364713470 Hvsp16HghVltgBsAtvIsltnTstRslts "HVESP16 High-Voltage Bus Active Isolation Test Results: The isolation resistance expressed in Ohms per Volt that resulted from the High-Voltage Bus Active Isolation Test.See SPN 16032 (HVESP16 High-Voltage Bus Active Isolation Test Status) for test s...";
CM_ SG_ 2364713470 Hvsp16HVtBsPssvIstTstRsts "HVESP16 High-Voltage Bus Passive Isolation Test Results: The isolation resistance expressed in Ohms per Volt that resulted from the High-Voltage Bus Passive Isolation Test.See SPN 16033 (HVESP16 High-Voltage Bus Passive Isolation Test Status) for tes...";
CM_ BO_ 2364713726 "High Voltage Energy Storage Pack 16 Data 11";
CM_ SG_ 2364713726 Hvsp16BsVltgNgtvTChsssGrndVltg "HVESP16 Bus Voltage Negative to Chassis Ground Voltage: Voltage difference between the most negative terminal of the HVES battery and chassis measured on the hybrid or EV system bus side (not the battery side) of any HVES contained output contactor. ...";
CM_ SG_ 2364713726 Hvsp16VltgLvlNgtvTChsssGrndVltg "HVESP16 Voltage Level Negative to Chassis Ground Voltage: Voltage difference between the most negative terminal of the HVES battery and chassis measured at the battery side of any HVES contained output contactor.  This voltage may be used for system ...";
CM_ SG_ 2364713726 Hvesp16ActualChargeRate "HVESP16 Actual Charge Rate: This signal represents the actual present charge rate of this High Voltage Energy Storage Pack instance.This parameter is for one of multiple packs in an HVESS. If there is only one pack in the system, the HVESS parameters...";
CM_ BO_ 2364713982 "High Voltage Energy Storage Pack 17 Status 2";
CM_ SG_ 2364713982 Hvsp17DshrgPwrLmtDTSttOfChrg "HVESP17 Discharge Power Limit Due to State of Charge: Indicates whether or not discharge power of this HVES instance is being limited due to state of charge.This parameter is for one of multiple packs in an HVESS.  If there is only one pack in the sy...";
CM_ SG_ 2364713982 Hvsp17DshrgPwrLmtDTBttrTmprtr "HVESP17 Discharge Power Limit Due to Battery Temperature: Indicates whether or not discharge power of this HVES instance is being limited due to battery temperature.This parameter is for one of multiple packs in an HVESS.  If there is only one pack i...";
CM_ SG_ 2364713982 Hvsp17DsPwLtDTBttDstCdt "HVESP17 Discharge Power Limit Due to Battery Diagnostic Condition: Indicates whether or not discharge power of this HVES instance is being limited due to a battery diagnostic condition.This parameter is for one of multiple packs in an HVESS.  If ther...";
CM_ SG_ 2364713982 Hvsp17DsPwLtDTBttOCVt "HVESP17 Discharge Power Limit Due to Battery or Cell Voltage: Indicates whether or not discharge power of this HVES instance is being limited due to a battery or cell voltage level.This parameter is for one of multiple packs in an HVESS.  If there is...";
CM_ SG_ 2364713982 Hvsp17DshrgPwrLmtDTBttrCrrnt "HVESP17 Discharge Power Limit Due to Battery Current: Indicates whether or not discharge power of this HVES instance is being limited due to battery current.This parameter is for one of multiple packs in an HVESS.  If there is only one pack in the sy...";
CM_ SG_ 2364713982 Hvsp17DshrgPwrLmtDTAnUndfndCs "HVESP17 Discharge Power Limit Due to an Undefined Cause: Indicates whether or not discharge power of this HVES instance is being limited due to an undefined cause.This parameter is for one of multiple packs in an HVESS.  If there is only one pack in ...";
CM_ SG_ 2364713982 Hvsp17ChrgPwrLmtDTSttOfChrg "HVESP17 Charge Power Limit Due to State of Charge: Indicates whether or not charge power of this HVES instance is being limited due to state of charge.This parameter is for one of multiple packs in an HVESS.  If there is only one pack in the system, ...";
CM_ SG_ 2364713982 Hvsp17ChrgPwrLmtDTBttrTmprtr "HVESP17 Charge Power Limit Due to Battery Temperature: Indicates whether or not charge power of this HVES instance is being limited due to battery temperature.This parameter is for one of multiple packs in an HVESS.  If there is only one pack in the ...";
CM_ SG_ 2364713982 Hvsp17CPwLtDTBttDstCdt "HVESP17 Charge Power Limit Due to Battery Diagnostic Condition: Indicates whether or not charge power of this HVES instance is being limited due to a battery diagnostic condition.This parameter is for one of multiple packs in an HVESS.  If there is o...";
CM_ SG_ 2364713982 Hvsp17ChrgPwrLmtDTBttrOrCllVltg "HVESP17 Charge Power Limit Due to Battery or Cell Voltage: Indicates whether or not charge power of this HVES instance is being limited due to a battery or cell voltage level.This parameter is for one of multiple packs in an HVESS.  If there is only ...";
CM_ SG_ 2364713982 Hvsp17ChrgPwrLmtDTBttrCrrnt "HVESP17 Charge Power Limit Due to Battery Current: Indicates whether or not charge power of this HVES instance is being limited due to battery current.This parameter is for one of multiple packs in an HVESS.  If there is only one pack in the system, ...";
CM_ SG_ 2364713982 Hvsp17ChrgPwrLmtDTAnUndfndCs "HVESP17 Charge Power Limit Due to an Undefined Cause: Indicates whether or not charge power of this HVES instance is being limited due to an undefined cause.This parameter is for one of multiple packs in an HVESS.  If there is only one pack in the sy...";
CM_ BO_ 2364714238 "High Voltage Energy Storage Pack 17 Data 1";
CM_ SG_ 2364714238 Hvesp17AvailableDischargePower "HVESP17 Available Discharge Power: The rate at which this High Voltage Energy Storage Pack instance can currently provide energy for propulsion or other uses.This parameter is for one of multiple packs in an HVESS.  If there is only one pack in the s...";
CM_ SG_ 2364714238 Hvesp17AvailableChargePower "HVESP17 Available Charge Power: The rate at which this High Voltage Energy Storage Pack instance can currently receive energy from a regenerative or recharging system.This parameter is for one of multiple packs in an HVESS.  If there is only one pack...";
CM_ SG_ 2364714238 Hvesp17VoltageLevel "HVESP17 Voltage Level: The voltage level of this High Voltage Energy Storage Pack instance. This parameter should be synchronized with SPN 16147 (HVESP17 Current) such that a realized power value can be calculated. If the HVES component physically co...";
CM_ SG_ 2364714238 Hvesp17Current "HVESP17 Current: The current in or out of this High Voltage Energy Storage Pack instance. This parameter should be synchronized with SPN 16146 (HVESP17 Voltage Level) such that a realized power value can be calculated. This parameter is defined from ...";
CM_ BO_ 2364714494 "High Voltage Energy Storage Pack 17 Data 2";
CM_ SG_ 2364714494 Hvesp17FastUpdateStateOfCharge "HVESP17 Fast Update State of Charge: Indicates this High Voltage Energy Storage Pack instance state of charge. 0% means no charge remaining, 100% means the system is fully charged in terms of physical limits of this energy storage pack instance. Acce...";
CM_ SG_ 2364714494 Hvesp17HighestCellVoltage "HVESP17 Highest Cell Voltage: The highest voltage level reported by any cell in this High Voltage Energy Storage Pack instance. If a single voltage sensor covers more than one cell, the value in this parameter is for the smallest group of cells measu...";
CM_ SG_ 2364714494 Hvesp17LowestCellVoltage "HVESP17 Lowest Cell Voltage: The lowest voltage level reported by any cell in this High Voltage Energy Storage Pack instance. If a single voltage sensor covers more than one cell, the value in this parameter is for the smallest group of cells measure...";
CM_ SG_ 2364714494 Hvsp17CllVltgDffrntlStts "HVESP17 Cell Voltage Differential Status: Indicates whether or not the differential between the highest and lowest cell voltages are within acceptable limits, according to this High Voltage Energy Storage Pack instance. The actual voltage differentia...";
CM_ BO_ 2364714750 "High Voltage Energy Storage Pack 17 Data 3";
CM_ SG_ 2364714750 Hvesp17HighestCellTemperature "HVESP17 Highest Cell Temperature: The highest temperature level reported by any cell in this High Voltage Energy Storage Pack instance. If a single temperature sensor covers more than one cell, the value in this parameter is for the smallest group of...";
CM_ SG_ 2364714750 Hvesp17LowestCellTemperature "HVESP17 Lowest Cell Temperature: The lowest temperature level reported by any cell in this High Voltage Energy Storage Pack instance. If a single temperature sensor covers more than one cell, the value in this parameter is for the smallest group of c...";
CM_ SG_ 2364714750 Hvesp17AverageCellTemperature "HVESP17 Average Cell Temperature: The average temperature level of all cells in this High Voltage Energy Storage Pack instance.This parameter is for one of multiple packs in an HVESS.  If there is only one pack in the system, the HVESS parameters sho...";
CM_ SG_ 2364714750 Hvsp17CllTmprtrDffrntlStts "HVESP17 Cell Temperature Differential Status: Indicates whether or not the differential between the highest and lowest cell temperatures are within acceptable limits per this High Voltage Energy Storage Pack instance. The actual temperature different...";
CM_ BO_ 2364715006 "High Voltage Energy Storage Pack 17 Data 4";
CM_ SG_ 2364715006 Hvesp17DischargeCapacity "HVESP17 Discharge Capacity: The amount of stored electrical charge in this High Voltage Energy Storage Pack instance that is available for use by the hybrid or EV system, i.e. 'how full is the tank'. See SPN 16186 (HVESP17 Discharge Energy Capacity) ...";
CM_ SG_ 2364715006 Hvesp17ChargeCapacity "HVESP17 Charge Capacity: The amount of unused electrical charge storage in this High Voltage Energy Storage Pack instance that is available to be filled by charging, i.e. 'how much empty space is remaining in the tank'. See SPN 16187 (HVESP17 Charge ...";
CM_ SG_ 2364715006 Hvesp17CellBalancingCount "HVESP17 Cell Balancing Count: The number of cells that are currently being balanced in this High Voltage Energy Storage Pack instance.This parameter is for one of multiple packs in an HVESS.  If there is only one pack in the system, the HVESS paramet...";
CM_ BO_ 2364715262 "High Voltage Energy Storage Pack 17 Data 5";
CM_ SG_ 2364715262 Hvesp17LowestCellStateOfCharge "HVESP17 Lowest Cell State of Charge: Indicates the state of charge of the lowest-charged cell in this High Voltage Energy Storage Pack instance. 0% means no charge remaining, 100% means the cell is fully charged. If a single state of charge value cov...";
CM_ SG_ 2364715262 Hvesp17HighestCellStateOfCharge "HVESP17 Highest Cell State of Charge: Indicates the state of charge of the highest-charged cell in this High Voltage Energy Storage Pack instance. 0% means no charge remaining, 100% means the cell is fully charged. If a single state of charge value c...";
CM_ SG_ 2364715262 Hvsp17MxmmInstntnsDshrgCrrntLmt "HVESP17 Maximum Instantaneous Discharge Current Limit: The maximum instantaneous current flow limit out of this High Voltage Energy Storage Pack instance. This parameter is defined from the high voltage energy storage pack's point of view and should ...";
CM_ SG_ 2364715262 Hvsp17MxmmInstntnsChrgCrrntLmt "HVESP17 Maximum Instantaneous Charge Current Limit: The maximum instantaneous current flow limit into this High Voltage Energy Storage Pack instance. This parameter is defined from the high voltage energy storage pack's point of view and should refle...";
CM_ BO_ 2364715518 "High Voltage Energy Storage Pack 17 Data 6";
CM_ SG_ 2364715518 Hvesp17BusVoltage "HVESP17 Bus Voltage: The voltage level of the high voltage bus, as measured by this High Voltage Energy Storage Pack instance on the bus side (not the battery side) of its contactors.This parameter is for one of multiple packs in an HVESS.  If there ...";
CM_ SG_ 2364715518 Hvesp17IgnitionVoltage "HVESP17 Ignition Voltage: The voltage level at the ignition input of this High Voltage Energy Storage Pack controller.This parameter is for one of multiple packs in an HVESS.  If there is only one pack in the system, the HVESS parameters should be us...";
CM_ SG_ 2364715518 Hvesp17IntakeCoolantTemperature "HVESP17 Intake Coolant Temperature: The temperature of liquid coolant as it enters this High Voltage Energy Storage Pack instance.This parameter is for one of multiple packs in an HVESS.  If there is only one pack in the system, the HVESS parameters ...";
CM_ SG_ 2364715518 Hvesp17OutletCoolantTemperature "HVESP17 Outlet Coolant Temperature: The temperature of liquid coolant as it exits this High Voltage Energy Storage Pack instance.This parameter is for one of multiple packs in an HVESS.  If there is only one pack in the system, the HVESS parameters s...";
CM_ SG_ 2364715518 Hvesp17ElectronicsTemperature "HVESP17 Electronics Temperature: The temperature of the electronics or control modules in this High Voltage Energy Storage Pack instance.  If there are multiple temperature sensors then this parameter would be set to the maximum sensor reading.This p...";
CM_ SG_ 2364715518 Hvesp17Temperature "HVESP17 Temperature: The temperature of this High Voltage Energy Storage Pack instance. The value may be determined from a unique sensor specifically for this purpose, or by aggregating various temperature sensor readings within the pack.This paramet...";
CM_ BO_ 2364715774 "High Voltage Energy Storage Pack 17 Status 1";
CM_ SG_ 2364715774 Hvsp17HghVltgBsPstvCnttrStt "HVESP17 High-Voltage Bus (Positive) Contactor State: Position of this High Voltage Energy Storage Pack instance positive side bus contactor.  When this contactor is closed, the positive side of this HVES instance is connected to the positive side of ...";
CM_ SG_ 2364715774 Hvsp17HghVltgBsNgtvCnttrStt "HVESP17 High-Voltage Bus (Negative) Contactor State: Position of this High Voltage Energy Storage Pack instance negative side bus contactor. When this contactor is closed, the negative side of this HVES instance is connected to the negative side of t...";
CM_ SG_ 2364715774 Hvsp17HghVltgBsDsnntFrwrnng "HVESP17 High-Voltage Bus Disconnect Forewarning: Indicates that this High Voltage Energy Storage Pack instance is about to disconnect from the high voltage bus due to unacceptable conditions.This parameter is for one of multiple packs in an HVESS. If...";
CM_ SG_ 2364715774 Hvsp17HghVltgBsPrChrgRlStt "HVESP17 High-Voltage Bus Pre-Charge Relay State: Position of the high-voltage bus contactor pre-charge relay.  When this relay is closed, this High Voltage Energy Storage Pack instance is bringing the high-voltage bus up to its operating level.This p...";
CM_ SG_ 2364715774 Hvsp17CntrOfPkCnttrStt "HVESP17 Center of Pack Contactor State: Position of the center high-voltage contactor. When this contactor is closed, the positive half of this High Voltage Energy Storage Pack instance is connected to the negative half. If a system controls the posi...";
CM_ SG_ 2364715774 Hvsp17HghVltgBsAtvIsltnTstStts "HVESP17 High-Voltage Bus Active Isolation Test Status: Status of the high-voltage bus electrical active isolation test as performed by this High Voltage Energy Storage Pack instance.This parameter is for one of multiple packs in an HVESS. If there is...";
CM_ SG_ 2364715774 Hvsp17HghVltgBsPssvIsltnTstStts "HVESP17 High-Voltage Bus Passive Isolation Test Status: Status of the high-voltage bus electrical passive isolation test as performed by this High Voltage Energy Storage Pack instance.This parameter is for one of multiple packs in an HVESS. If there ...";
CM_ SG_ 2364715774 Hvesp17HvilStatus "HVESP17 HVIL Status: Status of the High Voltage Interlock Loop from the viewpoint of this High Voltage Energy Storage Pack instance.This parameter is for one of multiple packs in an HVESS. If there is only one pack in the system, the HVESS parameters...";
CM_ SG_ 2364715774 Hvesp17InertiaSwitchStatus "HVESP17 Inertia Switch Status: Switch indicating that an impact has been sensed by this High Voltage Energy Storage Pack instance. The impact indication may require action by another controller, or by this HVES instance itself.  For example, a contro...";
CM_ SG_ 2364715774 Hvesp17StateOfChargeStatus "HVESP17 State of Charge Status: Status of this High Voltage Energy Storage Pack instance State of Charge (SOC).  Note:  A given HVES controller may not support all of the states.This parameter is for one of multiple packs in an HVESS.  If there is on...";
CM_ SG_ 2364715774 Hvesp17CellBalanceStatus "HVESP17 Cell Balance Status: Indicates whether or not the cells in this High Voltage Energy Storage Pack instance are balanced.This parameter is for one of multiple packs in an HVESS.  If there is only one pack in the system, the HVESS parameters sho...";
CM_ SG_ 2364715774 Hvesp17CellBalancingActive "HVESP17 Cell Balancing Active: Indicates whether or not the cells in this High Voltage Energy Storage Pack instance are currently being balanced.This parameter is for one of multiple packs in an HVESS.  If there is only one pack in the system, the HV...";
CM_ SG_ 2364715774 Hvesp17InternalChargerStatus "HVESP17 Internal Charger Status: Indicates that the charger in this HVES instance is on.  External chargers may use the External Energy Source Connection Status (SPN 7898) and related SPs.This parameter is for one of multiple packs in an HVESS. If th...";
CM_ SG_ 2364715774 Hvsp17HghVltgBsCnntnStts "HVESP17 High-Voltage Bus Connection Status: This parameter provides high level feedback on this High Voltage Energy Storage Pack instance high voltage bus connection. For specific contactor information, see SPN 16169 (HVESP17 High-Voltage Bus (Positi...";
CM_ SG_ 2364715774 Hvesp17OperationalStatus "HVESP17 Operational Status: Provides feedback on where this High Voltage Energy Storage Pack instance is in its operating spectrum, and includes feedback in response to the Operation Consent [i.e. SPN 16127 (HVESP17 Operation Consent)] and Power Down...";
CM_ SG_ 2364715774 Hvesp17Status1Counter "HVESP17 Status 1 Counter: The message counter is used to detect situations where the transmitting ECU malfunction repeats the same frame all the time. The receiver of the information may use the counter parameter to detect this situation. The transmi...";
CM_ SG_ 2364715774 Hvesp17Status1Crc "HVESP17 Status 1 CRC: The CRC is defined as follows: - Length: 8 bits- Polynomial: x^8+x^5+x^3+x^2+x+1- Initial Value: FFh- Input Data Reflection: Not reflected- Result Data Reflection: Not reflected- XOR value: FFh SAE makes no claim of the function...";
CM_ BO_ 2364716030 "High Voltage Energy Storage Pack 17 Data 7";
CM_ SG_ 2364716030 Hvesp17DischargeEnergyCapacity "HVESP17 Discharge Energy Capacity: The amount of stored electrical energy in this High Voltage Energy Storage Pack instance that is available for use by the hybrid or EV system, i.e. 'how full is the tank'. See SPN 16156 (HVESP17 Discharge Capacity) ...";
CM_ SG_ 2364716030 Hvesp17ChargeEnergyCapacity "HVESP17 Charge Energy Capacity: The amount of unused electrical energy storage available to be filled by charging this High Voltage Energy Storage Pack instance, i.e. 'how much empty space is remaining in the tank'. See SPN 16157 (HVESP17 Charge Capa...";
CM_ SG_ 2364716030 Hvsp17MxmmChrgVltgLmt "HVESP17 Maximum Charge Voltage Limit: The maximum voltage level not to be exceeded while charging this High Voltage Energy Storage Pack instance. If this parameter is not supported, the maximum charge voltage should be limited to SPN 16255 (HVESP17 R...";
CM_ BO_ 2364716286 "High Voltage Energy Storage Pack 17 Module Status 1";
CM_ SG_ 2364716286 Hvesp17Module1OperationalStatus "HVESP17 Module 1 Operational Status: Operational Status of Module 1 in this High Voltage Energy Storage Pack Instance.  Not Operational is used when the module is initializing or not able to function (e.g. internal module level monitors have failed)....";
CM_ SG_ 2364716286 Hvesp17Module2OperationalStatus "HVESP17 Module 2 Operational Status: Operational Status of Module 2 in this High Voltage Energy Storage Pack Instance.  Not Operational is used when the module is initializing or not able to function (e.g. internal module level monitors have failed)....";
CM_ SG_ 2364716286 Hvesp17Module3OperationalStatus "HVESP17 Module 3 Operational Status: Operational Status of Module 3 in this High Voltage Energy Storage Pack Instance.  Not Operational is used when the module is initializing or not able to function (e.g. internal module level monitors have failed)....";
CM_ SG_ 2364716286 Hvesp17Module4OperationalStatus "HVESP17 Module 4 Operational Status: Operational Status of Module 4 in this High Voltage Energy Storage Pack Instance.  Not Operational is used when the module is initializing or not able to function (e.g. internal module level monitors have failed)....";
CM_ SG_ 2364716286 Hvesp17Module5OperationalStatus "HVESP17 Module 5 Operational Status: Operational Status of Module 5 in this High Voltage Energy Storage Pack Instance.  Not Operational is used when the module is initializing or not able to function (e.g. internal module level monitors have failed)....";
CM_ SG_ 2364716286 Hvesp17Module6OperationalStatus "HVESP17 Module 6 Operational Status: Operational Status of Module 6 in this High Voltage Energy Storage Pack Instance.  Not Operational is used when the module is initializing or not able to function (e.g. internal module level monitors have failed)....";
CM_ SG_ 2364716286 Hvesp17Module7OperationalStatus "HVESP17 Module 7 Operational Status: Operational Status of Module 7 in this High Voltage Energy Storage Pack Instance.  Not Operational is used when the module is initializing or not able to function (e.g. internal module level monitors have failed)....";
CM_ SG_ 2364716286 Hvesp17Module8OperationalStatus "HVESP17 Module 8 Operational Status: Operational Status of Module 8 in this High Voltage Energy Storage Pack Instance.  Not Operational is used when the module is initializing or not able to function (e.g. internal module level monitors have failed)....";
CM_ SG_ 2364716286 Hvesp17Module9OperationalStatus "HVESP17 Module 9 Operational Status: Operational Status of Module 9 in this High Voltage Energy Storage Pack Instance.  Not Operational is used when the module is initializing or not able to function (e.g. internal module level monitors have failed)....";
CM_ SG_ 2364716286 Hvsp17Mdl10OprtnlStts "HVESP17 Module 10 Operational Status: Operational Status of Module 10 in this High Voltage Energy Storage Pack Instance.  Not Operational is used when the module is initializing or not able to function (e.g. internal module level monitors have failed...";
CM_ SG_ 2364716286 Hvsp17Mdl11OprtnlStts "HVESP17 Module 11 Operational Status: Operational Status of Module 11 in this High Voltage Energy Storage Pack Instance.  Not Operational is used when the module is initializing or not able to function (e.g. internal module level monitors have failed...";
CM_ SG_ 2364716286 Hvsp17Mdl12OprtnlStts "HVESP17 Module 12 Operational Status: Operational Status of Module 12 in this High Voltage Energy Storage Pack Instance.  Not Operational is used when the module is initializing or not able to function (e.g. internal module level monitors have failed...";
CM_ SG_ 2364716286 Hvsp17Mdl13OprtnlStts "HVESP17 Module 13 Operational Status: Operational Status of Module 13 in this High Voltage Energy Storage Pack Instance.  Not Operational is used when the module is initializing or not able to function (e.g. internal module level monitors have failed...";
CM_ SG_ 2364716286 Hvsp17Mdl14OprtnlStts "HVESP17 Module 14 Operational Status: Operational Status of Module 14 in this High Voltage Energy Storage Pack Instance.  Not Operational is used when the module is initializing or not able to function (e.g. internal module level monitors have failed...";
CM_ SG_ 2364716286 Hvsp17Mdl15OprtnlStts "HVESP17 Module 15 Operational Status: Operational Status of Module 15 in this High Voltage Energy Storage Pack Instance.  Not Operational is used when the module is initializing or not able to function (e.g. internal module level monitors have failed...";
CM_ SG_ 2364716286 Hvsp17Mdl16OprtnlStts "HVESP17 Module 16 Operational Status: Operational Status of Module 16 in this High Voltage Energy Storage Pack Instance.  Not Operational is used when the module is initializing or not able to function (e.g. internal module level monitors have failed...";
CM_ SG_ 2364716286 Hvsp17Mdl17OprtnlStts "HVESP17 Module 17 Operational Status: Operational Status of Module 17 in this High Voltage Energy Storage Pack Instance.  Not Operational is used when the module is initializing or not able to function (e.g. internal module level monitors have failed...";
CM_ SG_ 2364716286 Hvsp17Mdl18OprtnlStts "HVESP17 Module 18 Operational Status: Operational Status of Module 18 in this High Voltage Energy Storage Pack Instance.  Not Operational is used when the module is initializing or not able to function (e.g. internal module level monitors have failed...";
CM_ SG_ 2364716286 Hvsp17Mdl19OprtnlStts "HVESP17 Module 19 Operational Status: Operational Status of Module 19 in this High Voltage Energy Storage Pack Instance.  Not Operational is used when the module is initializing or not able to function (e.g. internal module level monitors have failed...";
CM_ SG_ 2364716286 Hvsp17Mdl20OprtnlStts "HVESP17 Module 20 Operational Status: Operational Status of Module 20 in this High Voltage Energy Storage Pack Instance.  Not Operational is used when the module is initializing or not able to function (e.g. internal module level monitors have failed...";
CM_ SG_ 2364716286 Hvsp17Mdl21OprtnlStts "HVESP17 Module 21 Operational Status: Operational Status of Module 21 in this High Voltage Energy Storage Pack Instance.  Not Operational is used when the module is initializing or not able to function (e.g. internal module level monitors have failed...";
CM_ SG_ 2364716286 Hvsp17Mdl22OprtnlStts "HVESP17 Module 22 Operational Status: Operational Status of Module 22 in this High Voltage Energy Storage Pack Instance.  Not Operational is used when the module is initializing or not able to function (e.g. internal module level monitors have failed...";
CM_ SG_ 2364716286 Hvsp17Mdl23OprtnlStts "HVESP17 Module 23 Operational Status: Operational Status of Module 23 in this High Voltage Energy Storage Pack Instance.  Not Operational is used when the module is initializing or not able to function (e.g. internal module level monitors have failed...";
CM_ SG_ 2364716286 Hvsp17Mdl24OprtnlStts "HVESP17 Module 24 Operational Status: Operational Status of Module 24 in this High Voltage Energy Storage Pack Instance.  Not Operational is used when the module is initializing or not able to function (e.g. internal module level monitors have failed...";
CM_ SG_ 2364716286 Hvsp17Mdl25OprtnlStts "HVESP17 Module 25 Operational Status: Operational Status of Module 25 in this High Voltage Energy Storage Pack Instance.  Not Operational is used when the module is initializing or not able to function (e.g. internal module level monitors have failed...";
CM_ SG_ 2364716286 Hvsp17Mdl26OprtnlStts "HVESP17 Module 26 Operational Status: Operational Status of Module 26 in this High Voltage Energy Storage Pack Instance.  Not Operational is used when the module is initializing or not able to function (e.g. internal module level monitors have failed...";
CM_ SG_ 2364716286 Hvsp17Mdl27OprtnlStts "HVESP17 Module 27 Operational Status: Operational Status of Module 27 in this High Voltage Energy Storage Pack Instance.  Not Operational is used when the module is initializing or not able to function (e.g. internal module level monitors have failed...";
CM_ SG_ 2364716286 Hvsp17Mdl28OprtnlStts "HVESP17 Module 28 Operational Status: Operational Status of Module 28 in this High Voltage Energy Storage Pack Instance.  Not Operational is used when the module is initializing or not able to function (e.g. internal module level monitors have failed...";
CM_ SG_ 2364716286 Hvsp17Mdl29OprtnlStts "HVESP17 Module 29 Operational Status: Operational Status of Module 29 in this High Voltage Energy Storage Pack Instance.  Not Operational is used when the module is initializing or not able to function (e.g. internal module level monitors have failed...";
CM_ SG_ 2364716286 Hvsp17Mdl30OprtnlStts "HVESP17 Module 30 Operational Status: Operational Status of Module 30 in this High Voltage Energy Storage Pack Instance.  Not Operational is used when the module is initializing or not able to function (e.g. internal module level monitors have failed...";
CM_ SG_ 2364716286 Hvsp17Mdl31OprtnlStts "HVESP17 Module 31 Operational Status: Operational Status of Module 31 in this High Voltage Energy Storage Pack Instance.  Not Operational is used when the module is initializing or not able to function (e.g. internal module level monitors have failed...";
CM_ SG_ 2364716286 Hvsp17Mdl32OprtnlStts "HVESP17 Module 32 Operational Status: Operational Status of Module 32 in this High Voltage Energy Storage Pack Instance.  Not Operational is used when the module is initializing or not able to function (e.g. internal module level monitors have failed...";
CM_ BO_ 2364716542 "High Voltage Energy Storage Pack 17 Thermal Management System Status 1";
CM_ SG_ 2364716542 Hvsp17ThrmlMngmntSstmSlInptPwr "HVESP17 Thermal Management System SLI Input Power: This is the low-voltage power consumed by this HVES Thermal Management System (TMS).This parameter is for one of multiple packs in an HVESS.  If there is only one pack in the system, the HVESS parame...";
CM_ SG_ 2364716542 Hvsp17TMtSstHVtIptPw "HVESP17 Thermal Management System High-Voltage Input Power: This is the high-voltage power consumed by this HVES Thermal Management System (TMS).This parameter is for one of multiple packs in an HVESS.  If there is only one pack in the system, the HV...";
CM_ SG_ 2364716542 Hvsp17ThrmlMngmntSstmCmprssrSpd "HVESP17 Thermal Management System Compressor Speed: When this High Voltage Energy Storage Pack Thermal Management System is equipped with an active cooling system (e.g. air conditioner), this is the Compressor Speed.This parameter is for one of multi...";
CM_ SG_ 2364716542 Hvsp17ThrmlMngmntSstmRltvHmdt "HVESP17 Thermal Management System Relative Humidty: When this High Voltage Energy Storage Pack Thermal Management System is equipped with a relative humidity sensor, this is the  measured Relative Humidity.This parameter is for one of multiple packs ...";
CM_ SG_ 2364716542 Hvsp17ThrmlMngmntSstmHtrStts "HVESP17 Thermal Management System Heater Status: The state of this High Voltage Energy Storage Pack heaterThis parameter is for one of multiple packs in an HVESS.  If there is only one pack in the system, the HVESS parameters should be used. If there...";
CM_ SG_ 2364716542 Hvsp17ThrmlMngmntSstmHvlStts "HVESP17 Thermal Management System HVIL Status: In multiple HVES configurations, this is the status of the High Voltage Interlock Loop from the viewpoint of this Thermal Management System.00b = HVIL Closed01b = HVIL Open10b = Error11b = Not AvailableT...";
CM_ SG_ 2364716542 Hvsp17ThrmlMngmntSstmMd "HVESP17 Thermal Management System Mode: Indicates the operating mode of the Thermal Management System.  The heat transfer medium may be (e.g. liquid or air).  The cooling system may be fans, liquid coolant, or a combination of mediums.  The system ma...";
CM_ SG_ 2364716542 Hvsp17ThrmlMngmntSstmClntLvl "HVESP17 Thermal Management System Coolant Level: Indicates the coolant level in this HVES Thermal Management System (TMS).This parameter is for one of multiple packs in an HVESS.  If there is only one pack in the system, the HVESS parameters should b...";
CM_ BO_ 2364716798 "High Voltage Energy Storage Pack 17 Data 8";
CM_ SG_ 2364716798 Hvsp17HghstCllVltgMdlNmr "HVESP17 Highest Cell Voltage Module Number: Identifies the location of the module containing SPN 16149 (HVESP17 Highest Cell Voltage).This parameter is for one of multiple packs in an HVESS. If there is only one pack in the system, the HVESS paramete...";
CM_ SG_ 2364716798 Hvsp17HghstCllVltgCllNmr "HVESP17 Highest Cell Voltage Cell Number: Identifies the location of SPN 16149 (HVESP17 Highest Cell Voltage) within SPN 16229 (HVESP17 Highest Cell Voltage Module Number).This parameter is for one of multiple packs in an HVESS. If there is only one ...";
CM_ SG_ 2364716798 Hvsp17LwstCllVltgMdlNmr "HVESP17 Lowest Cell Voltage Module Number: Identifies the location of the module containing SPN 16150 (HVESP17 Lowest Cell Voltage).This parameter is for one of multiple packs in an HVESS. If there is only one pack in the system, the HVESS parameters...";
CM_ SG_ 2364716798 Hvsp17LwstCllVltgCllNmr "HVESP17 Lowest Cell Voltage Cell Number: Identifies the location of SPN 16150 (HVESP17 Lowest Cell Voltage) within SPN 16231 (HVESP17 Lowest Cell Voltage Module Number).This parameter is for one of multiple packs in an HVESS. If there is only one pac...";
CM_ SG_ 2364716798 Hvesp17AverageCellVoltage "HVESP17 Average Cell Voltage: The average cell voltage in this High Voltage Energy Storage Pack instance.This parameter is for one of multiple packs in an HVESS.  If there is only one pack in the system, the HVESS parameters should be used. If there ...";
CM_ BO_ 2364717054 "High Voltage Energy Storage Pack 17 Data 9";
CM_ SG_ 2364717054 Hvsp17HghstCllTmprtrMdlNmr "HVESP17 Highest Cell Temperature Module Number: Identifies the location of the module containing SPN 16152 (HVESP17 Highest Cell Temperature).This parameter is for one of multiple packs in an HVESS. If there is only one pack in the system, the HVESS ...";
CM_ SG_ 2364717054 Hvsp17HghstCllTmprtrCllNmr "HVESP17 Highest Cell Temperature Cell Number: Identifies the location of SPN 16152 (HVESP17 Highest Cell Temperature) within SPN 16234 (HVESP17 Highest Cell Temperature Module Number).This parameter is for one of multiple packs in an HVESS. If there ...";
CM_ SG_ 2364717054 Hvsp17LwstCllTmprtrMdlNmr "HVESP17 Lowest Cell Temperature Module Number: Identifies the location of the module containing SPN 16153 (HVESP17 Lowest Cell Temperature).This parameter is for one of multiple packs in an HVESS. If there is only one pack in the system, the HVESS pa...";
CM_ SG_ 2364717054 Hvsp17LwstCllTmprtrCllNmr "HVESP17 Lowest Cell Temperature Cell Number: Identifies the location of SPN 16153 (HVESP17 Lowest Cell Temperature) within SPN 16236 (HVESP17 Lowest Cell Temperature Module Number).This parameter is for one of multiple packs in an HVESS. If there is ...";
CM_ SG_ 2364717054 Hvess17ThermalEventDetected "HVESS17 Thermal Event Detected: A sensor has detected the presence of a thermal event at or near High Voltage Energy Storage Pack instance.00b = No Thermal Event Detected01b = Thermal Event Detected10b = Error11b = Not availableThis parameter is for ...";
CM_ SG_ 2364717054 Hvsp17Dt9EmdddIntgrtSpprt "HVESP17 Data 9 Embedded Integrity Support: Indicates SPN 23024 (HVESP17 Data 9 CRC) and SPN 23023 (HVESP17 Data 9 Counter) are supported by the sender.00b = Embedded CRC and Counter are supported by the sender01b = Protection is provided using an ext...";
CM_ SG_ 2364717054 Hvesp17Data9Counter "HVESP17 Data 9 Counter: The message counter is used to detect situations where the transmitting ECU malfunction repeats the same frame all the time. The receiver of the information may use the counter parameter to detect this situation. The transmitt...";
CM_ SG_ 2364717054 Hvesp17Data9Crc "HVESP17 Data 9 CRC: The CRC is defined as follows: - Length: 8 bits- Polynomial: x^8+x^5+x^3+x^2+x+1- Initial Value: FFh- Input Data Reflection: Not reflected- Result Data Reflection: Not reflected- XOR value: FFh SAE makes no claim of the functional...";
CM_ BO_ 2364717310 "High Voltage Energy Storage Pack 17 Data 10";
CM_ SG_ 2364717310 Hvsp17HghstCllSttOfChrgMdlNmr "HVESP17 Highest Cell State of Charge Module Number: Identifies the location of the module containing SPN 16162 (HVESP17 Highest Cell State of Charge).This parameter is for one of multiple packs in an HVESS. If there is only one pack in the system, th...";
CM_ SG_ 2364717310 Hvsp17HghstCllSttOfChrgCllNmr "HVESP17 Highest Cell State of Charge Cell Number: Identifies the location of SPN 16162 (HVESP17 Highest Cell State of Charge) within SPN 16238 (HVESP17 Highest Cell State of Charge Module Number).This parameter is for one of multiple packs in an HVES...";
CM_ SG_ 2364717310 Hvsp17LwstCllSttOfChrgMdlNmr "HVESP17 Lowest Cell State of Charge Module Number: Identifies the location of the module containing SPN 16161 (HVESP17 Lowest Cell State of Charge).This parameter is for one of multiple packs in an HVESS. If there is only one pack in the system, the ...";
CM_ SG_ 2364717310 Hvsp17LwstCllSttOfChrgCllNmr "HVESP17 Lowest Cell State of Charge Cell Number: Identifies the location of SPN 16161 (HVESP17 Lowest Cell State of Charge) within SPN 16240 (HVESP17 Lowest Cell State of Charge Module Number).This parameter is for one of multiple packs in an HVESS. ...";
CM_ SG_ 2364717310 Hvsp17HghVltgBsAtvIsltnTstRslts "HVESP17 High-Voltage Bus Active Isolation Test Results: The isolation resistance expressed in Ohms per Volt that resulted from the High-Voltage Bus Active Isolation Test.See SPN 16174 (HVESP17 High-Voltage Bus Active Isolation Test Status) for test s...";
CM_ SG_ 2364717310 Hvsp17HVtBsPssvIstTstRsts "HVESP17 High-Voltage Bus Passive Isolation Test Results: The isolation resistance expressed in Ohms per Volt that resulted from the High-Voltage Bus Passive Isolation Test.See SPN 16175 (HVESP17 High-Voltage Bus Passive Isolation Test Status) for tes...";
CM_ BO_ 2364717566 "High Voltage Energy Storage Pack 17 Data 11";
CM_ SG_ 2364717566 Hvsp17BsVltgNgtvTChsssGrndVltg "HVESP17 Bus Voltage Negative to Chassis Ground Voltage: Voltage difference between the most negative terminal of the HVES battery and chassis measured on the hybrid or EV system bus side (not the battery side) of any HVES contained output contactor. ...";
CM_ SG_ 2364717566 Hvsp17VltgLvlNgtvTChsssGrndVltg "HVESP17 Voltage Level Negative to Chassis Ground Voltage: Voltage difference between the most negative terminal of the HVES battery and chassis measured at the battery side of any HVES contained output contactor.  This voltage may be used for system ...";
CM_ SG_ 2364717566 Hvesp17ActualChargeRate "HVESP17 Actual Charge Rate: This signal represents the actual present charge rate of this High Voltage Energy Storage Pack instance.This parameter is for one of multiple packs in an HVESS. If there is only one pack in the system, the HVESS parameters...";
CM_ BO_ 2364717822 "High Voltage Energy Storage Pack 18 Status 2";
CM_ SG_ 2364717822 Hvsp18DshrgPwrLmtDTSttOfChrg "HVESP18 Discharge Power Limit Due to State of Charge: Indicates whether or not discharge power of this HVES instance is being limited due to state of charge.This parameter is for one of multiple packs in an HVESS.  If there is only one pack in the sy...";
CM_ SG_ 2364717822 Hvsp18DshrgPwrLmtDTBttrTmprtr "HVESP18 Discharge Power Limit Due to Battery Temperature: Indicates whether or not discharge power of this HVES instance is being limited due to battery temperature.This parameter is for one of multiple packs in an HVESS.  If there is only one pack i...";
CM_ SG_ 2364717822 Hvsp18DsPwLtDTBttDstCdt "HVESP18 Discharge Power Limit Due to Battery Diagnostic Condition: Indicates whether or not discharge power of this HVES instance is being limited due to a battery diagnostic condition.This parameter is for one of multiple packs in an HVESS.  If ther...";
CM_ SG_ 2364717822 Hvsp18DsPwLtDTBttOCVt "HVESP18 Discharge Power Limit Due to Battery or Cell Voltage: Indicates whether or not discharge power of this HVES instance is being limited due to a battery or cell voltage level.This parameter is for one of multiple packs in an HVESS.  If there is...";
CM_ SG_ 2364717822 Hvsp18DshrgPwrLmtDTBttrCrrnt "HVESP18 Discharge Power Limit Due to Battery Current: Indicates whether or not discharge power of this HVES instance is being limited due to battery current.This parameter is for one of multiple packs in an HVESS.  If there is only one pack in the sy...";
CM_ SG_ 2364717822 Hvsp18DshrgPwrLmtDTAnUndfndCs "HVESP18 Discharge Power Limit Due to an Undefined Cause: Indicates whether or not discharge power of this HVES instance is being limited due to an undefined cause.This parameter is for one of multiple packs in an HVESS.  If there is only one pack in ...";
CM_ SG_ 2364717822 Hvsp18ChrgPwrLmtDTSttOfChrg "HVESP18 Charge Power Limit Due to State of Charge: Indicates whether or not charge power of this HVES instance is being limited due to state of charge.This parameter is for one of multiple packs in an HVESS.  If there is only one pack in the system, ...";
CM_ SG_ 2364717822 Hvsp18ChrgPwrLmtDTBttrTmprtr "HVESP18 Charge Power Limit Due to Battery Temperature: Indicates whether or not charge power of this HVES instance is being limited due to battery temperature.This parameter is for one of multiple packs in an HVESS.  If there is only one pack in the ...";
CM_ SG_ 2364717822 Hvsp18CPwLtDTBttDstCdt "HVESP18 Charge Power Limit Due to Battery Diagnostic Condition: Indicates whether or not charge power of this HVES instance is being limited due to a battery diagnostic condition.This parameter is for one of multiple packs in an HVESS.  If there is o...";
CM_ SG_ 2364717822 Hvsp18ChrgPwrLmtDTBttrOrCllVltg "HVESP18 Charge Power Limit Due to Battery or Cell Voltage: Indicates whether or not charge power of this HVES instance is being limited due to a battery or cell voltage level.This parameter is for one of multiple packs in an HVESS.  If there is only ...";
CM_ SG_ 2364717822 Hvsp18ChrgPwrLmtDTBttrCrrnt "HVESP18 Charge Power Limit Due to Battery Current: Indicates whether or not charge power of this HVES instance is being limited due to battery current.This parameter is for one of multiple packs in an HVESS.  If there is only one pack in the system, ...";
CM_ SG_ 2364717822 Hvsp18ChrgPwrLmtDTAnUndfndCs "HVESP18 Charge Power Limit Due to an Undefined Cause: Indicates whether or not charge power of this HVES instance is being limited due to an undefined cause.This parameter is for one of multiple packs in an HVESS.  If there is only one pack in the sy...";
CM_ BO_ 2364718078 "High Voltage Energy Storage Pack 18 Data 1";
CM_ SG_ 2364718078 Hvesp18AvailableDischargePower "HVESP18 Available Discharge Power: The rate at which this High Voltage Energy Storage Pack instance can currently provide energy for propulsion or other uses.This parameter is for one of multiple packs in an HVESS.  If there is only one pack in the s...";
CM_ SG_ 2364718078 Hvesp18AvailableChargePower "HVESP18 Available Charge Power: The rate at which this High Voltage Energy Storage Pack instance can currently receive energy from a regenerative or recharging system.This parameter is for one of multiple packs in an HVESS.  If there is only one pack...";
CM_ SG_ 2364718078 Hvesp18VoltageLevel "HVESP18 Voltage Level: The voltage level of this High Voltage Energy Storage Pack instance. This parameter should be synchronized with SPN 16289 (HVESP18 Current) such that a realized power value can be calculated. If the HVES component physically co...";
CM_ SG_ 2364718078 Hvesp18Current "HVESP18 Current: The current in or out of this High Voltage Energy Storage Pack instance. This parameter should be synchronized with SPN 16288 (HVESP18 Voltage Level) such that a realized power value can be calculated. This parameter is defined from ...";
CM_ BO_ 2364718334 "High Voltage Energy Storage Pack 18 Data 2";
CM_ SG_ 2364718334 Hvesp18FastUpdateStateOfCharge "HVESP18 Fast Update State of Charge: Indicates this High Voltage Energy Storage Pack instance state of charge. 0% means no charge remaining, 100% means the system is fully charged in terms of physical limits of this energy storage pack instance. Acce...";
CM_ SG_ 2364718334 Hvesp18HighestCellVoltage "HVESP18 Highest Cell Voltage: The highest voltage level reported by any cell in this High Voltage Energy Storage Pack instance. If a single voltage sensor covers more than one cell, the value in this parameter is for the smallest group of cells measu...";
CM_ SG_ 2364718334 Hvesp18LowestCellVoltage "HVESP18 Lowest Cell Voltage: The lowest voltage level reported by any cell in this High Voltage Energy Storage Pack instance. If a single voltage sensor covers more than one cell, the value in this parameter is for the smallest group of cells measure...";
CM_ SG_ 2364718334 Hvsp18CllVltgDffrntlStts "HVESP18 Cell Voltage Differential Status: Indicates whether or not the differential between the highest and lowest cell voltages are within acceptable limits, according to this High Voltage Energy Storage Pack instance. The actual voltage differentia...";
BA_DEF_ SG_  "SPN" INT 0 524287;
BA_DEF_ BO_  "VFrameFormat" ENUM  "StandardCAN","ExtendedCAN","reserved","J1939PG";
BA_DEF_DEF_  "SPN" 0;
BA_DEF_DEF_  "VFrameFormat" "J1939PG";
BA_ "SPN" SG_ 2364704766 Hvesp14Module1OperationalStatus 15763;
BA_ "SPN" SG_ 2364704766 Hvesp14Module2OperationalStatus 15764;
BA_ "SPN" SG_ 2364704766 Hvesp14Module3OperationalStatus 15765;
BA_ "SPN" SG_ 2364704766 Hvesp14Module4OperationalStatus 15766;
BA_ "SPN" SG_ 2364704766 Hvesp14Module5OperationalStatus 15767;
BA_ "SPN" SG_ 2364704766 Hvesp14Module6OperationalStatus 15768;
BA_ "SPN" SG_ 2364704766 Hvesp14Module7OperationalStatus 15769;
BA_ "SPN" SG_ 2364704766 Hvesp14Module8OperationalStatus 15770;
BA_ "SPN" SG_ 2364704766 Hvesp14Module9OperationalStatus 15771;
BA_ "SPN" SG_ 2364704766 Hvsp14Mdl10OprtnlStts 15772;
BA_ "SPN" SG_ 2364704766 Hvsp14Mdl11OprtnlStts 15773;
BA_ "SPN" SG_ 2364704766 Hvsp14Mdl12OprtnlStts 15774;
BA_ "SPN" SG_ 2364704766 Hvsp14Mdl13OprtnlStts 15775;
BA_ "SPN" SG_ 2364704766 Hvsp14Mdl14OprtnlStts 15776;
BA_ "SPN" SG_ 2364704766 Hvsp14Mdl15OprtnlStts 15777;
BA_ "SPN" SG_ 2364704766 Hvsp14Mdl16OprtnlStts 15778;
BA_ "SPN" SG_ 2364704766 Hvsp14Mdl17OprtnlStts 15779;
BA_ "SPN" SG_ 2364704766 Hvsp14Mdl18OprtnlStts 15780;
BA_ "SPN" SG_ 2364704766 Hvsp14Mdl19OprtnlStts 15781;
BA_ "SPN" SG_ 2364704766 Hvsp14Mdl20OprtnlStts 15782;
BA_ "SPN" SG_ 2364704766 Hvsp14Mdl21OprtnlStts 15783;
BA_ "SPN" SG_ 2364704766 Hvsp14Mdl22OprtnlStts 15784;
BA_ "SPN" SG_ 2364704766 Hvsp14Mdl23OprtnlStts 15785;
BA_ "SPN" SG_ 2364704766 Hvsp14Mdl24OprtnlStts 15786;
BA_ "SPN" SG_ 2364704766 Hvsp14Mdl25OprtnlStts 15787;
BA_ "SPN" SG_ 2364704766 Hvsp14Mdl26OprtnlStts 15788;
BA_ "SPN" SG_ 2364704766 Hvsp14Mdl27OprtnlStts 15789;
BA_ "SPN" SG_ 2364704766 Hvsp14Mdl28OprtnlStts 15790;
BA_ "SPN" SG_ 2364704766 Hvsp14Mdl29OprtnlStts 15791;
BA_ "SPN" SG_ 2364704766 Hvsp14Mdl30OprtnlStts 15792;
BA_ "SPN" SG_ 2364704766 Hvsp14Mdl31OprtnlStts 15793;
BA_ "SPN" SG_ 2364704766 Hvsp14Mdl32OprtnlStts 15794;
BA_ "SPN" SG_ 2364705022 Hvsp14ThrmlMngmntSstmSlInptPwr 15795;
BA_ "SPN" SG_ 2364705022 Hvsp14TMtSstHVtIptPw 15796;
BA_ "SPN" SG_ 2364705022 Hvsp14ThrmlMngmntSstmCmprssrSpd 15797;
BA_ "SPN" SG_ 2364705022 Hvsp14ThrmlMngmntSstmRltvHmdt 15798;
BA_ "SPN" SG_ 2364705022 Hvsp14ThrmlMngmntSstmHtrStts 15799;
BA_ "SPN" SG_ 2364705022 Hvsp14ThrmlMngmntSstmHvlStts 15800;
BA_ "SPN" SG_ 2364705022 Hvsp14ThrmlMngmntSstmMd 15801;
BA_ "SPN" SG_ 2364705022 Hvsp14ThrmlMngmntSstmClntLvl 15802;
BA_ "SPN" SG_ 2364705278 Hvsp14HghstCllVltgMdlNmr 15803;
BA_ "SPN" SG_ 2364705278 Hvsp14HghstCllVltgCllNmr 15804;
BA_ "SPN" SG_ 2364705278 Hvsp14LwstCllVltgMdlNmr 15805;
BA_ "SPN" SG_ 2364705278 Hvsp14LwstCllVltgCllNmr 15806;
BA_ "SPN" SG_ 2364705278 Hvesp14AverageCellVoltage 15807;
BA_ "SPN" SG_ 2364705534 Hvsp14HghstCllTmprtrMdlNmr 15808;
BA_ "SPN" SG_ 2364705534 Hvsp14HghstCllTmprtrCllNmr 15809;
BA_ "SPN" SG_ 2364705534 Hvsp14LwstCllTmprtrMdlNmr 15810;
BA_ "SPN" SG_ 2364705534 Hvsp14LwstCllTmprtrCllNmr 15811;
BA_ "SPN" SG_ 2364705534 Hvess14ThermalEventDetected 21301;
BA_ "SPN" SG_ 2364705534 Hvsp14Dt9EmdddIntgrtSpprt 23013;
BA_ "SPN" SG_ 2364705534 Hvesp14Data9Counter 23014;
BA_ "SPN" SG_ 2364705534 Hvesp14Data9Crc 23015;
BA_ "SPN" SG_ 2364705790 Hvsp14HghstCllSttOfChrgMdlNmr 15812;
BA_ "SPN" SG_ 2364705790 Hvsp14HghstCllSttOfChrgCllNmr 15813;
BA_ "SPN" SG_ 2364705790 Hvsp14LwstCllSttOfChrgMdlNmr 15814;
BA_ "SPN" SG_ 2364705790 Hvsp14LwstCllSttOfChrgCllNmr 15815;
BA_ "SPN" SG_ 2364705790 Hvsp14HghVltgBsAtvIsltnTstRslts 15816;
BA_ "SPN" SG_ 2364705790 Hvsp14HVtBsPssvIstTstRsts 15817;
BA_ "SPN" SG_ 2364706046 Hvsp14BsVltgNgtvTChsssGrndVltg 15818;
BA_ "SPN" SG_ 2364706046 Hvsp14VltgLvlNgtvTChsssGrndVltg 15819;
BA_ "SPN" SG_ 2364706046 Hvesp14ActualChargeRate 15820;
BA_ "SPN" SG_ 2364706302 Hvsp15DshrgPwrLmtDTSttOfChrg 15848;
BA_ "SPN" SG_ 2364706302 Hvsp15DshrgPwrLmtDTBttrTmprtr 15849;
BA_ "SPN" SG_ 2364706302 Hvsp15DsPwLtDTBttDstCdt 15850;
BA_ "SPN" SG_ 2364706302 Hvsp15DsPwLtDTBttOCVt 15851;
BA_ "SPN" SG_ 2364706302 Hvsp15DshrgPwrLmtDTBttrCrrnt 15852;
BA_ "SPN" SG_ 2364706302 Hvsp15DshrgPwrLmtDTAnUndfndCs 15853;
BA_ "SPN" SG_ 2364706302 Hvsp15ChrgPwrLmtDTSttOfChrg 15854;
BA_ "SPN" SG_ 2364706302 Hvsp15ChrgPwrLmtDTBttrTmprtr 15855;
BA_ "SPN" SG_ 2364706302 Hvsp15CPwLtDTBttDstCdt 15856;
BA_ "SPN" SG_ 2364706302 Hvsp15ChrgPwrLmtDTBttrOrCllVltg 15857;
BA_ "SPN" SG_ 2364706302 Hvsp15ChrgPwrLmtDTBttrCrrnt 15858;
BA_ "SPN" SG_ 2364706302 Hvsp15ChrgPwrLmtDTAnUndfndCs 15859;
BA_ "SPN" SG_ 2364706558 Hvesp15AvailableDischargePower 15860;
BA_ "SPN" SG_ 2364706558 Hvesp15AvailableChargePower 15861;
BA_ "SPN" SG_ 2364706558 Hvesp15VoltageLevel 15862;
BA_ "SPN" SG_ 2364706558 Hvesp15Current 15863;
BA_ "SPN" SG_ 2364706814 Hvesp15FastUpdateStateOfCharge 15864;
BA_ "SPN" SG_ 2364706814 Hvesp15HighestCellVoltage 15865;
BA_ "SPN" SG_ 2364706814 Hvesp15LowestCellVoltage 15866;
BA_ "SPN" SG_ 2364706814 Hvsp15CllVltgDffrntlStts 15867;
BA_ "SPN" SG_ 2364707070 Hvesp15HighestCellTemperature 15868;
BA_ "SPN" SG_ 2364707070 Hvesp15LowestCellTemperature 15869;
BA_ "SPN" SG_ 2364707070 Hvesp15AverageCellTemperature 15870;
BA_ "SPN" SG_ 2364707070 Hvsp15CllTmprtrDffrntlStts 15871;
BA_ "SPN" SG_ 2364707326 Hvesp15DischargeCapacity 15872;
BA_ "SPN" SG_ 2364707326 Hvesp15ChargeCapacity 15873;
BA_ "SPN" SG_ 2364707326 Hvesp15CellBalancingCount 15874;
BA_ "SPN" SG_ 2364707582 Hvesp15LowestCellStateOfCharge 15877;
BA_ "SPN" SG_ 2364707582 Hvesp15HighestCellStateOfCharge 15878;
BA_ "SPN" SG_ 2364707582 Hvsp15MxmmInstntnsDshrgCrrntLmt 15875;
BA_ "SPN" SG_ 2364707582 Hvsp15MxmmInstntnsChrgCrrntLmt 15876;
BA_ "SPN" SG_ 2364707838 Hvesp15BusVoltage 15879;
BA_ "SPN" SG_ 2364707838 Hvesp15IgnitionVoltage 15880;
BA_ "SPN" SG_ 2364707838 Hvesp15IntakeCoolantTemperature 15881;
BA_ "SPN" SG_ 2364707838 Hvesp15OutletCoolantTemperature 15882;
BA_ "SPN" SG_ 2364707838 Hvesp15ElectronicsTemperature 15883;
BA_ "SPN" SG_ 2364707838 Hvesp15Temperature 15884;
BA_ "SPN" SG_ 2364708094 Hvsp15HghVltgBsPstvCnttrStt 15885;
BA_ "SPN" SG_ 2364708094 Hvsp15HghVltgBsNgtvCnttrStt 15886;
BA_ "SPN" SG_ 2364708094 Hvsp15HghVltgBsDsnntFrwrnng 15887;
BA_ "SPN" SG_ 2364708094 Hvsp15HghVltgBsPrChrgRlStt 15888;
BA_ "SPN" SG_ 2364708094 Hvsp15CntrOfPkCnttrStt 15889;
BA_ "SPN" SG_ 2364708094 Hvsp15HghVltgBsAtvIsltnTstStts 15890;
BA_ "SPN" SG_ 2364708094 Hvsp15HghVltgBsPssvIsltnTstStts 15891;
BA_ "SPN" SG_ 2364708094 Hvesp15HvilStatus 15892;
BA_ "SPN" SG_ 2364708094 Hvesp15InertiaSwitchStatus 15893;
BA_ "SPN" SG_ 2364708094 Hvesp15StateOfChargeStatus 15894;
BA_ "SPN" SG_ 2364708094 Hvesp15CellBalanceStatus 15895;
BA_ "SPN" SG_ 2364708094 Hvesp15CellBalancingActive 15896;
BA_ "SPN" SG_ 2364708094 Hvesp15InternalChargerStatus 15897;
BA_ "SPN" SG_ 2364708094 Hvsp15HghVltgBsCnntnStts 15898;
BA_ "SPN" SG_ 2364708094 Hvesp15OperationalStatus 15899;
BA_ "SPN" SG_ 2364708094 Hvesp15Status1Counter 15900;
BA_ "SPN" SG_ 2364708094 Hvesp15Status1Crc 15901;
BA_ "SPN" SG_ 2364708350 Hvesp15DischargeEnergyCapacity 15902;
BA_ "SPN" SG_ 2364708350 Hvesp15ChargeEnergyCapacity 15903;
BA_ "SPN" SG_ 2364708350 Hvsp15MxmmChrgVltgLmt 15904;
BA_ "SPN" SG_ 2364708606 Hvesp15Module1OperationalStatus 15905;
BA_ "SPN" SG_ 2364708606 Hvesp15Module2OperationalStatus 15906;
BA_ "SPN" SG_ 2364708606 Hvesp15Module3OperationalStatus 15907;
BA_ "SPN" SG_ 2364708606 Hvesp15Module4OperationalStatus 15908;
BA_ "SPN" SG_ 2364708606 Hvesp15Module5OperationalStatus 15909;
BA_ "SPN" SG_ 2364708606 Hvesp15Module6OperationalStatus 15910;
BA_ "SPN" SG_ 2364708606 Hvesp15Module7OperationalStatus 15911;
BA_ "SPN" SG_ 2364708606 Hvesp15Module8OperationalStatus 15912;
BA_ "SPN" SG_ 2364708606 Hvesp15Module9OperationalStatus 15913;
BA_ "SPN" SG_ 2364708606 Hvsp15Mdl10OprtnlStts 15914;
BA_ "SPN" SG_ 2364708606 Hvsp15Mdl11OprtnlStts 15915;
BA_ "SPN" SG_ 2364708606 Hvsp15Mdl12OprtnlStts 15916;
BA_ "SPN" SG_ 2364708606 Hvsp15Mdl13OprtnlStts 15917;
BA_ "SPN" SG_ 2364708606 Hvsp15Mdl14OprtnlStts 15918;
BA_ "SPN" SG_ 2364708606 Hvsp15Mdl15OprtnlStts 15919;
BA_ "SPN" SG_ 2364708606 Hvsp15Mdl16OprtnlStts 15920;
BA_ "SPN" SG_ 2364708606 Hvsp15Mdl17OprtnlStts 15921;
BA_ "SPN" SG_ 2364708606 Hvsp15Mdl18OprtnlStts 15922;
BA_ "SPN" SG_ 2364708606 Hvsp15Mdl19OprtnlStts 15923;
BA_ "SPN" SG_ 2364708606 Hvsp15Mdl20OprtnlStts 15924;
BA_ "SPN" SG_ 2364708606 Hvsp15Mdl21OprtnlStts 15925;
BA_ "SPN" SG_ 2364708606 Hvsp15Mdl22OprtnlStts 15926;
BA_ "SPN" SG_ 2364708606 Hvsp15Mdl23OprtnlStts 15927;
BA_ "SPN" SG_ 2364708606 Hvsp15Mdl24OprtnlStts 15928;
BA_ "SPN" SG_ 2364708606 Hvsp15Mdl25OprtnlStts 15929;
BA_ "SPN" SG_ 2364708606 Hvsp15Mdl26OprtnlStts 15930;
BA_ "SPN" SG_ 2364708606 Hvsp15Mdl27OprtnlStts 15931;
BA_ "SPN" SG_ 2364708606 Hvsp15Mdl28OprtnlStts 15932;
BA_ "SPN" SG_ 2364708606 Hvsp15Mdl29OprtnlStts 15933;
BA_ "SPN" SG_ 2364708606 Hvsp15Mdl30OprtnlStts 15934;
BA_ "SPN" SG_ 2364708606 Hvsp15Mdl31OprtnlStts 15935;
BA_ "SPN" SG_ 2364708606 Hvsp15Mdl32OprtnlStts 15936;
BA_ "SPN" SG_ 2364708862 Hvsp15ThrmlMngmntSstmSlInptPwr 15937;
BA_ "SPN" SG_ 2364708862 Hvsp15TMtSstHVtIptPw 15938;
BA_ "SPN" SG_ 2364708862 Hvsp15ThrmlMngmntSstmCmprssrSpd 15939;
BA_ "SPN" SG_ 2364708862 Hvsp15ThrmlMngmntSstmRltvHmdt 15940;
BA_ "SPN" SG_ 2364708862 Hvsp15ThrmlMngmntSstmHtrStts 15941;
BA_ "SPN" SG_ 2364708862 Hvsp15ThrmlMngmntSstmHvlStts 15942;
BA_ "SPN" SG_ 2364708862 Hvsp15ThrmlMngmntSstmMd 15943;
BA_ "SPN" SG_ 2364708862 Hvsp15ThrmlMngmntSstmClntLvl 15944;
BA_ "SPN" SG_ 2364709118 Hvsp15HghstCllVltgMdlNmr 15945;
BA_ "SPN" SG_ 2364709118 Hvsp15HghstCllVltgCllNmr 15946;
BA_ "SPN" SG_ 2364709118 Hvsp15LwstCllVltgMdlNmr 15947;
BA_ "SPN" SG_ 2364709118 Hvsp15LwstCllVltgCllNmr 15948;
BA_ "SPN" SG_ 2364709118 Hvesp15AverageCellVoltage 15949;
BA_ "SPN" SG_ 2364709374 Hvsp15HghstCllTmprtrMdlNmr 15950;
BA_ "SPN" SG_ 2364709374 Hvsp15HghstCllTmprtrCllNmr 15951;
BA_ "SPN" SG_ 2364709374 Hvsp15LwstCllTmprtrMdlNmr 15952;
BA_ "SPN" SG_ 2364709374 Hvsp15LwstCllTmprtrCllNmr 15953;
BA_ "SPN" SG_ 2364709374 Hvess15ThermalEventDetected 21302;
BA_ "SPN" SG_ 2364709374 Hvsp15Dt9EmdddIntgrtSpprt 23016;
BA_ "SPN" SG_ 2364709374 Hvesp15Data9Counter 23017;
BA_ "SPN" SG_ 2364709374 Hvesp15Data9Crc 23018;
BA_ "SPN" SG_ 2364709630 Hvsp15HghstCllSttOfChrgMdlNmr 15954;
BA_ "SPN" SG_ 2364709630 Hvsp15HghstCllSttOfChrgCllNmr 15955;
BA_ "SPN" SG_ 2364709630 Hvsp15LwstCllSttOfChrgMdlNmr 15956;
BA_ "SPN" SG_ 2364709630 Hvsp15LwstCllSttOfChrgCllNmr 15957;
BA_ "SPN" SG_ 2364709630 Hvsp15HghVltgBsAtvIsltnTstRslts 15958;
BA_ "SPN" SG_ 2364709630 Hvsp15HVtBsPssvIstTstRsts 15959;
BA_ "SPN" SG_ 2364709886 Hvsp15BsVltgNgtvTChsssGrndVltg 15960;
BA_ "SPN" SG_ 2364709886 Hvsp15VltgLvlNgtvTChsssGrndVltg 15961;
BA_ "SPN" SG_ 2364709886 Hvesp15ActualChargeRate 15962;
BA_ "SPN" SG_ 2364710142 Hvsp16DshrgPwrLmtDTSttOfChrg 15990;
BA_ "SPN" SG_ 2364710142 Hvsp16DshrgPwrLmtDTBttrTmprtr 15991;
BA_ "SPN" SG_ 2364710142 Hvsp16DsPwLtDTBttDstCdt 15992;
BA_ "SPN" SG_ 2364710142 Hvsp16DsPwLtDTBttOCVt 15993;
BA_ "SPN" SG_ 2364710142 Hvsp16DshrgPwrLmtDTBttrCrrnt 15994;
BA_ "SPN" SG_ 2364710142 Hvsp16DshrgPwrLmtDTAnUndfndCs 15995;
BA_ "SPN" SG_ 2364710142 Hvsp16ChrgPwrLmtDTSttOfChrg 15996;
BA_ "SPN" SG_ 2364710142 Hvsp16ChrgPwrLmtDTBttrTmprtr 15997;
BA_ "SPN" SG_ 2364710142 Hvsp16CPwLtDTBttDstCdt 15998;
BA_ "SPN" SG_ 2364710142 Hvsp16ChrgPwrLmtDTBttrOrCllVltg 15999;
BA_ "SPN" SG_ 2364710142 Hvsp16ChrgPwrLmtDTBttrCrrnt 16000;
BA_ "SPN" SG_ 2364710142 Hvsp16ChrgPwrLmtDTAnUndfndCs 16001;
BA_ "SPN" SG_ 2364710398 Hvesp16AvailableDischargePower 16002;
BA_ "SPN" SG_ 2364710398 Hvesp16AvailableChargePower 16003;
BA_ "SPN" SG_ 2364710398 Hvesp16VoltageLevel 16004;
BA_ "SPN" SG_ 2364710398 Hvesp16Current 16005;
BA_ "SPN" SG_ 2364710654 Hvesp16FastUpdateStateOfCharge 16006;
BA_ "SPN" SG_ 2364710654 Hvesp16HighestCellVoltage 16007;
BA_ "SPN" SG_ 2364710654 Hvesp16LowestCellVoltage 16008;
BA_ "SPN" SG_ 2364710654 Hvsp16CllVltgDffrntlStts 16009;
BA_ "SPN" SG_ 2364710910 Hvesp16HighestCellTemperature 16010;
BA_ "SPN" SG_ 2364710910 Hvesp16LowestCellTemperature 16011;
BA_ "SPN" SG_ 2364710910 Hvesp16AverageCellTemperature 16012;
BA_ "SPN" SG_ 2364710910 Hvsp16CllTmprtrDffrntlStts 16013;
BA_ "SPN" SG_ 2364711166 Hvesp16DischargeCapacity 16014;
BA_ "SPN" SG_ 2364711166 Hvesp16ChargeCapacity 16015;
BA_ "SPN" SG_ 2364711166 Hvesp16CellBalancingCount 16016;
BA_ "SPN" SG_ 2364711422 Hvesp16LowestCellStateOfCharge 16019;
BA_ "SPN" SG_ 2364711422 Hvesp16HighestCellStateOfCharge 16020;
BA_ "SPN" SG_ 2364711422 Hvsp16MxmmInstntnsDshrgCrrntLmt 16017;
BA_ "SPN" SG_ 2364711422 Hvsp16MxmmInstntnsChrgCrrntLmt 16018;
BA_ "SPN" SG_ 2364711678 Hvesp16BusVoltage 16021;
BA_ "SPN" SG_ 2364711678 Hvesp16IgnitionVoltage 16022;
BA_ "SPN" SG_ 2364711678 Hvesp16IntakeCoolantTemperature 16023;
BA_ "SPN" SG_ 2364711678 Hvesp16OutletCoolantTemperature 16024;
BA_ "SPN" SG_ 2364711678 Hvesp16ElectronicsTemperature 16025;
BA_ "SPN" SG_ 2364711678 Hvesp16Temperature 16026;
BA_ "SPN" SG_ 2364711934 Hvsp16HghVltgBsPstvCnttrStt 16027;
BA_ "SPN" SG_ 2364711934 Hvsp16HghVltgBsNgtvCnttrStt 16028;
BA_ "SPN" SG_ 2364711934 Hvsp16HghVltgBsDsnntFrwrnng 16029;
BA_ "SPN" SG_ 2364711934 Hvsp16HghVltgBsPrChrgRlStt 16030;
BA_ "SPN" SG_ 2364711934 Hvsp16CntrOfPkCnttrStt 16031;
BA_ "SPN" SG_ 2364711934 Hvsp16HghVltgBsAtvIsltnTstStts 16032;
BA_ "SPN" SG_ 2364711934 Hvsp16HghVltgBsPssvIsltnTstStts 16033;
BA_ "SPN" SG_ 2364711934 Hvesp16HvilStatus 16034;
BA_ "SPN" SG_ 2364711934 Hvesp16InertiaSwitchStatus 16035;
BA_ "SPN" SG_ 2364711934 Hvesp16StateOfChargeStatus 16036;
BA_ "SPN" SG_ 2364711934 Hvesp16CellBalanceStatus 16037;
BA_ "SPN" SG_ 2364711934 Hvesp16CellBalancingActive 16038;
BA_ "SPN" SG_ 2364711934 Hvesp16InternalChargerStatus 16039;
BA_ "SPN" SG_ 2364711934 Hvsp16HghVltgBsCnntnStts 16040;
BA_ "SPN" SG_ 2364711934 Hvesp16OperationalStatus 16041;
BA_ "SPN" SG_ 2364711934 Hvesp16Status1Counter 16042;
BA_ "SPN" SG_ 2364711934 Hvesp16Status1Crc 16043;
BA_ "SPN" SG_ 2364712190 Hvesp16DischargeEnergyCapacity 16044;
BA_ "SPN" SG_ 2364712190 Hvesp16ChargeEnergyCapacity 16045;
BA_ "SPN" SG_ 2364712190 Hvsp16MxmmChrgVltgLmt 16046;
BA_ "SPN" SG_ 2364712446 Hvesp16Module1OperationalStatus 16047;
BA_ "SPN" SG_ 2364712446 Hvesp16Module2OperationalStatus 16048;
BA_ "SPN" SG_ 2364712446 Hvesp16Module3OperationalStatus 16049;
BA_ "SPN" SG_ 2364712446 Hvesp16Module4OperationalStatus 16050;
BA_ "SPN" SG_ 2364712446 Hvesp16Module5OperationalStatus 16051;
BA_ "SPN" SG_ 2364712446 Hvesp16Module6OperationalStatus 16052;
BA_ "SPN" SG_ 2364712446 Hvesp16Module7OperationalStatus 16053;
BA_ "SPN" SG_ 2364712446 Hvesp16Module8OperationalStatus 16054;
BA_ "SPN" SG_ 2364712446 Hvesp16Module9OperationalStatus 16055;
BA_ "SPN" SG_ 2364712446 Hvsp16Mdl10OprtnlStts 16056;
BA_ "SPN" SG_ 2364712446 Hvsp16Mdl11OprtnlStts 16057;
BA_ "SPN" SG_ 2364712446 Hvsp16Mdl12OprtnlStts 16058;
BA_ "SPN" SG_ 2364712446 Hvsp16Mdl13OprtnlStts 16059;
BA_ "SPN" SG_ 2364712446 Hvsp16Mdl14OprtnlStts 16060;
BA_ "SPN" SG_ 2364712446 Hvsp16Mdl15OprtnlStts 16061;
BA_ "SPN" SG_ 2364712446 Hvsp16Mdl16OprtnlStts 16062;
BA_ "SPN" SG_ 2364712446 Hvsp16Mdl17OprtnlStts 16063;
BA_ "SPN" SG_ 2364712446 Hvsp16Mdl18OprtnlStts 16064;
BA_ "SPN" SG_ 2364712446 Hvsp16Mdl19OprtnlStts 16065;
BA_ "SPN" SG_ 2364712446 Hvsp16Mdl20OprtnlStts 16066;
BA_ "SPN" SG_ 2364712446 Hvsp16Mdl21OprtnlStts 16067;
BA_ "SPN" SG_ 2364712446 Hvsp16Mdl22OprtnlStts 16068;
BA_ "SPN" SG_ 2364712446 Hvsp16Mdl23OprtnlStts 16069;
BA_ "SPN" SG_ 2364712446 Hvsp16Mdl24OprtnlStts 16070;
BA_ "SPN" SG_ 2364712446 Hvsp16Mdl25OprtnlStts 16071;
BA_ "SPN" SG_ 2364712446 Hvsp16Mdl26OprtnlStts 16072;
BA_ "SPN" SG_ 2364712446 Hvsp16Mdl27OprtnlStts 16073;
BA_ "SPN" SG_ 2364712446 Hvsp16Mdl28OprtnlStts 16074;
BA_ "SPN" SG_ 2364712446 Hvsp16Mdl29OprtnlStts 16075;
BA_ "SPN" SG_ 2364712446 Hvsp16Mdl30OprtnlStts 16076;
BA_ "SPN" SG_ 2364712446 Hvsp16Mdl31OprtnlStts 16077;
BA_ "SPN" SG_ 2364712446 Hvsp16Mdl32OprtnlStts 16078;
BA_ "SPN" SG_ 2364712702 Hvsp16ThrmlMngmntSstmSlInptPwr 16079;
BA_ "SPN" SG_ 2364712702 Hvsp16TMtSstHVtIptPw 16080;
BA_ "SPN" SG_ 2364712702 Hvsp16ThrmlMngmntSstmCmprssrSpd 16081;
BA_ "SPN" SG_ 2364712702 Hvsp16ThrmlMngmntSstmRltvHmdt 16082;
BA_ "SPN" SG_ 2364712702 Hvsp16ThrmlMngmntSstmHtrStts 16083;
BA_ "SPN" SG_ 2364712702 Hvsp16ThrmlMngmntSstmHvlStts 16084;
BA_ "SPN" SG_ 2364712702 Hvsp16ThrmlMngmntSstmMd 16085;
BA_ "SPN" SG_ 2364712702 Hvsp16ThrmlMngmntSstmClntLvl 16086;
BA_ "SPN" SG_ 2364712958 Hvsp16HghstCllVltgMdlNmr 16087;
BA_ "SPN" SG_ 2364712958 Hvsp16HghstCllVltgCllNmr 16088;
BA_ "SPN" SG_ 2364712958 Hvsp16LwstCllVltgMdlNmr 16089;
BA_ "SPN" SG_ 2364712958 Hvsp16LwstCllVltgCllNmr 16090;
BA_ "SPN" SG_ 2364712958 Hvesp16AverageCellVoltage 16091;
BA_ "SPN" SG_ 2364713214 Hvsp16HghstCllTmprtrMdlNmr 16092;
BA_ "SPN" SG_ 2364713214 Hvsp16HghstCllTmprtrCllNmr 16093;
BA_ "SPN" SG_ 2364713214 Hvsp16LwstCllTmprtrMdlNmr 16094;
BA_ "SPN" SG_ 2364713214 Hvsp16LwstCllTmprtrCllNmr 16095;
BA_ "SPN" SG_ 2364713214 Hvess16ThermalEventDetected 21303;
BA_ "SPN" SG_ 2364713214 Hvsp16Dt9EmdddIntgrtSpprt 23019;
BA_ "SPN" SG_ 2364713214 Hvesp16Data9Counter 23020;
BA_ "SPN" SG_ 2364713214 Hvesp16Data9Crc 23021;
BA_ "SPN" SG_ 2364713470 Hvsp16HghstCllSttOfChrgMdlNmr 16096;
BA_ "SPN" SG_ 2364713470 Hvsp16HghstCllSttOfChrgCllNmr 16097;
BA_ "SPN" SG_ 2364713470 Hvsp16LwstCllSttOfChrgMdlNmr 16098;
BA_ "SPN" SG_ 2364713470 Hvsp16LwstCllSttOfChrgCllNmr 16099;
BA_ "SPN" SG_ 2364713470 Hvsp16HghVltgBsAtvIsltnTstRslts 16100;
BA_ "SPN" SG_ 2364713470 Hvsp16HVtBsPssvIstTstRsts 16101;
BA_ "SPN" SG_ 2364713726 Hvsp16BsVltgNgtvTChsssGrndVltg 16102;
BA_ "SPN" SG_ 2364713726 Hvsp16VltgLvlNgtvTChsssGrndVltg 16103;
BA_ "SPN" SG_ 2364713726 Hvesp16ActualChargeRate 16104;
BA_ "SPN" SG_ 2364713982 Hvsp17DshrgPwrLmtDTSttOfChrg 16132;
BA_ "SPN" SG_ 2364713982 Hvsp17DshrgPwrLmtDTBttrTmprtr 16133;
BA_ "SPN" SG_ 2364713982 Hvsp17DsPwLtDTBttDstCdt 16134;
BA_ "SPN" SG_ 2364713982 Hvsp17DsPwLtDTBttOCVt 16135;
BA_ "SPN" SG_ 2364713982 Hvsp17DshrgPwrLmtDTBttrCrrnt 16136;
BA_ "SPN" SG_ 2364713982 Hvsp17DshrgPwrLmtDTAnUndfndCs 16137;
BA_ "SPN" SG_ 2364713982 Hvsp17ChrgPwrLmtDTSttOfChrg 16138;
BA_ "SPN" SG_ 2364713982 Hvsp17ChrgPwrLmtDTBttrTmprtr 16139;
BA_ "SPN" SG_ 2364713982 Hvsp17CPwLtDTBttDstCdt 16140;
BA_ "SPN" SG_ 2364713982 Hvsp17ChrgPwrLmtDTBttrOrCllVltg 16141;
BA_ "SPN" SG_ 2364713982 Hvsp17ChrgPwrLmtDTBttrCrrnt 16142;
BA_ "SPN" SG_ 2364713982 Hvsp17ChrgPwrLmtDTAnUndfndCs 16143;
BA_ "SPN" SG_ 2364714238 Hvesp17AvailableDischargePower 16144;
BA_ "SPN" SG_ 2364714238 Hvesp17AvailableChargePower 16145;
BA_ "SPN" SG_ 2364714238 Hvesp17VoltageLevel 16146;
BA_ "SPN" SG_ 2364714238 Hvesp17Current 16147;
BA_ "SPN" SG_ 2364714494 Hvesp17FastUpdateStateOfCharge 16148;
BA_ "SPN" SG_ 2364714494 Hvesp17HighestCellVoltage 16149;
BA_ "SPN" SG_ 2364714494 Hvesp17LowestCellVoltage 16150;
BA_ "SPN" SG_ 2364714494 Hvsp17CllVltgDffrntlStts 16151;
BA_ "SPN" SG_ 2364714750 Hvesp17HighestCellTemperature 16152;
BA_ "SPN" SG_ 2364714750 Hvesp17LowestCellTemperature 16153;
BA_ "SPN" SG_ 2364714750 Hvesp17AverageCellTemperature 16154;
BA_ "SPN" SG_ 2364714750 Hvsp17CllTmprtrDffrntlStts 16155;
BA_ "SPN" SG_ 2364715006 Hvesp17DischargeCapacity 16156;
BA_ "SPN" SG_ 2364715006 Hvesp17ChargeCapacity 16157;
BA_ "SPN" SG_ 2364715006 Hvesp17CellBalancingCount 16158;
BA_ "SPN" SG_ 2364715262 Hvesp17LowestCellStateOfCharge 16161;
BA_ "SPN" SG_ 2364715262 Hvesp17HighestCellStateOfCharge 16162;
BA_ "SPN" SG_ 2364715262 Hvsp17MxmmInstntnsDshrgCrrntLmt 16159;
BA_ "SPN" SG_ 2364715262 Hvsp17MxmmInstntnsChrgCrrntLmt 16160;
BA_ "SPN" SG_ 2364715518 Hvesp17BusVoltage 16163;
BA_ "SPN" SG_ 2364715518 Hvesp17IgnitionVoltage 16164;
BA_ "SPN" SG_ 2364715518 Hvesp17IntakeCoolantTemperature 16165;
BA_ "SPN" SG_ 2364715518 Hvesp17OutletCoolantTemperature 16166;
BA_ "SPN" SG_ 2364715518 Hvesp17ElectronicsTemperature 16167;
BA_ "SPN" SG_ 2364715518 Hvesp17Temperature 16168;
BA_ "SPN" SG_ 2364715774 Hvsp17HghVltgBsPstvCnttrStt 16169;
BA_ "SPN" SG_ 2364715774 Hvsp17HghVltgBsNgtvCnttrStt 16170;
BA_ "SPN" SG_ 2364715774 Hvsp17HghVltgBsDsnntFrwrnng 16171;
BA_ "SPN" SG_ 2364715774 Hvsp17HghVltgBsPrChrgRlStt 16172;
BA_ "SPN" SG_ 2364715774 Hvsp17CntrOfPkCnttrStt 16173;
BA_ "SPN" SG_ 2364715774 Hvsp17HghVltgBsAtvIsltnTstStts 16174;
BA_ "SPN" SG_ 2364715774 Hvsp17HghVltgBsPssvIsltnTstStts 16175;
BA_ "SPN" SG_ 2364715774 Hvesp17HvilStatus 16176;
BA_ "SPN" SG_ 2364715774 Hvesp17InertiaSwitchStatus 16177;
BA_ "SPN" SG_ 2364715774 Hvesp17StateOfChargeStatus 16178;
BA_ "SPN" SG_ 2364715774 Hvesp17CellBalanceStatus 16179;
BA_ "SPN" SG_ 2364715774 Hvesp17CellBalancingActive 16180;
BA_ "SPN" SG_ 2364715774 Hvesp17InternalChargerStatus 16181;
BA_ "SPN" SG_ 2364715774 Hvsp17HghVltgBsCnntnStts 16182;
BA_ "SPN" SG_ 2364715774 Hvesp17OperationalStatus 16183;
BA_ "SPN" SG_ 2364715774 Hvesp17Status1Counter 16184;
BA_ "SPN" SG_ 2364715774 Hvesp17Status1Crc 16185;
BA_ "SPN" SG_ 2364716030 Hvesp17DischargeEnergyCapacity 16186;
BA_ "SPN" SG_ 2364716030 Hvesp17ChargeEnergyCapacity 16187;
BA_ "SPN" SG_ 2364716030 Hvsp17MxmmChrgVltgLmt 16188;
BA_ "SPN" SG_ 2364716286 Hvesp17Module1OperationalStatus 16189;
BA_ "SPN" SG_ 2364716286 Hvesp17Module2OperationalStatus 16190;
BA_ "SPN" SG_ 2364716286 Hvesp17Module3OperationalStatus 16191;
BA_ "SPN" SG_ 2364716286 Hvesp17Module4OperationalStatus 16192;
BA_ "SPN" SG_ 2364716286 Hvesp17Module5OperationalStatus 16193;
BA_ "SPN" SG_ 2364716286 Hvesp17Module6OperationalStatus 16194;
BA_ "SPN" SG_ 2364716286 Hvesp17Module7OperationalStatus 16195;
BA_ "SPN" SG_ 2364716286 Hvesp17Module8OperationalStatus 16196;
BA_ "SPN" SG_ 2364716286 Hvesp17Module9OperationalStatus 16197;
BA_ "SPN" SG_ 2364716286 Hvsp17Mdl10OprtnlStts 16198;
BA_ "SPN" SG_ 2364716286 Hvsp17Mdl11OprtnlStts 16199;
BA_ "SPN" SG_ 2364716286 Hvsp17Mdl12OprtnlStts 16200;
BA_ "SPN" SG_ 2364716286 Hvsp17Mdl13OprtnlStts 16201;
BA_ "SPN" SG_ 2364716286 Hvsp17Mdl14OprtnlStts 16202;
BA_ "SPN" SG_ 2364716286 Hvsp17Mdl15OprtnlStts 16203;
BA_ "SPN" SG_ 2364716286 Hvsp17Mdl16OprtnlStts 16204;
BA_ "SPN" SG_ 2364716286 Hvsp17Mdl17OprtnlStts 16205;
BA_ "SPN" SG_ 2364716286 Hvsp17Mdl18OprtnlStts 16206;
BA_ "SPN" SG_ 2364716286 Hvsp17Mdl19OprtnlStts 16207;
BA_ "SPN" SG_ 2364716286 Hvsp17Mdl20OprtnlStts 16208;
BA_ "SPN" SG_ 2364716286 Hvsp17Mdl21OprtnlStts 16209;
BA_ "SPN" SG_ 2364716286 Hvsp17Mdl22OprtnlStts 16210;
BA_ "SPN" SG_ 2364716286 Hvsp17Mdl23OprtnlStts 16211;
BA_ "SPN" SG_ 2364716286 Hvsp17Mdl24OprtnlStts 16212;
BA_ "SPN" SG_ 2364716286 Hvsp17Mdl25OprtnlStts 16213;
BA_ "SPN" SG_ 2364716286 Hvsp17Mdl26OprtnlStts 16214;
BA_ "SPN" SG_ 2364716286 Hvsp17Mdl27OprtnlStts 16215;
BA_ "SPN" SG_ 2364716286 Hvsp17Mdl28OprtnlStts 16216;
BA_ "SPN" SG_ 2364716286 Hvsp17Mdl29OprtnlStts 16217;
BA_ "SPN" SG_ 2364716286 Hvsp17Mdl30OprtnlStts 16218;
BA_ "SPN" SG_ 2364716286 Hvsp17Mdl31OprtnlStts 16219;
BA_ "SPN" SG_ 2364716286 Hvsp17Mdl32OprtnlStts 16220;
BA_ "SPN" SG_ 2364716542 Hvsp17ThrmlMngmntSstmSlInptPwr 16221;
BA_ "SPN" SG_ 2364716542 Hvsp17TMtSstHVtIptPw 16222;
BA_ "SPN" SG_ 2364716542 Hvsp17ThrmlMngmntSstmCmprssrSpd 16223;
BA_ "SPN" SG_ 2364716542 Hvsp17ThrmlMngmntSstmRltvHmdt 16224;
BA_ "SPN" SG_ 2364716542 Hvsp17ThrmlMngmntSstmHtrStts 16225;
BA_ "SPN" SG_ 2364716542 Hvsp17ThrmlMngmntSstmHvlStts 16226;
BA_ "SPN" SG_ 2364716542 Hvsp17ThrmlMngmntSstmMd 16227;
BA_ "SPN" SG_ 2364716542 Hvsp17ThrmlMngmntSstmClntLvl 16228;
BA_ "SPN" SG_ 2364716798 Hvsp17HghstCllVltgMdlNmr 16229;
BA_ "SPN" SG_ 2364716798 Hvsp17HghstCllVltgCllNmr 16230;
BA_ "SPN" SG_ 2364716798 Hvsp17LwstCllVltgMdlNmr 16231;
BA_ "SPN" SG_ 2364716798 Hvsp17LwstCllVltgCllNmr 16232;
BA_ "SPN" SG_ 2364716798 Hvesp17AverageCellVoltage 16233;
BA_ "SPN" SG_ 2364717054 Hvsp17HghstCllTmprtrMdlNmr 16234;
BA_ "SPN" SG_ 2364717054 Hvsp17HghstCllTmprtrCllNmr 16235;
BA_ "SPN" SG_ 2364717054 Hvsp17LwstCllTmprtrMdlNmr 16236;
BA_ "SPN" SG_ 2364717054 Hvsp17LwstCllTmprtrCllNmr 16237;
BA_ "SPN" SG_ 2364717054 Hvess17ThermalEventDetected 21304;
BA_ "SPN" SG_ 2364717054 Hvsp17Dt9EmdddIntgrtSpprt 23022;
BA_ "SPN" SG_ 2364717054 Hvesp17Data9Counter 23023;
BA_ "SPN" SG_ 2364717054 Hvesp17Data9Crc 23024;
BA_ "SPN" SG_ 2364717310 Hvsp17HghstCllSttOfChrgMdlNmr 16238;
BA_ "SPN" SG_ 2364717310 Hvsp17HghstCllSttOfChrgCllNmr 16239;
BA_ "SPN" SG_ 2364717310 Hvsp17LwstCllSttOfChrgMdlNmr 16240;
BA_ "SPN" SG_ 2364717310 Hvsp17LwstCllSttOfChrgCllNmr 16241;
BA_ "SPN" SG_ 2364717310 Hvsp17HghVltgBsAtvIsltnTstRslts 16242;
BA_ "SPN" SG_ 2364717310 Hvsp17HVtBsPssvIstTstRsts 16243;
BA_ "SPN" SG_ 2364717566 Hvsp17BsVltgNgtvTChsssGrndVltg 16244;
BA_ "SPN" SG_ 2364717566 Hvsp17VltgLvlNgtvTChsssGrndVltg 16245;
BA_ "SPN" SG_ 2364717566 Hvesp17ActualChargeRate 16246;
BA_ "SPN" SG_ 2364717822 Hvsp18DshrgPwrLmtDTSttOfChrg 16274;
BA_ "SPN" SG_ 2364717822 Hvsp18DshrgPwrLmtDTBttrTmprtr 16275;
BA_ "SPN" SG_ 2364717822 Hvsp18DsPwLtDTBttDstCdt 16276;
BA_ "SPN" SG_ 2364717822 Hvsp18DsPwLtDTBttOCVt 16277;
BA_ "SPN" SG_ 2364717822 Hvsp18DshrgPwrLmtDTBttrCrrnt 16278;
BA_ "SPN" SG_ 2364717822 Hvsp18DshrgPwrLmtDTAnUndfndCs 16279;
BA_ "SPN" SG_ 2364717822 Hvsp18ChrgPwrLmtDTSttOfChrg 16280;
BA_ "SPN" SG_ 2364717822 Hvsp18ChrgPwrLmtDTBttrTmprtr 16281;
BA_ "SPN" SG_ 2364717822 Hvsp18CPwLtDTBttDstCdt 16282;
BA_ "SPN" SG_ 2364717822 Hvsp18ChrgPwrLmtDTBttrOrCllVltg 16283;
BA_ "SPN" SG_ 2364717822 Hvsp18ChrgPwrLmtDTBttrCrrnt 16284;
BA_ "SPN" SG_ 2364717822 Hvsp18ChrgPwrLmtDTAnUndfndCs 16285;
BA_ "SPN" SG_ 2364718078 Hvesp18AvailableDischargePower 16286;
BA_ "SPN" SG_ 2364718078 Hvesp18AvailableChargePower 16287;
BA_ "SPN" SG_ 2364718078 Hvesp18VoltageLevel 16288;
BA_ "SPN" SG_ 2364718078 Hvesp18Current 16289;
BA_ "SPN" SG_ 2364718334 Hvesp18FastUpdateStateOfCharge 16290;
BA_ "SPN" SG_ 2364718334 Hvesp18HighestCellVoltage 16291;
BA_ "SPN" SG_ 2364718334 Hvesp18LowestCellVoltage 16292;
BA_ "SPN" SG_ 2364718334 Hvsp18CllVltgDffrntlStts 16293;
